VERSION ""

NS_ :

BS_:

BU_: OBC ICM HCU CLM ABM BMS Tester

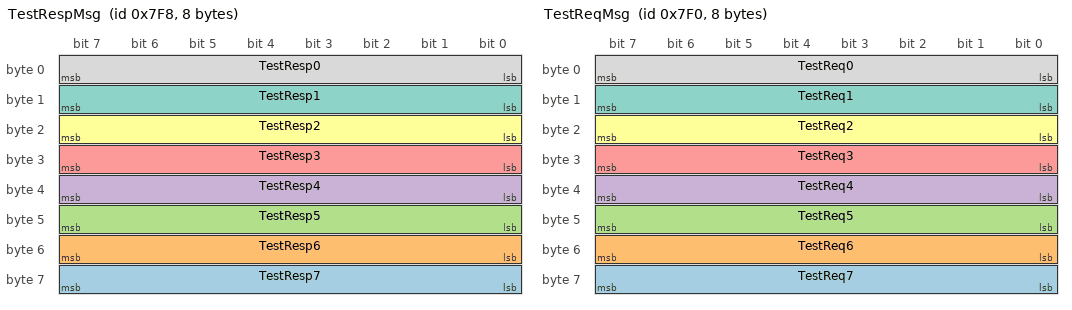
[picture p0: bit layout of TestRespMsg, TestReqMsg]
BO_ 2040 TestRespMsg: 8 BMS
 SG_ TestResp7 : 63|8@0+ (1,0) [0|0] ""  Tester
 SG_ TestResp6 : 55|8@0+ (1,0) [0|0] ""  Tester
 SG_ TestResp5 : 47|8@0+ (1,0) [0|0] ""  Tester
 SG_ TestResp4 : 39|8@0+ (1,0) [0|0] ""  Tester
 SG_ TestResp3 : 31|8@0+ (1,0) [0|0] ""  Tester
 SG_ TestResp2 : 23|8@0+ (1,0) [0|0] ""  Tester
 SG_ TestResp1 : 15|8@0+ (1,0) [0|0] ""  Tester
 SG_ TestResp0 : 7|8@0+ (1,0) [0|0] ""  Tester

BO_ 2032 TestReqMsg: 8 Tester
 SG_ TestReq7 : 63|8@0+ (1,0) [0|0] ""  BMS
 SG_ TestReq6 : 55|8@0+ (1,0) [0|0] ""  BMS
 SG_ TestReq5 : 47|8@0+ (1,0) [0|0] ""  BMS
 SG_ TestReq4 : 39|8@0+ (1,0) [0|0] ""  BMS
 SG_ TestReq3 : 31|8@0+ (1,0) [0|0] ""  BMS
 SG_ TestReq2 : 23|8@0+ (1,0) [0|0] ""  BMS
 SG_ TestReq1 : 15|8@0+ (1,0) [0|0] ""  BMS
 SG_ TestReq0 : 7|8@0+ (1,0) [0|0] ""  BMS

BO_ 1072 ICM_1: 8 Vector__XXX
 SG_ TotalOdometer_km : 43|20@0+ (1,0) [0|999999] "km"  BMS
 SG_ BatteryVoltage : 23|8@0+ (0.1,0) [0|25.4] "V"  BMS

BO_ 800 ABM_1: 4 Vector__XXX
 SG_ CrashOutputSts : 31|8@0+ (1,0) [0|255] ""  BMS
 SG_ ABM_1_CheckSum : 23|8@0+ (1,0) [0|255] ""  BMS
 SG_ ABM_1_MessageCounter : 15|4@0+ (1,0) [0|15] ""  BMS

BO_ 1333 CLM_2: 8 Vector__XXX
 SG_ ExternalTemperatureRaw_C : 55|8@0+ (0.5,-40) [-40|85] "C"  BMS
 SG_ ExternalTemperatureFailSts_GS : 33|2@0+ (1,0) [0|3] ""  BMS

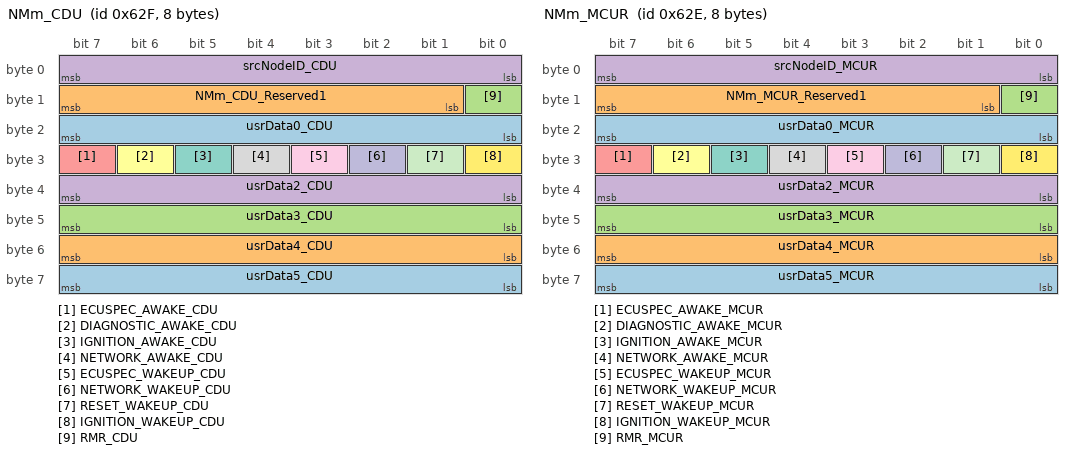
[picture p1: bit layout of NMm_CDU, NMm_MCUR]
BO_ 1583 NMm_CDU: 8 Vector__XXX
 SG_ usrData5_CDU : 63|8@0+ (1,0) [0|255] ""  BMS
 SG_ usrData4_CDU : 55|8@0+ (1,0) [0|255] ""  BMS
 SG_ usrData3_CDU : 47|8@0+ (1,0) [0|255] ""  BMS
 SG_ usrData2_CDU : 39|8@0+ (1,0) [0|255] ""  BMS
 SG_ ECUSPEC_AWAKE_CDU : 31|1@0+ (1,0) [0|1] ""  BMS
 SG_ DIAGNOSTIC_AWAKE_CDU : 30|1@0+ (1,0) [0|1] ""  BMS
 SG_ IGNITION_AWAKE_CDU : 29|1@0+ (1,0) [0|1] ""  BMS
 SG_ NETWORK_AWAKE_CDU : 28|1@0+ (1,0) [0|1] ""  BMS
 SG_ ECUSPEC_WAKEUP_CDU : 27|1@0+ (1,0) [0|1] ""  BMS
 SG_ NETWORK_WAKEUP_CDU : 26|1@0+ (1,0) [0|1] ""  BMS
 SG_ RESET_WAKEUP_CDU : 25|1@0+ (1,0) [0|1] ""  BMS
 SG_ IGNITION_WAKEUP_CDU : 24|1@0+ (1,0) [0|1] ""  BMS
 SG_ usrData0_CDU : 23|8@0+ (1,0) [0|255] ""  BMS
 SG_ NMm_CDU_Reserved1 : 15|7@0+ (1,0) [0|127] ""  BMS
 SG_ RMR_CDU : 8|1@0+ (1,0) [0|1] ""  BMS
 SG_ srcNodeID_CDU : 7|8@0+ (1,0) [0|255] ""  BMS

BO_ 1582 NMm_MCUR: 8 Vector__XXX
 SG_ usrData5_MCUR : 63|8@0+ (1,0) [0|255] ""  BMS
 SG_ usrData4_MCUR : 55|8@0+ (1,0) [0|255] ""  BMS
 SG_ usrData3_MCUR : 47|8@0+ (1,0) [0|255] ""  BMS
 SG_ usrData2_MCUR : 39|8@0+ (1,0) [0|255] ""  BMS
 SG_ ECUSPEC_AWAKE_MCUR : 31|1@0+ (1,0) [0|1] ""  BMS
 SG_ DIAGNOSTIC_AWAKE_MCUR : 30|1@0+ (1,0) [0|1] ""  BMS
 SG_ IGNITION_AWAKE_MCUR : 29|1@0+ (1,0) [0|1] ""  BMS
 SG_ NETWORK_AWAKE_MCUR : 28|1@0+ (1,0) [0|1] ""  BMS
 SG_ ECUSPEC_WAKEUP_MCUR : 27|1@0+ (1,0) [0|1] ""  BMS
 SG_ NETWORK_WAKEUP_MCUR : 26|1@0+ (1,0) [0|1] ""  BMS
 SG_ RESET_WAKEUP_MCUR : 25|1@0+ (1,0) [0|1] ""  BMS
 SG_ IGNITION_WAKEUP_MCUR : 24|1@0+ (1,0) [0|1] ""  BMS
 SG_ usrData0_MCUR : 23|8@0+ (1,0) [0|255] ""  BMS
 SG_ NMm_MCUR_Reserved1 : 15|7@0+ (1,0) [0|127] ""  BMS
 SG_ RMR_MCUR : 8|1@0+ (1,0) [0|1] ""  BMS
 SG_ srcNodeID_MCUR : 7|8@0+ (1,0) [0|255] ""  BMS

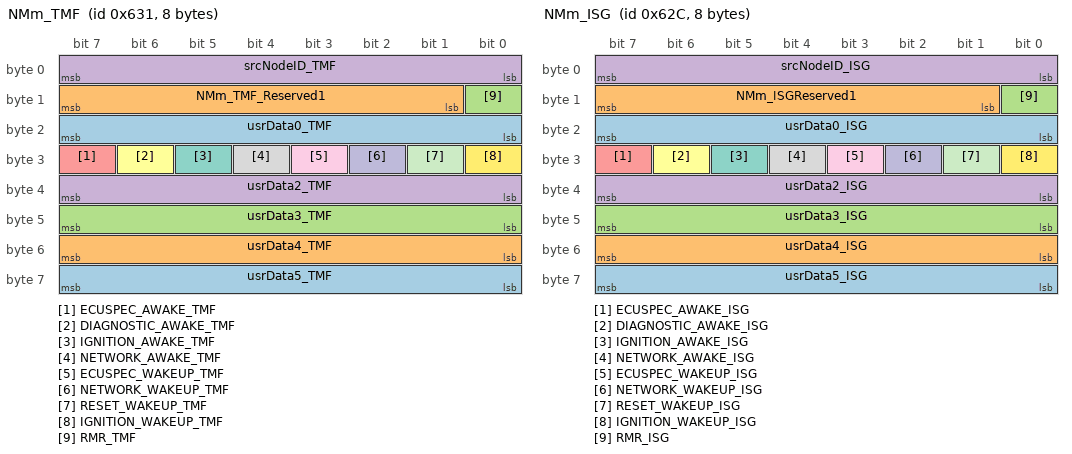
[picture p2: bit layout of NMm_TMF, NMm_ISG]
BO_ 1585 NMm_TMF: 8 Vector__XXX
 SG_ usrData5_TMF : 63|8@0+ (1,0) [0|255] ""  BMS
 SG_ usrData4_TMF : 55|8@0+ (1,0) [0|255] ""  BMS
 SG_ usrData3_TMF : 47|8@0+ (1,0) [0|255] ""  BMS
 SG_ usrData2_TMF : 39|8@0+ (1,0) [0|255] ""  BMS
 SG_ ECUSPEC_AWAKE_TMF : 31|1@0+ (1,0) [0|1] ""  BMS
 SG_ DIAGNOSTIC_AWAKE_TMF : 30|1@0+ (1,0) [0|1] ""  BMS
 SG_ IGNITION_AWAKE_TMF : 29|1@0+ (1,0) [0|1] ""  BMS
 SG_ NETWORK_AWAKE_TMF : 28|1@0+ (1,0) [0|1] ""  BMS
 SG_ ECUSPEC_WAKEUP_TMF : 27|1@0+ (1,0) [0|1] ""  BMS
 SG_ NETWORK_WAKEUP_TMF : 26|1@0+ (1,0) [0|1] ""  BMS
 SG_ RESET_WAKEUP_TMF : 25|1@0+ (1,0) [0|1] ""  BMS
 SG_ IGNITION_WAKEUP_TMF : 24|1@0+ (1,0) [0|1] ""  BMS
 SG_ usrData0_TMF : 23|8@0+ (1,0) [0|255] ""  BMS
 SG_ NMm_TMF_Reserved1 : 15|7@0+ (1,0) [0|127] ""  BMS
 SG_ RMR_TMF : 8|1@0+ (1,0) [0|1] ""  BMS
 SG_ srcNodeID_TMF : 7|8@0+ (1,0) [0|255] ""  BMS

BO_ 1580 NMm_ISG: 8 Vector__XXX
 SG_ usrData5_ISG : 63|8@0+ (1,0) [0|255] ""  BMS
 SG_ usrData4_ISG : 55|8@0+ (1,0) [0|255] ""  BMS
 SG_ usrData3_ISG : 47|8@0+ (1,0) [0|255] ""  BMS
 SG_ usrData2_ISG : 39|8@0+ (1,0) [0|255] ""  BMS
 SG_ ECUSPEC_AWAKE_ISG : 31|1@0+ (1,0) [0|1] ""  BMS
 SG_ DIAGNOSTIC_AWAKE_ISG : 30|1@0+ (1,0) [0|1] ""  BMS
 SG_ IGNITION_AWAKE_ISG : 29|1@0+ (1,0) [0|1] ""  BMS
 SG_ NETWORK_AWAKE_ISG : 28|1@0+ (1,0) [0|1] ""  BMS
 SG_ ECUSPEC_WAKEUP_ISG : 27|1@0+ (1,0) [0|1] ""  BMS
 SG_ NETWORK_WAKEUP_ISG : 26|1@0+ (1,0) [0|1] ""  BMS
 SG_ RESET_WAKEUP_ISG : 25|1@0+ (1,0) [0|1] ""  BMS
 SG_ IGNITION_WAKEUP_ISG : 24|1@0+ (1,0) [0|1] ""  BMS
 SG_ usrData0_ISG : 23|8@0+ (1,0) [0|255] ""  BMS
 SG_ NMm_ISGReserved1 : 15|7@0+ (1,0) [0|127] ""  BMS
 SG_ RMR_ISG : 8|1@0+ (1,0) [0|1] ""  BMS
 SG_ srcNodeID_ISG : 7|8@0+ (1,0) [0|255] ""  BMS

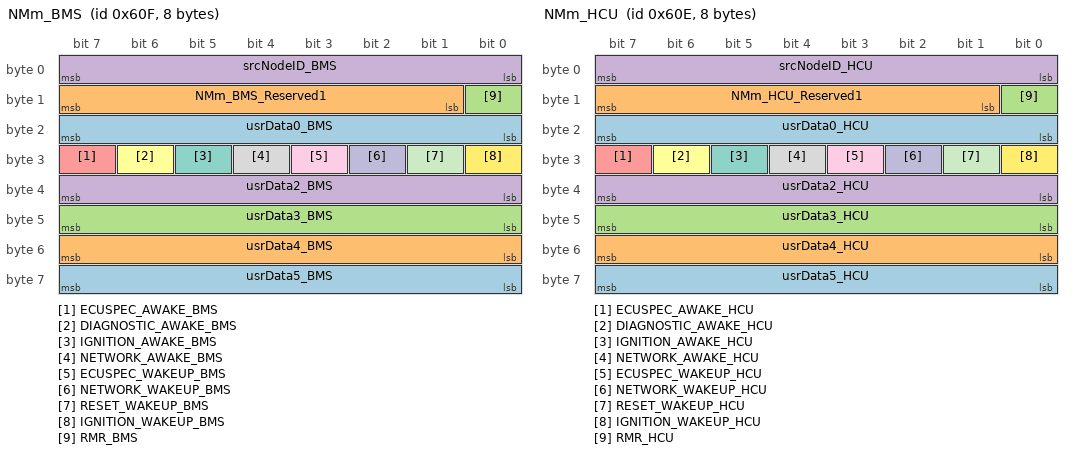
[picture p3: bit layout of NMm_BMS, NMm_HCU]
BO_ 1551 NMm_BMS: 8 BMS
 SG_ usrData5_BMS : 63|8@0+ (1,0) [0|255] "" Vector__XXX
 SG_ usrData4_BMS : 55|8@0+ (1,0) [0|255] "" Vector__XXX
 SG_ usrData3_BMS : 47|8@0+ (1,0) [0|255] "" Vector__XXX
 SG_ usrData2_BMS : 39|8@0+ (1,0) [0|255] "" Vector__XXX
 SG_ ECUSPEC_AWAKE_BMS : 31|1@0+ (1,0) [0|1] "" Vector__XXX
 SG_ DIAGNOSTIC_AWAKE_BMS : 30|1@0+ (1,0) [0|1] "" Vector__XXX
 SG_ IGNITION_AWAKE_BMS : 29|1@0+ (1,0) [0|1] "" Vector__XXX
 SG_ NETWORK_AWAKE_BMS : 28|1@0+ (1,0) [0|1] "" Vector__XXX
 SG_ ECUSPEC_WAKEUP_BMS : 27|1@0+ (1,0) [0|1] "" Vector__XXX
 SG_ NETWORK_WAKEUP_BMS : 26|1@0+ (1,0) [0|1] "" Vector__XXX
 SG_ RESET_WAKEUP_BMS : 25|1@0+ (1,0) [0|1] "" Vector__XXX
 SG_ IGNITION_WAKEUP_BMS : 24|1@0+ (1,0) [0|1] "" Vector__XXX
 SG_ usrData0_BMS : 23|8@0+ (1,0) [0|255] "" Vector__XXX
 SG_ NMm_BMS_Reserved1 : 15|7@0+ (1,0) [0|127] "" Vector__XXX
 SG_ RMR_BMS : 8|1@0+ (1,0) [0|1] "" Vector__XXX
 SG_ srcNodeID_BMS : 7|8@0+ (1,0) [0|255] "" Vector__XXX

BO_ 1550 NMm_HCU: 8 Vector__XXX
 SG_ usrData5_HCU : 63|8@0+ (1,0) [0|255] ""  BMS
 SG_ usrData4_HCU : 55|8@0+ (1,0) [0|255] ""  BMS
 SG_ usrData3_HCU : 47|8@0+ (1,0) [0|255] ""  BMS
 SG_ usrData2_HCU : 39|8@0+ (1,0) [0|255] ""  BMS
 SG_ ECUSPEC_AWAKE_HCU : 31|1@0+ (1,0) [0|1] ""  BMS
 SG_ DIAGNOSTIC_AWAKE_HCU : 30|1@0+ (1,0) [0|1] ""  BMS
 SG_ IGNITION_AWAKE_HCU : 29|1@0+ (1,0) [0|1] ""  BMS
 SG_ NETWORK_AWAKE_HCU : 28|1@0+ (1,0) [0|1] ""  BMS
 SG_ ECUSPEC_WAKEUP_HCU : 27|1@0+ (1,0) [0|1] ""  BMS
 SG_ NETWORK_WAKEUP_HCU : 26|1@0+ (1,0) [0|1] ""  BMS
 SG_ RESET_WAKEUP_HCU : 25|1@0+ (1,0) [0|1] ""  BMS
 SG_ IGNITION_WAKEUP_HCU : 24|1@0+ (1,0) [0|1] ""  BMS
 SG_ usrData0_HCU : 23|8@0+ (1,0) [0|255] ""  BMS
 SG_ NMm_HCU_Reserved1 : 15|7@0+ (1,0) [0|127] ""  BMS
 SG_ RMR_HCU : 8|1@0+ (1,0) [0|1] ""  BMS
 SG_ srcNodeID_HCU : 7|8@0+ (1,0) [0|255] ""  BMS

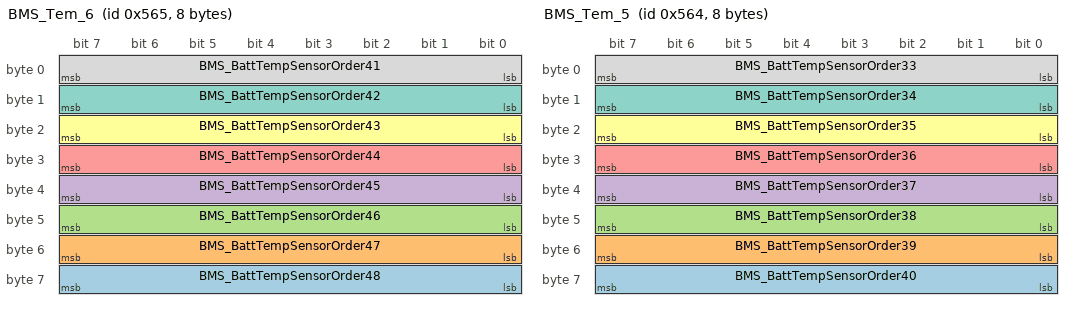
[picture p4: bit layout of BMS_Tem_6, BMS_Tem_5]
BO_ 1381 BMS_Tem_6: 8 BMS
 SG_ BMS_BattTempSensorOrder48 : 63|8@0+ (1,-40) [-40|213] "oC" Vector__XXX
 SG_ BMS_BattTempSensorOrder47 : 55|8@0+ (1,-40) [-40|213] "oC" Vector__XXX
 SG_ BMS_BattTempSensorOrder46 : 47|8@0+ (1,-40) [-40|213] "oC" Vector__XXX
 SG_ BMS_BattTempSensorOrder45 : 39|8@0+ (1,-40) [-40|213] "oC" Vector__XXX
 SG_ BMS_BattTempSensorOrder44 : 31|8@0+ (1,-40) [-40|213] "oC" Vector__XXX
 SG_ BMS_BattTempSensorOrder43 : 23|8@0+ (1,-40) [-40|213] "oC" Vector__XXX
 SG_ BMS_BattTempSensorOrder42 : 15|8@0+ (1,-40) [-40|213] "oC" Vector__XXX
 SG_ BMS_BattTempSensorOrder41 : 7|8@0+ (1,-40) [-40|213] "oC" Vector__XXX

BO_ 1380 BMS_Tem_5: 8 BMS
 SG_ BMS_BattTempSensorOrder40 : 63|8@0+ (1,-40) [-40|213] "oC" Vector__XXX
 SG_ BMS_BattTempSensorOrder39 : 55|8@0+ (1,-40) [-40|213] "oC" Vector__XXX
 SG_ BMS_BattTempSensorOrder38 : 47|8@0+ (1,-40) [-40|213] "oC" Vector__XXX
 SG_ BMS_BattTempSensorOrder37 : 39|8@0+ (1,-40) [-40|213] "oC" Vector__XXX
 SG_ BMS_BattTempSensorOrder36 : 31|8@0+ (1,-40) [-40|213] "oC" Vector__XXX
 SG_ BMS_BattTempSensorOrder35 : 23|8@0+ (1,-40) [-40|213] "oC" Vector__XXX
 SG_ BMS_BattTempSensorOrder34 : 15|8@0+ (1,-40) [-40|213] "oC" Vector__XXX
 SG_ BMS_BattTempSensorOrder33 : 7|8@0+ (1,-40) [-40|213] "oC" Vector__XXX

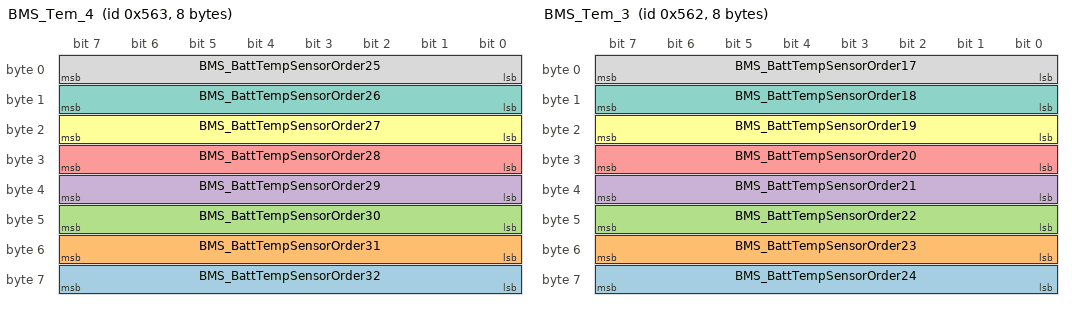
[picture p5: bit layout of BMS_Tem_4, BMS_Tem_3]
BO_ 1379 BMS_Tem_4: 8 BMS
 SG_ BMS_BattTempSensorOrder32 : 63|8@0+ (1,-40) [-40|213] "oC" Vector__XXX
 SG_ BMS_BattTempSensorOrder31 : 55|8@0+ (1,-40) [-40|213] "oC" Vector__XXX
 SG_ BMS_BattTempSensorOrder30 : 47|8@0+ (1,-40) [-40|213] "oC" Vector__XXX
 SG_ BMS_BattTempSensorOrder29 : 39|8@0+ (1,-40) [-40|213] "oC" Vector__XXX
 SG_ BMS_BattTempSensorOrder28 : 31|8@0+ (1,-40) [-40|213] "oC" Vector__XXX
 SG_ BMS_BattTempSensorOrder27 : 23|8@0+ (1,-40) [-40|213] "oC" Vector__XXX
 SG_ BMS_BattTempSensorOrder26 : 15|8@0+ (1,-40) [-40|213] "oC" Vector__XXX
 SG_ BMS_BattTempSensorOrder25 : 7|8@0+ (1,-40) [-40|213] "oC" Vector__XXX

BO_ 1378 BMS_Tem_3: 8 BMS
 SG_ BMS_BattTempSensorOrder24 : 63|8@0+ (1,-40) [-40|213] "oC" Vector__XXX
 SG_ BMS_BattTempSensorOrder23 : 55|8@0+ (1,-40) [-40|213] "oC" Vector__XXX
 SG_ BMS_BattTempSensorOrder22 : 47|8@0+ (1,-40) [-40|213] "oC" Vector__XXX
 SG_ BMS_BattTempSensorOrder21 : 39|8@0+ (1,-40) [-40|213] "oC" Vector__XXX
 SG_ BMS_BattTempSensorOrder20 : 31|8@0+ (1,-40) [-40|213] "oC" Vector__XXX
 SG_ BMS_BattTempSensorOrder19 : 23|8@0+ (1,-40) [-40|213] "oC" Vector__XXX
 SG_ BMS_BattTempSensorOrder18 : 15|8@0+ (1,-40) [-40|213] "oC" Vector__XXX
 SG_ BMS_BattTempSensorOrder17 : 7|8@0+ (1,-40) [-40|213] "oC" Vector__XXX

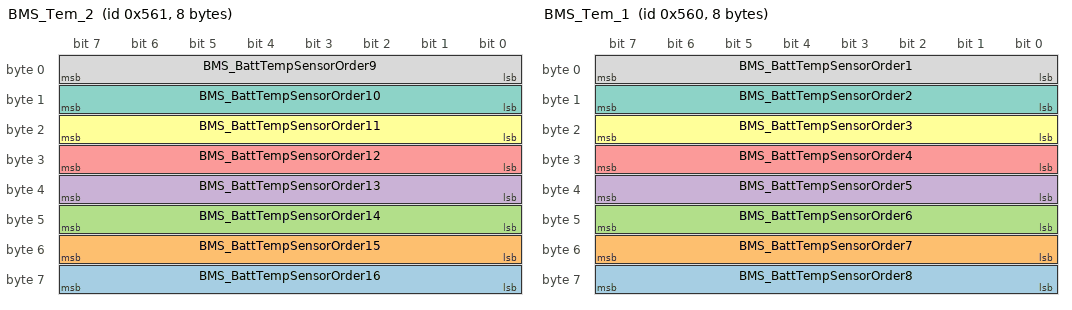
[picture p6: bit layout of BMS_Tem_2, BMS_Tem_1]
BO_ 1377 BMS_Tem_2: 8 BMS
 SG_ BMS_BattTempSensorOrder16 : 63|8@0+ (1,-40) [-40|213] "oC" Vector__XXX
 SG_ BMS_BattTempSensorOrder15 : 55|8@0+ (1,-40) [-40|213] "oC" Vector__XXX
 SG_ BMS_BattTempSensorOrder14 : 47|8@0+ (1,-40) [-40|213] "oC" Vector__XXX
 SG_ BMS_BattTempSensorOrder13 : 39|8@0+ (1,-40) [-40|213] "oC" Vector__XXX
 SG_ BMS_BattTempSensorOrder12 : 31|8@0+ (1,-40) [-40|213] "oC" Vector__XXX
 SG_ BMS_BattTempSensorOrder11 : 23|8@0+ (1,-40) [-40|213] "oC" Vector__XXX
 SG_ BMS_BattTempSensorOrder10 : 15|8@0+ (1,-40) [-40|213] "oC" Vector__XXX
 SG_ BMS_BattTempSensorOrder9 : 7|8@0+ (1,-40) [-40|213] "oC" Vector__XXX

BO_ 1376 BMS_Tem_1: 8 BMS
 SG_ BMS_BattTempSensorOrder8 : 63|8@0+ (1,-40) [-40|213] "oC" Vector__XXX
 SG_ BMS_BattTempSensorOrder7 : 55|8@0+ (1,-40) [-40|213] "oC" Vector__XXX
 SG_ BMS_BattTempSensorOrder6 : 47|8@0+ (1,-40) [-40|213] "oC" Vector__XXX
 SG_ BMS_BattTempSensorOrder5 : 39|8@0+ (1,-40) [-40|213] "oC" Vector__XXX
 SG_ BMS_BattTempSensorOrder4 : 31|8@0+ (1,-40) [-40|213] "oC" Vector__XXX
 SG_ BMS_BattTempSensorOrder3 : 23|8@0+ (1,-40) [-40|213] "oC" Vector__XXX
 SG_ BMS_BattTempSensorOrder2 : 15|8@0+ (1,-40) [-40|213] "oC" Vector__XXX
 SG_ BMS_BattTempSensorOrder1 : 7|8@0+ (1,-40) [-40|213] "oC" Vector__XXX

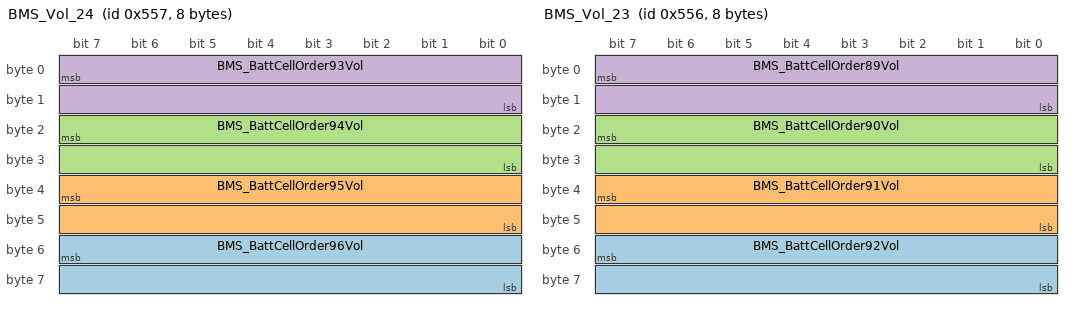
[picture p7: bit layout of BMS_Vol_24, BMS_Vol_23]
BO_ 1367 BMS_Vol_24: 8 BMS
 SG_ BMS_BattCellOrder96Vol : 55|16@0+ (1,0) [0|5000] "mV" Vector__XXX
 SG_ BMS_BattCellOrder95Vol : 39|16@0+ (1,0) [0|5000] "mV" Vector__XXX
 SG_ BMS_BattCellOrder94Vol : 23|16@0+ (1,0) [0|5000] "mV" Vector__XXX
 SG_ BMS_BattCellOrder93Vol : 7|16@0+ (1,0) [0|5000] "mV" Vector__XXX

BO_ 1366 BMS_Vol_23: 8 BMS
 SG_ BMS_BattCellOrder92Vol : 55|16@0+ (1,0) [0|5000] "mV" Vector__XXX
 SG_ BMS_BattCellOrder91Vol : 39|16@0+ (1,0) [0|5000] "mV" Vector__XXX
 SG_ BMS_BattCellOrder90Vol : 23|16@0+ (1,0) [0|5000] "mV" Vector__XXX
 SG_ BMS_BattCellOrder89Vol : 7|16@0+ (1,0) [0|5000] "mV" Vector__XXX

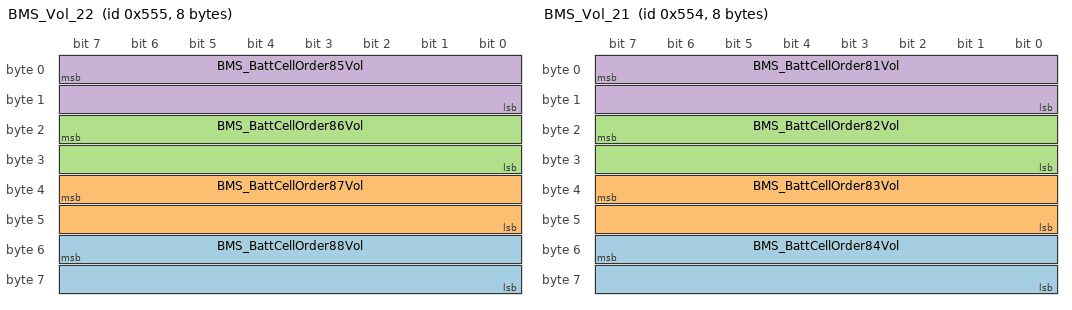
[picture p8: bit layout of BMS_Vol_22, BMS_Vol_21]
BO_ 1365 BMS_Vol_22: 8 BMS
 SG_ BMS_BattCellOrder88Vol : 55|16@0+ (1,0) [0|5000] "mV" Vector__XXX
 SG_ BMS_BattCellOrder87Vol : 39|16@0+ (1,0) [0|5000] "mV" Vector__XXX
 SG_ BMS_BattCellOrder86Vol : 23|16@0+ (1,0) [0|5000] "mV" Vector__XXX
 SG_ BMS_BattCellOrder85Vol : 7|16@0+ (1,0) [0|5000] "mV" Vector__XXX

BO_ 1364 BMS_Vol_21: 8 BMS
 SG_ BMS_BattCellOrder84Vol : 55|16@0+ (1,0) [0|5000] "mV" Vector__XXX
 SG_ BMS_BattCellOrder83Vol : 39|16@0+ (1,0) [0|5000] "mV" Vector__XXX
 SG_ BMS_BattCellOrder82Vol : 23|16@0+ (1,0) [0|5000] "mV" Vector__XXX
 SG_ BMS_BattCellOrder81Vol : 7|16@0+ (1,0) [0|5000] "mV" Vector__XXX

BO_ 1363 BMS_Vol_20: 8 BMS
 SG_ BMS_BattCellOrder80Vol : 55|16@0+ (1,0) [0|5000] "mV" Vector__XXX
 SG_ BMS_BattCellOrder79Vol : 39|16@0+ (1,0) [0|5000] "mV" Vector__XXX
 SG_ BMS_BattCellOrder78Vol : 23|16@0+ (1,0) [0|5000] "mV" Vector__XXX
 SG_ BMS_BattCellOrder77Vol : 7|16@0+ (1,0) [0|5000] "mV" Vector__XXX

BO_ 1362 BMS_Vol_19: 8 BMS
 SG_ BMS_BattCellOrder76Vol : 55|16@0+ (1,0) [0|5000] "mV" Vector__XXX
 SG_ BMS_BattCellOrder75Vol : 39|16@0+ (1,0) [0|5000] "mV" Vector__XXX
 SG_ BMS_BattCellOrder74Vol : 23|16@0+ (1,0) [0|5000] "mV" Vector__XXX
 SG_ BMS_BattCellOrder73Vol : 7|16@0+ (1,0) [0|5000] "mV" Vector__XXX

BO_ 1361 BMS_Vol_18: 8 BMS
 SG_ BMS_BattCellOrder72Vol : 55|16@0+ (1,0) [0|5000] "mV" Vector__XXX
 SG_ BMS_BattCellOrder71Vol : 39|16@0+ (1,0) [0|5000] "mV" Vector__XXX
 SG_ BMS_BattCellOrder70Vol : 23|16@0+ (1,0) [0|5000] "mV" Vector__XXX
 SG_ BMS_BattCellOrder69Vol : 7|16@0+ (1,0) [0|5000] "mV" Vector__XXX

BO_ 1360 BMS_Vol_17: 8 BMS
 SG_ BMS_BattCellOrder68Vol : 55|16@0+ (1,0) [0|5000] "mV" Vector__XXX
 SG_ BMS_BattCellOrder67Vol : 39|16@0+ (1,0) [0|5000] "mV" Vector__XXX
 SG_ BMS_BattCellOrder66Vol : 23|16@0+ (1,0) [0|5000] "mV" Vector__XXX
 SG_ BMS_BattCellOrder65Vol : 7|16@0+ (1,0) [0|5000] "mV" Vector__XXX

BO_ 1359 BMS_Vol_16: 8 BMS
 SG_ BMS_BattCellOrder64Vol : 55|16@0+ (1,0) [0|5000] "mV" Vector__XXX
 SG_ BMS_BattCellOrder63Vol : 39|16@0+ (1,0) [0|5000] "mV" Vector__XXX
 SG_ BMS_BattCellOrder62Vol : 23|16@0+ (1,0) [0|5000] "mV" Vector__XXX
 SG_ BMS_BattCellOrder61Vol : 7|16@0+ (1,0) [0|5000] "mV" Vector__XXX

BO_ 1358 BMS_Vol_15: 8 BMS
 SG_ BMS_BattCellOrder60Vol : 55|16@0+ (1,0) [0|5000] "mV" Vector__XXX
 SG_ BMS_BattCellOrder59Vol : 39|16@0+ (1,0) [0|5000] "mV" Vector__XXX
 SG_ BMS_BattCellOrder58Vol : 23|16@0+ (1,0) [0|5000] "mV" Vector__XXX
 SG_ BMS_BattCellOrder57Vol : 7|16@0+ (1,0) [0|5000] "mV" Vector__XXX

BO_ 1357 BMS_Vol_14: 8 BMS
 SG_ BMS_BattCellOrder56Vol : 55|16@0+ (1,0) [0|5000] "mV" Vector__XXX
 SG_ BMS_BattCellOrder55Vol : 39|16@0+ (1,0) [0|5000] "mV" Vector__XXX
 SG_ BMS_BattCellOrder54Vol : 23|16@0+ (1,0) [0|5000] "mV" Vector__XXX
 SG_ BMS_BattCellOrder53Vol : 7|16@0+ (1,0) [0|5000] "mV" Vector__XXX

BO_ 1356 BMS_Vol_13: 8 BMS
 SG_ BMS_BattCellOrder52Vol : 55|16@0+ (1,0) [0|5000] "mV" Vector__XXX
 SG_ BMS_BattCellOrder51Vol : 39|16@0+ (1,0) [0|5000] "mV" Vector__XXX
 SG_ BMS_BattCellOrder50Vol : 23|16@0+ (1,0) [0|5000] "mV" Vector__XXX
 SG_ BMS_BattCellOrder49Vol : 7|16@0+ (1,0) [0|5000] "mV" Vector__XXX

BO_ 1355 BMS_Vol_12: 8 BMS
 SG_ BMS_BattCellOrder48Vol : 55|16@0+ (1,0) [0|5000] "mV" Vector__XXX
 SG_ BMS_BattCellOrder47Vol : 39|16@0+ (1,0) [0|5000] "mV" Vector__XXX
 SG_ BMS_BattCellOrder46Vol : 23|16@0+ (1,0) [0|5000] "mV" Vector__XXX
 SG_ BMS_BattCellOrder45Vol : 7|16@0+ (1,0) [0|5000] "mV" Vector__XXX

BO_ 1354 BMS_Vol_11: 8 BMS
 SG_ BMS_BattCellOrder44Vol : 55|16@0+ (1,0) [0|5000] "mV" Vector__XXX
 SG_ BMS_BattCellOrder43Vol : 39|16@0+ (1,0) [0|5000] "mV" Vector__XXX
 SG_ BMS_BattCellOrder42Vol : 23|16@0+ (1,0) [0|5000] "mV" Vector__XXX
 SG_ BMS_BattCellOrder41Vol : 7|16@0+ (1,0) [0|5000] "mV" Vector__XXX

BO_ 1353 BMS_Vol_10: 8 BMS
 SG_ BMS_BattCellOrder40Vol : 55|16@0+ (1,0) [0|5000] "mV" Vector__XXX
 SG_ BMS_BattCellOrder39Vol : 39|16@0+ (1,0) [0|5000] "mV" Vector__XXX
 SG_ BMS_BattCellOrder38Vol : 23|16@0+ (1,0) [0|5000] "mV" Vector__XXX
 SG_ BMS_BattCellOrder37Vol : 7|16@0+ (1,0) [0|5000] "mV" Vector__XXX

BO_ 1352 BMS_Vol_9: 8 BMS
 SG_ BMS_BattCellOrder36Vol : 55|16@0+ (1,0) [0|5000] "mV" Vector__XXX
 SG_ BMS_BattCellOrder35Vol : 39|16@0+ (1,0) [0|5000] "mV" Vector__XXX
 SG_ BMS_BattCellOrder34Vol : 23|16@0+ (1,0) [0|5000] "mV" Vector__XXX
 SG_ BMS_BattCellOrder33Vol : 7|16@0+ (1,0) [0|5000] "mV" Vector__XXX

BO_ 1351 BMS_Vol_8: 8 BMS
 SG_ BMS_BattCellOrder32Vol : 55|16@0+ (1,0) [0|5000] "mV" Vector__XXX
 SG_ BMS_BattCellOrder31Vol : 39|16@0+ (1,0) [0|5000] "mV" Vector__XXX
 SG_ BMS_BattCellOrder30Vol : 23|16@0+ (1,0) [0|5000] "mV" Vector__XXX
 SG_ BMS_BattCellOrder29Vol : 7|16@0+ (1,0) [0|5000] "mV" Vector__XXX

BO_ 1350 BMS_Vol_7: 8 BMS
 SG_ BMS_BattCellOrder28Vol : 55|16@0+ (1,0) [0|5000] "mV" Vector__XXX
 SG_ BMS_BattCellOrder27Vol : 39|16@0+ (1,0) [0|5000] "mV" Vector__XXX
 SG_ BMS_BattCellOrder26Vol : 23|16@0+ (1,0) [0|5000] "mV" Vector__XXX
 SG_ BMS_BattCellOrder25Vol : 7|16@0+ (1,0) [0|5000] "mV" Vector__XXX

BO_ 1349 BMS_Vol_6: 8 BMS
 SG_ BMS_BattCellOrder24Vol : 55|16@0+ (1,0) [0|5000] "mV" Vector__XXX
 SG_ BMS_BattCellOrder23Vol : 39|16@0+ (1,0) [0|5000] "mV" Vector__XXX
 SG_ BMS_BattCellOrder22Vol : 23|16@0+ (1,0) [0|5000] "mV" Vector__XXX
 SG_ BMS_BattCellOrder21Vol : 7|16@0+ (1,0) [0|5000] "mV" Vector__XXX

BO_ 1348 BMS_Vol_5: 8 BMS
 SG_ BMS_BattCellOrder20Vol : 55|16@0+ (1,0) [0|5000] "mV" Vector__XXX
 SG_ BMS_BattCellOrder19Vol : 39|16@0+ (1,0) [0|5000] "mV" Vector__XXX
 SG_ BMS_BattCellOrder18Vol : 23|16@0+ (1,0) [0|5000] "mV" Vector__XXX
 SG_ BMS_BattCellOrder17Vol : 7|16@0+ (1,0) [0|5000] "mV" Vector__XXX

BO_ 1347 BMS_Vol_4: 8 BMS
 SG_ BMS_BattCellOrder16Vol : 55|16@0+ (1,0) [0|5000] "mV" Vector__XXX
 SG_ BMS_BattCellOrder15Vol : 39|16@0+ (1,0) [0|5000] "mV" Vector__XXX
 SG_ BMS_BattCellOrder14Vol : 23|16@0+ (1,0) [0|5000] "mV" Vector__XXX
 SG_ BMS_BattCellOrder13Vol : 7|16@0+ (1,0) [0|5000] "mV" Vector__XXX

BO_ 1346 BMS_Vol_3: 8 BMS
 SG_ BMS_BattCellOrder12Vol : 55|16@0+ (1,0) [0|5000] "mV" Vector__XXX
 SG_ BMS_BattCellOrder11Vol : 39|16@0+ (1,0) [0|5000] "mV" Vector__XXX
 SG_ BMS_BattCellOrder10Vol : 23|16@0+ (1,0) [0|5000] "mV" Vector__XXX
 SG_ BMS_BattCellOrder9Vol : 7|16@0+ (1,0) [0|5000] "mV" Vector__XXX

BO_ 1345 BMS_Vol_2: 8 BMS
 SG_ BMS_BattCellOrder8Vol : 55|16@0+ (1,0) [0|5000] "mV" Vector__XXX
 SG_ BMS_BattCellOrder7Vol : 39|16@0+ (1,0) [0|5000] "mV" Vector__XXX
 SG_ BMS_BattCellOrder6Vol : 23|16@0+ (1,0) [0|5000] "mV" Vector__XXX
 SG_ BMS_BattCellOrder5Vol : 7|16@0+ (1,0) [0|5000] "mV" Vector__XXX

BO_ 1344 BMS_Vol_1: 8 BMS
 SG_ BMS_BattCellOrder4Vol : 55|16@0+ (1,0) [0|5000] "mV" Vector__XXX
 SG_ BMS_BattCellOrder3Vol : 39|16@0+ (1,0) [0|5000] "mV" Vector__XXX
 SG_ BMS_BattCellOrder2Vol : 23|16@0+ (1,0) [0|5000] "mV" Vector__XXX
 SG_ BMS_BattCellOrder1Vol : 7|16@0+ (1,0) [0|5000] "mV" Vector__XXX

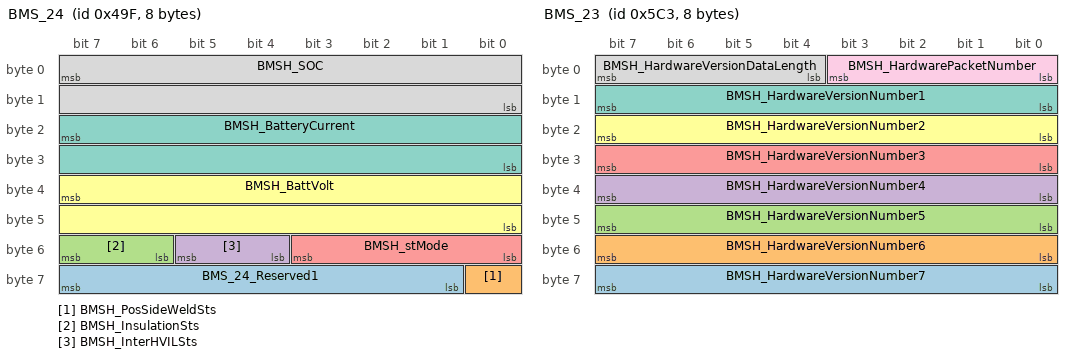
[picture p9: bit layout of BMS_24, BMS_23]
BO_ 1183 BMS_24: 8 BMS
 SG_ BMS_24_Reserved1 : 63|7@0+ (1,0) [0|0] "" Vector__XXX
 SG_ BMSH_PosSideWeldSts : 56|1@0+ (1,0) [0|1] "" Vector__XXX
 SG_ BMSH_InsulationSts : 55|2@0+ (1,0) [0|3] "" Vector__XXX
 SG_ BMSH_InterHVILSts : 53|2@0+ (1,0) [0|3] "" Vector__XXX
 SG_ BMSH_stMode : 51|4@0+ (1,0) [0|15] "" Vector__XXX
 SG_ BMSH_BattVolt : 39|16@0+ (0.05,0) [0|1000] "V" Vector__XXX
 SG_ BMSH_BatteryCurrent : 23|16@0+ (0.05,0) [-600|600] "A" Vector__XXX
 SG_ BMSH_SOC : 7|16@0+ (0.01,0) [0|100] "%" Vector__XXX

BO_ 1475 BMS_23: 8 BMS
 SG_ BMSH_HardwareVersionNumber7 : 63|8@0+ (1,0) [0|255] "" Vector__XXX
 SG_ BMSH_HardwareVersionNumber6 : 55|8@0+ (1,0) [0|255] "" Vector__XXX
 SG_ BMSH_HardwareVersionNumber5 : 47|8@0+ (1,0) [0|255] "" Vector__XXX
 SG_ BMSH_HardwareVersionNumber4 : 39|8@0+ (1,0) [0|255] "" Vector__XXX
 SG_ BMSH_HardwareVersionNumber3 : 31|8@0+ (1,0) [0|255] "" Vector__XXX
 SG_ BMSH_HardwareVersionNumber2 : 23|8@0+ (1,0) [0|255] "" Vector__XXX
 SG_ BMSH_HardwareVersionNumber1 : 15|8@0+ (1,0) [0|255] "" Vector__XXX
 SG_ BMSH_HardwareVersionDataLength : 7|4@0+ (1,0) [0|15] "" Vector__XXX
 SG_ BMSH_HardwarePacketNumber : 3|4@0+ (1,0) [0|15] "" Vector__XXX

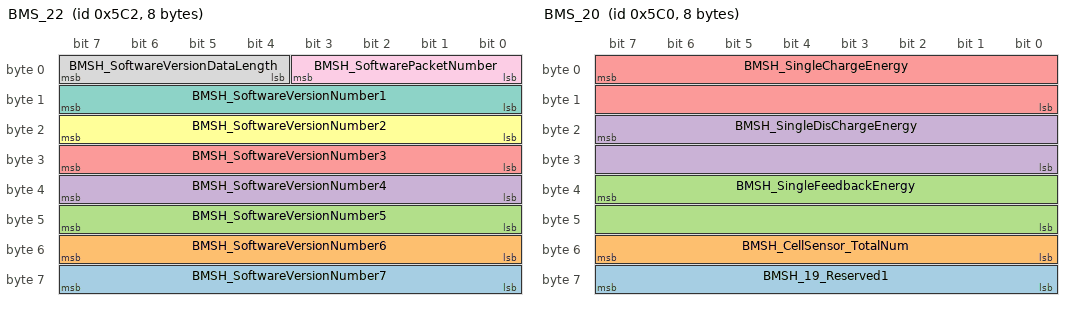
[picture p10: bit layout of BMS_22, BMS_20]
BO_ 1474 BMS_22: 8 BMS
 SG_ BMSH_SoftwareVersionNumber7 : 63|8@0+ (1,0) [0|255] "" Vector__XXX
 SG_ BMSH_SoftwareVersionNumber6 : 55|8@0+ (1,0) [0|255] "" Vector__XXX
 SG_ BMSH_SoftwareVersionNumber5 : 47|8@0+ (1,0) [0|255] "" Vector__XXX
 SG_ BMSH_SoftwareVersionNumber4 : 39|8@0+ (1,0) [0|255] "" Vector__XXX
 SG_ BMSH_SoftwareVersionNumber3 : 31|8@0+ (1,0) [0|255] "" Vector__XXX
 SG_ BMSH_SoftwareVersionNumber2 : 23|8@0+ (1,0) [0|255] "" Vector__XXX
 SG_ BMSH_SoftwareVersionNumber1 : 15|8@0+ (1,0) [0|255] "" Vector__XXX
 SG_ BMSH_SoftwareVersionDataLength : 7|4@0+ (1,0) [0|15] "" Vector__XXX
 SG_ BMSH_SoftwarePacketNumber : 3|4@0+ (1,0) [0|15] "" Vector__XXX

BO_ 1473 BMS_21: 8 BMS
 SG_ BMSH_BPTotalDischargeEnergy : 47|24@0+ (0.1,0) [0|1677721] "KWH" Vector__XXX
 SG_ BMSH_TotalFeedbackEnergy : 19|20@0+ (0.1,0) [0|104857] "KWH" Vector__XXX
 SG_ BMSH_TotalChargeEnergy : 7|20@0+ (0.1,0) [0|104857] "KWH" Vector__XXX

BO_ 1472 BMS_20: 8 BMS
 SG_ BMSH_19_Reserved1 : 63|8@0+ (1,0) [0|0] "" Vector__XXX
 SG_ BMSH_CellSensor_TotalNum : 55|8@0+ (1,0) [0|255] "" Vector__XXX
 SG_ BMSH_SingleFeedbackEnergy : 39|16@0+ (0.01,0) [0|655] "KWH" Vector__XXX
 SG_ BMSH_SingleDisChargeEnergy : 23|16@0+ (0.01,0) [0|655] "KWH" Vector__XXX
 SG_ BMSH_SingleChargeEnergy : 7|16@0+ (0.01,0) [0|655] "KWH" Vector__XXX

BO_ 1458 BMS_19: 8 BMS
 SG_ BMS_DTCOrder6 : 39|24@0+ (1,0) [0|0] "" Vector__XXX
 SG_ BMS_DTCOrder5 : 7|24@0+ (1,0) [0|0] "" Vector__XXX

BO_ 1457 BMS_18: 8 BMS
 SG_ BMS_DTCOrder4 : 39|24@0+ (1,0) [0|0] "" Vector__XXX
 SG_ BMS_DTCOrder3 : 7|24@0+ (1,0) [0|0] "" Vector__XXX

BO_ 1456 BMS_17: 8 BMS
 SG_ BMS_DTCTotalNum : 63|8@0+ (1,0) [0|255] "" Vector__XXX
 SG_ BMS_DTCOrder2 : 39|24@0+ (1,0) [0|0] "" Vector__XXX
 SG_ BMS_DTCOrder1 : 7|24@0+ (1,0) [0|0] "" Vector__XXX

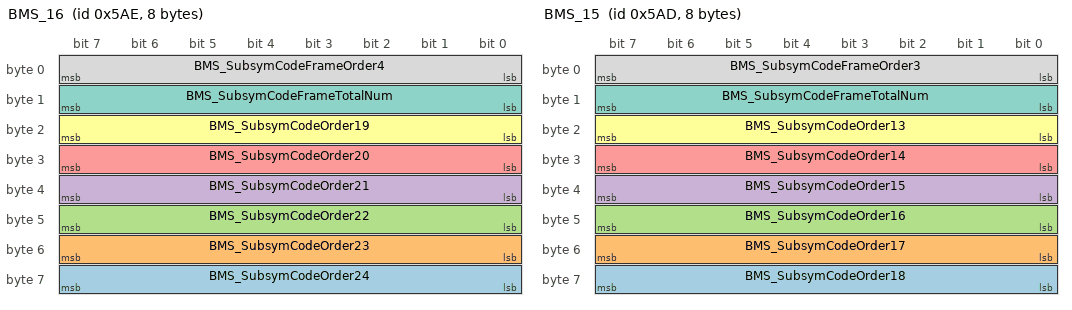
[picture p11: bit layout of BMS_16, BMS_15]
BO_ 1454 BMS_16: 8 BMS
 SG_ BMS_SubsymCodeOrder24 : 63|8@0+ (1,0) [0|255] "" Vector__XXX
 SG_ BMS_SubsymCodeOrder23 : 55|8@0+ (1,0) [0|255] "" Vector__XXX
 SG_ BMS_SubsymCodeOrder22 : 47|8@0+ (1,0) [0|255] "" Vector__XXX
 SG_ BMS_SubsymCodeOrder21 : 39|8@0+ (1,0) [0|255] "" Vector__XXX
 SG_ BMS_SubsymCodeOrder20 : 31|8@0+ (1,0) [0|255] "" Vector__XXX
 SG_ BMS_SubsymCodeOrder19 : 23|8@0+ (1,0) [0|255] "" Vector__XXX
 SG_ BMS_SubsymCodeFrameTotalNum : 15|8@0+ (1,0) [0|255] "" Vector__XXX
 SG_ BMS_SubsymCodeFrameOrder4 : 7|8@0+ (1,0) [0|255] "" Vector__XXX

BO_ 1453 BMS_15: 8 BMS
 SG_ BMS_SubsymCodeOrder18 : 63|8@0+ (1,0) [0|255] "" Vector__XXX
 SG_ BMS_SubsymCodeOrder17 : 55|8@0+ (1,0) [0|255] "" Vector__XXX
 SG_ BMS_SubsymCodeOrder16 : 47|8@0+ (1,0) [0|255] "" Vector__XXX
 SG_ BMS_SubsymCodeOrder15 : 39|8@0+ (1,0) [0|255] "" Vector__XXX
 SG_ BMS_SubsymCodeOrder14 : 31|8@0+ (1,0) [0|255] "" Vector__XXX
 SG_ BMS_SubsymCodeOrder13 : 23|8@0+ (1,0) [0|255] "" Vector__XXX
 SG_ BMS_SubsymCodeFrameTotalNum : 15|8@0+ (1,0) [0|255] "" Vector__XXX
 SG_ BMS_SubsymCodeFrameOrder3 : 7|8@0+ (1,0) [0|255] "" Vector__XXX

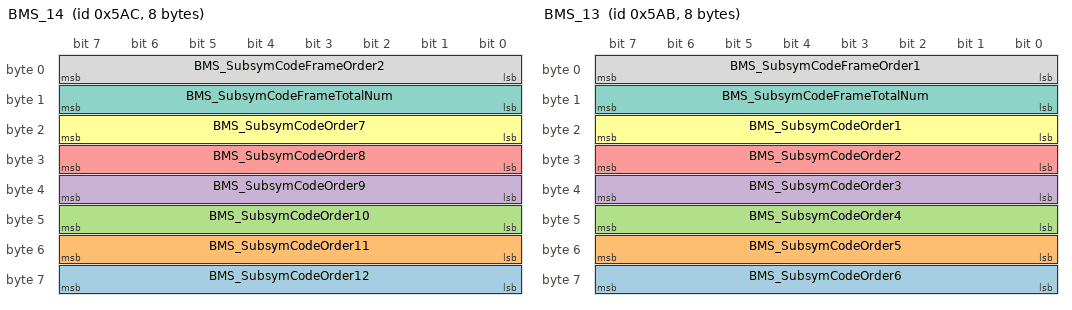
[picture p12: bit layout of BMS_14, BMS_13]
BO_ 1452 BMS_14: 8 BMS
 SG_ BMS_SubsymCodeOrder12 : 63|8@0+ (1,0) [0|255] "" Vector__XXX
 SG_ BMS_SubsymCodeOrder11 : 55|8@0+ (1,0) [0|255] "" Vector__XXX
 SG_ BMS_SubsymCodeOrder10 : 47|8@0+ (1,0) [0|255] "" Vector__XXX
 SG_ BMS_SubsymCodeOrder9 : 39|8@0+ (1,0) [0|255] "" Vector__XXX
 SG_ BMS_SubsymCodeOrder8 : 31|8@0+ (1,0) [0|255] "" Vector__XXX
 SG_ BMS_SubsymCodeOrder7 : 23|8@0+ (1,0) [0|255] "" Vector__XXX
 SG_ BMS_SubsymCodeFrameTotalNum : 15|8@0+ (1,0) [0|255] "" Vector__XXX
 SG_ BMS_SubsymCodeFrameOrder2 : 7|8@0+ (1,0) [0|255] "" Vector__XXX

BO_ 1451 BMS_13: 8 BMS
 SG_ BMS_SubsymCodeOrder6 : 63|8@0+ (1,0) [0|255] "" Vector__XXX
 SG_ BMS_SubsymCodeOrder5 : 55|8@0+ (1,0) [0|255] "" Vector__XXX
 SG_ BMS_SubsymCodeOrder4 : 47|8@0+ (1,0) [0|255] "" Vector__XXX
 SG_ BMS_SubsymCodeOrder3 : 39|8@0+ (1,0) [0|255] "" Vector__XXX
 SG_ BMS_SubsymCodeOrder2 : 31|8@0+ (1,0) [0|255] "" Vector__XXX
 SG_ BMS_SubsymCodeOrder1 : 23|8@0+ (1,0) [0|255] "" Vector__XXX
 SG_ BMS_SubsymCodeFrameTotalNum : 15|8@0+ (1,0) [0|255] "" Vector__XXX
 SG_ BMS_SubsymCodeFrameOrder1 : 7|8@0+ (1,0) [0|255] "" Vector__XXX

BO_ 1450 BMS_12: 8 BMS
 SG_ BMSH_BalanceActive : 63|1@0+ (1,0) [0|1] "" Vector__XXX
 SG_ BMSH_Battery_Uniformity : 62|1@0+ (1,0) [0|1] "" Vector__XXX
 SG_ BMSH_StoredEnergySys : 61|1@0+ (1,0) [0|1] "" Vector__XXX
 SG_ BMSH_Charge_Over : 60|1@0+ (1,0) [0|1] "" Vector__XXX
 SG_ BMSH_HVILcuitFailure : 59|1@0+ (1,0) [0|1] "" Vector__XXX
 SG_ BMSH_Battery_Mismatching : 58|1@0+ (1,0) [0|1] "" Vector__XXX
 SG_ BMSH_BatteryTempLightSts : 57|2@0+ (1,0) [0|3] "" Vector__XXX
 SG_ BMSH_Charge_Over_Current : 55|2@0+ (1,0) [0|0] "" Vector__XXX
 SG_ BMSH_Discharge_Over_Current : 53|2@0+ (1,0) [0|0] "" Vector__XXX
 SG_ BMSH_IsocircuitFailure : 51|2@0+ (1,0) [0|3] "" Vector__XXX
 SG_ BMSH_Cell_Voltage_Uniformity : 49|2@0+ (1,0) [0|1] "" Vector__XXX
 SG_ BMSH_LowSOC : 47|2@0+ (1,0) [0|3] "" Vector__XXX
 SG_ BMSH_CellUnderVol : 45|2@0+ (1,0) [0|3] "" Vector__XXX
 SG_ BMSH_CellOverVol : 43|2@0+ (1,0) [0|3] "" Vector__XXX
 SG_ BMSH_OverSOC : 41|2@0+ (1,0) [0|3] "" Vector__XXX
 SG_ BMSH_Battery_Under_Voltage : 24|2@0+ (1,0) [0|3] "" Vector__XXX
 SG_ BMSH_Battery_Over_Voltage : 37|2@0+ (1,0) [0|3] "" Vector__XXX
 SG_ BMSH_Low_Temperature : 35|2@0+ (1,0) [0|3] "" Vector__XXX
 SG_ BMSH_Over_Temperature : 33|2@0+ (1,0) [0|3] "" Vector__XXX
 SG_ BMSH_PacksubsystemVolt : 23|15@0+ (0.1,0) [0|2000] "V" Vector__XXX
 SG_ BMSH_SOC_Jump : 24|1@0+ (1,0) [0|1] "" Vector__XXX
 SG_ BMSH_PacksubsystemCurrent : 7|15@0+ (0.1,0) [-1000|1000] "A" Vector__XXX
 SG_ BMSH_TempUniformity : 8|1@0+ (1,0) [0|1] "" Vector__XXX

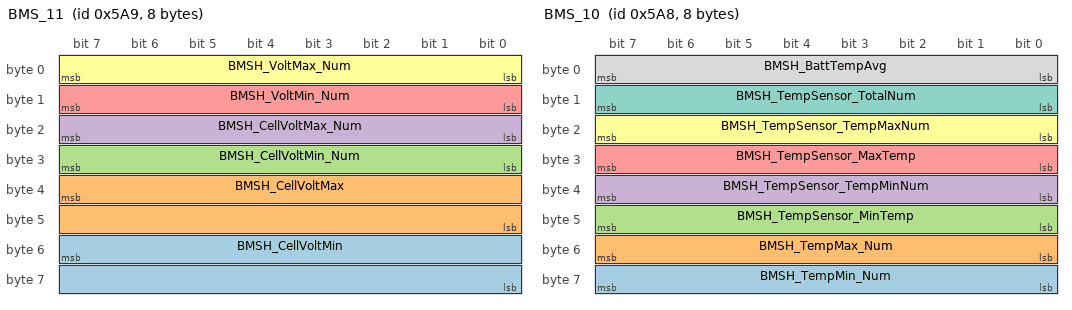
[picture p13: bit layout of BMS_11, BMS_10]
BO_ 1449 BMS_11: 8 BMS
 SG_ BMSH_CellVoltMin : 55|16@0+ (1,0) [0|5000] "mV" Vector__XXX
 SG_ BMSH_CellVoltMax : 39|16@0+ (1,0) [0|5000] "mV" Vector__XXX
 SG_ BMSH_CellVoltMin_Num : 31|8@0+ (1,0) [0|255] "" Vector__XXX
 SG_ BMSH_CellVoltMax_Num : 23|8@0+ (1,0) [0|255] "" Vector__XXX
 SG_ BMSH_VoltMin_Num : 15|8@0+ (1,0) [0|255] "" Vector__XXX
 SG_ BMSH_VoltMax_Num : 7|8@0+ (1,0) [0|255] "" Vector__XXX

BO_ 1448 BMS_10: 8 BMS
 SG_ BMSH_TempMin_Num : 63|8@0+ (1,0) [0|255] "" Vector__XXX
 SG_ BMSH_TempMax_Num : 55|8@0+ (1,0) [0|255] "" Vector__XXX
 SG_ BMSH_TempSensor_MinTemp : 47|8@0+ (1,-40) [-40|123] "oC" Vector__XXX
 SG_ BMSH_TempSensor_TempMinNum : 39|8@0+ (1,0) [0|255] "" Vector__XXX
 SG_ BMSH_TempSensor_MaxTemp : 31|8@0+ (1,-40) [-40|123] "oC" Vector__XXX
 SG_ BMSH_TempSensor_TempMaxNum : 23|8@0+ (1,0) [0|255] "" Vector__XXX
 SG_ BMSH_TempSensor_TotalNum : 15|8@0+ (1,0) [0|255] "" Vector__XXX
 SG_ BMSH_BattTempAvg : 7|8@0+ (1,-40) [-40|123] "oC" Vector__XXX

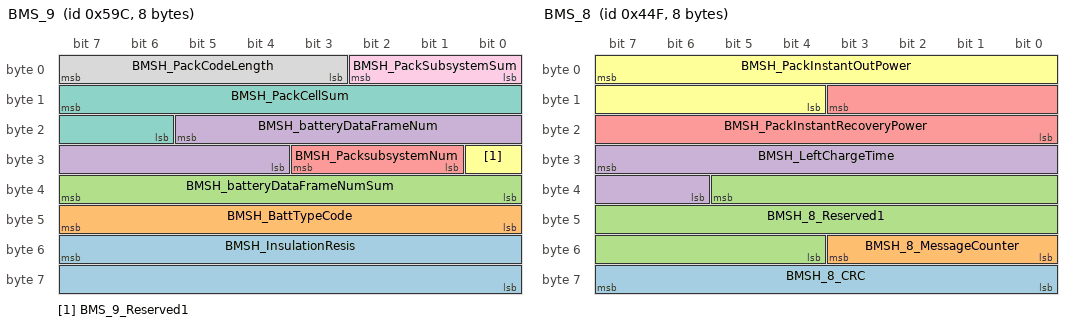
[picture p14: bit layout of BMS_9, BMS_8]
BO_ 1436 BMS_9: 8 BMS
 SG_ BMSH_InsulationResis : 55|16@0+ (1,0) [0|65533] "10k" Vector__XXX
 SG_ BMSH_BattTypeCode : 47|8@0+ (1,0) [0|255] "" Vector__XXX
 SG_ BMSH_batteryDataFrameNumSum : 39|8@0+ (1,0) [0|255] "" Vector__XXX
 SG_ BMSH_batteryDataFrameNum : 21|10@0+ (1,0) [0|1023] "" Vector__XXX
 SG_ BMSH_PacksubsystemNum : 27|3@0+ (1,0) [0|7] "" Vector__XXX
 SG_ BMS_9_Reserved1 : 24|1@0+ (1,0) [0|0] "" Vector__XXX
 SG_ BMSH_PackCellSum : 15|10@0+ (1,0) [0|1023] "" Vector__XXX
 SG_ BMSH_PackCodeLength : 7|5@0+ (1,0) [0|31] "" Vector__XXX
 SG_ BMSH_PackSubsystemSum : 2|3@0+ (1,0) [0|7] "" Vector__XXX

BO_ 1103 BMS_8: 8 BMS
 SG_ BMSH_8_CRC : 63|8@0+ (1,0) [0|255] "" Vector__XXX
 SG_ BMSH_8_MessageCounter : 51|4@0+ (1,0) [0|15] "" Vector__XXX
 SG_ BMSH_8_Reserved1 : 37|18@0+ (1,0) [0|0] "" Vector__XXX
 SG_ BMSH_LeftChargeTime : 31|10@0+ (1,0) [0|1024] "Minute" Vector__XXX
 SG_ BMSH_PackInstantRecoveryPower : 11|12@0+ (0.1,0) [0|320] "KW" Vector__XXX
 SG_ BMSH_PackInstantOutPower : 7|12@0+ (0.1,0) [0|320] "KW" Vector__XXX

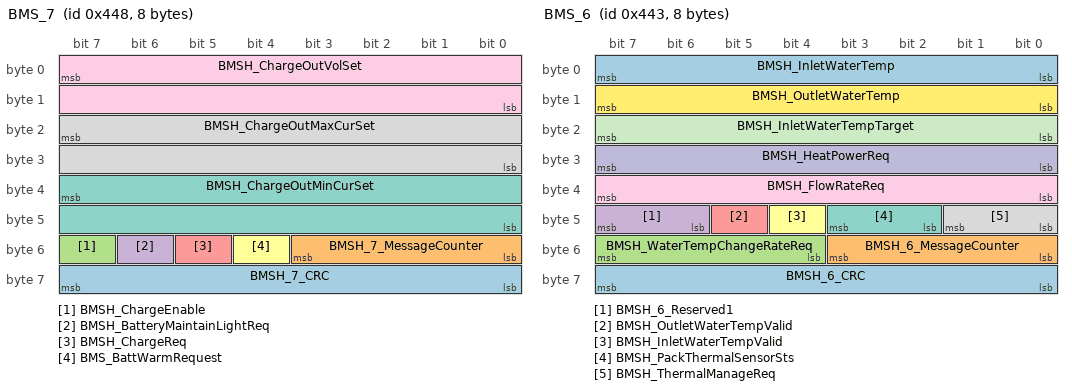
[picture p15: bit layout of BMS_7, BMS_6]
BO_ 1096 BMS_7: 8 BMS
 SG_ BMSH_7_CRC : 63|8@0+ (1,0) [0|255] "" Vector__XXX
 SG_ BMSH_7_MessageCounter : 51|4@0+ (1,0) [0|15] "" Vector__XXX
 SG_ BMSH_ChargeEnable : 55|1@0+ (1,0) [0|1] "" Vector__XXX
 SG_ BMSH_BatteryMaintainLightReq : 54|1@0+ (1,0) [0|1] "" Vector__XXX
 SG_ BMSH_ChargeReq : 53|1@0+ (1,0) [0|1] "" Vector__XXX
 SG_ BMS_BattWarmRequest : 52|1@0+ (1,0) [0|1] "" Vector__XXX
 SG_ BMSH_ChargeOutMinCurSet : 39|16@0+ (0.05,0) [0|50] "A" Vector__XXX
 SG_ BMSH_ChargeOutMaxCurSet : 23|16@0+ (0.05,0) [0|50] "A" Vector__XXX
 SG_ BMSH_ChargeOutVolSet : 7|16@0+ (0.05,0) [0|1000] "V" Vector__XXX

BO_ 1091 BMS_6: 8 BMS
 SG_ BMSH_6_CRC : 63|8@0+ (1,0) [0|255] "" Vector__XXX
 SG_ BMSH_6_MessageCounter : 51|4@0+ (1,0) [0|15] "" Vector__XXX
 SG_ BMSH_WaterTempChangeRateReq : 55|4@0+ (1,0) [0|15] "oC/s" Vector__XXX
 SG_ BMSH_6_Reserved1 : 47|2@0+ (1,0) [0|0] "" Vector__XXX
 SG_ BMSH_OutletWaterTempValid : 45|1@0+ (1,0) [0|1] "" Vector__XXX
 SG_ BMSH_InletWaterTempValid : 44|1@0+ (1,0) [0|1] "" Vector__XXX
 SG_ BMSH_PackThermalSensorSts : 43|2@0+ (1,0) [0|3] "" Vector__XXX
 SG_ BMSH_ThermalManageReq : 41|2@0+ (1,0) [0|3] "" Vector__XXX
 SG_ BMSH_FlowRateReq : 39|8@0+ (0.1,0) [0|20] "L/S" Vector__XXX
 SG_ BMSH_HeatPowerReq : 31|8@0+ (0.04,0) [0|10.16] "kw" Vector__XXX
 SG_ BMSH_InletWaterTempTarget : 23|8@0+ (1,-40) [-40|125] "oC" Vector__XXX
 SG_ BMSH_OutletWaterTemp : 15|8@0+ (1,-40) [-40|125] "oC" Vector__XXX
 SG_ BMSH_InletWaterTemp : 7|8@0+ (1,-40) [-40|125] "oC" Vector__XXX

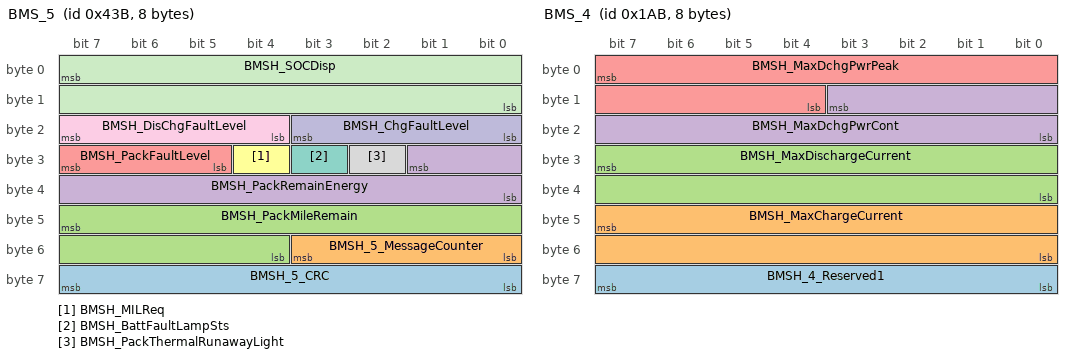
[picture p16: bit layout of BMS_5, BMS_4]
BO_ 1083 BMS_5: 8 BMS
 SG_ BMSH_5_CRC : 63|8@0+ (1,0) [0|255] "" Vector__XXX
 SG_ BMSH_5_MessageCounter : 51|4@0+ (1,0) [0|15] "" Vector__XXX
 SG_ BMSH_PackMileRemain : 47|12@0+ (0.1,0) [0|400] "KM" Vector__XXX
 SG_ BMSH_PackRemainEnergy : 25|10@0+ (0.1,0) [0|100] "KwH" Vector__XXX
 SG_ BMSH_PackFaultLevel : 31|3@0+ (1,0) [0|7] "" Vector__XXX
 SG_ BMSH_MILReq : 28|1@0+ (1,0) [0|1] "" Vector__XXX
 SG_ BMSH_BattFaultLampSts : 27|1@0+ (1,0) [0|1] "" Vector__XXX
 SG_ BMSH_PackThermalRunawayLight : 26|1@0+ (1,0) [0|1] "" Vector__XXX
 SG_ BMSH_DisChgFaultLevel : 23|4@0+ (1,0) [0|15] "" Vector__XXX
 SG_ BMSH_ChgFaultLevel : 19|4@0+ (1,0) [0|15] "" Vector__XXX
 SG_ BMSH_SOCDisp : 7|16@0+ (0.01,0) [0|100] "%" Vector__XXX

BO_ 427 BMS_4: 8 BMS
 SG_ BMSH_4_Reserved1 : 63|8@0+ (1,0) [0|0] "" Vector__XXX
 SG_ BMSH_MaxChargeCurrent : 47|16@0+ (0.05,-1600) [-1600|1600] "A" Vector__XXX
 SG_ BMSH_MaxDischargeCurrent : 31|16@0+ (0.05,-1600) [-1600|1600] "A" Vector__XXX
 SG_ BMSH_MaxDchgPwrCont : 11|12@0+ (0.1,0) [0|320] "KW" Vector__XXX
 SG_ BMSH_MaxDchgPwrPeak : 7|12@0+ (0.1,0) [0|320] "KW" Vector__XXX

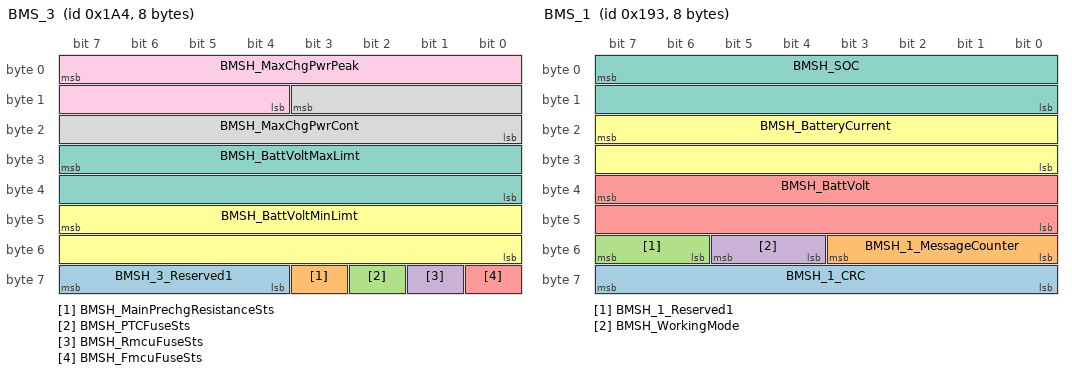
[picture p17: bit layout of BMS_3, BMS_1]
BO_ 420 BMS_3: 8 BMS
 SG_ BMSH_3_Reserved1 : 63|4@0+ (1,0) [0|0] "" Vector__XXX
 SG_ BMSH_MainPrechgResistanceSts : 59|1@0+ (1,0) [0|1] "" Vector__XXX
 SG_ BMSH_PTCFuseSts : 58|1@0+ (1,0) [0|1] "" Vector__XXX
 SG_ BMSH_RmcuFuseSts : 57|1@0+ (1,0) [0|1] "" Vector__XXX
 SG_ BMSH_FmcuFuseSts : 56|1@0+ (1,0) [0|1] "" Vector__XXX
 SG_ BMSH_BattVoltMinLimt : 47|16@0+ (0.05,0) [0|1000] "V" Vector__XXX
 SG_ BMSH_BattVoltMaxLimt : 31|16@0+ (0.05,0) [0|1000] "V" Vector__XXX
 SG_ BMSH_MaxChgPwrCont : 11|12@0+ (0.1,0) [0|320] "KW" Vector__XXX
 SG_ BMSH_MaxChgPwrPeak : 7|12@0+ (0.1,0) [0|320] "KW" Vector__XXX

BO_ 411 BMS_2: 8 BMS
 SG_ BMSH_2_CRC : 63|8@0+ (1,0) [0|255] "" Vector__XXX
 SG_ BMSH_2_MessageCounter : 51|4@0+ (1,0) [0|15] "" Vector__XXX
 SG_ BMSH_BookSetReq : 55|1@0+ (1,0) [0|1] "" Vector__XXX
 SG_ BMSH_PTCRelayWeldSts : 54|1@0+ (1,0) [0|1] "" Vector__XXX
 SG_ BMSH_CHGPrechargeWeldSts : 53|1@0+ (1,0) [0|1] "" Vector__XXX
 SG_ BMSH_PreChargeWeldSts : 52|1@0+ (1,0) [0|1] "" Vector__XXX
 SG_ BMSH_NegSideWeldSts : 47|1@0+ (1,0) [0|1] "" Vector__XXX
 SG_ BMSH_PosSideWeldSts : 46|1@0+ (1,0) [0|1] "" Vector__XXX
 SG_ BMSH_PTCRelaySts : 45|1@0+ (1,0) [0|1] "" Vector__XXX
 SG_ BMSH_CHGPrechargeRelaySts : 44|1@0+ (1,0) [0|1] "" Vector__XXX
 SG_ BMSH_PrechargeRelaySts : 43|1@0+ (1,0) [0|1] "" Vector__XXX
 SG_ BMSH_NegMainRelaySts : 42|1@0+ (1,0) [0|1] "" Vector__XXX
 SG_ BMSH_PosMainRelaySts : 41|1@0+ (1,0) [0|1] "" Vector__XXX
 SG_ BMSH_IntelligentChargeReq : 40|1@0+ (1,0) [0|1] "" Vector__XXX
 SG_ BMSH_OBCPrechgSt : 39|3@0+ (1,0) [0|7] "" Vector__XXX
 SG_ BMSH_MainPrechgSt : 36|3@0+ (1,0) [0|7] "" Vector__XXX
 SG_ BMSH_InsulationSts : 33|2@0+ (1,0) [0|3] "" Vector__XXX
 SG_ BMSH_VehicleHVILSts : 31|2@0+ (1,0) [0|3] "" Vector__XXX
 SG_ BMSH_InterHVILSts : 29|2@0+ (1,0) [0|3] "" Vector__XXX
 SG_ BMSH_stMode : 27|4@0+ (1,0) [0|15] "" Vector__XXX
 SG_ BMSH_SOH : 23|8@0+ (1,0) [0|100] "%" Vector__XXX
 SG_ BMSH_HVBusVolt : 7|16@0+ (0.05,0) [0|1000] "V" Vector__XXX

BO_ 403 BMS_1: 8 BMS
 SG_ BMSH_1_CRC : 63|8@0+ (1,0) [0|255] "" Vector__XXX
 SG_ BMSH_1_MessageCounter : 51|4@0+ (1,0) [0|15] "" Vector__XXX
 SG_ BMSH_1_Reserved1 : 55|2@0+ (1,0) [0|0] "" Vector__XXX
 SG_ BMSH_WorkingMode : 53|2@0+ (1,0) [0|3] "" Vector__XXX
 SG_ BMSH_BattVolt : 39|16@0+ (0.05,0) [0|1000] "V" Vector__XXX
 SG_ BMSH_BatteryCurrent : 23|16@0+ (0.05,0) [-600|600] "A" Vector__XXX
 SG_ BMSH_SOC : 7|16@0+ (0.01,0) [0|100] "%" Vector__XXX

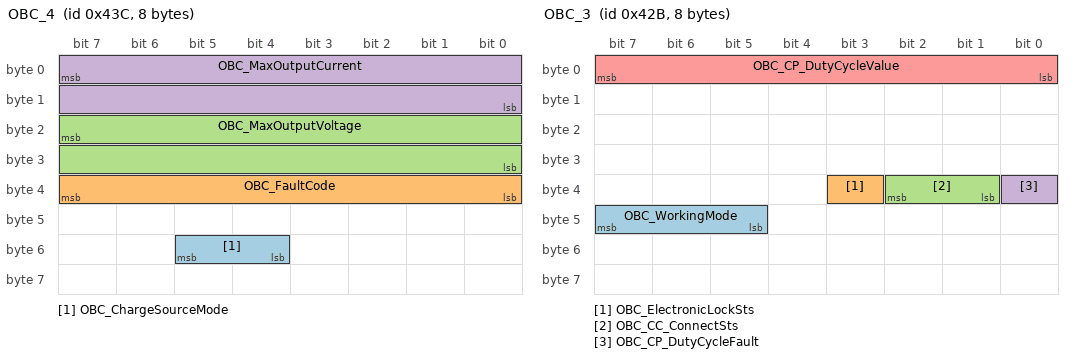
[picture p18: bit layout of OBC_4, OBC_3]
BO_ 1084 OBC_4: 8 Vector__XXX
 SG_ OBC_ChargeSourceMode : 53|2@0+ (1,0) [0|0] ""  BMS
 SG_ OBC_FaultCode : 39|8@0+ (1,0) [0|255] ""  BMS
 SG_ OBC_MaxOutputVoltage : 23|16@0+ (0.05,0) [0|1000] "V"  BMS
 SG_ OBC_MaxOutputCurrent : 7|16@0+ (0.05,0) [0|400] "A"  BMS

BO_ 1067 OBC_3: 8 Vector__XXX
 SG_ OBC_WorkingMode : 47|3@0+ (1,0) [0|7] ""  BMS
 SG_ OBC_ElectronicLockSts : 35|1@0+ (1,0) [0|1] ""  BMS
 SG_ OBC_CC_ConnectSts : 34|2@0+ (1,0) [0|3] ""  BMS
 SG_ OBC_CP_DutyCycleFault : 32|1@0+ (1,0) [0|1] ""  BMS
 SG_ OBC_CP_DutyCycleValue : 7|8@0+ (1,0) [0|100] "%"  BMS

BO_ 1064 OBC_2: 8 Vector__XXX
 SG_ OBC_KL30_UnderVolt : 55|1@0+ (1,0) [0|1] ""  BMS
 SG_ OBC_InputVolt : 23|16@0+ (0.05,0) [0|1000] "V"  BMS
 SG_ OBC_InputCurr : 7|16@0+ (0.05,0) [0|400] "A"  BMS

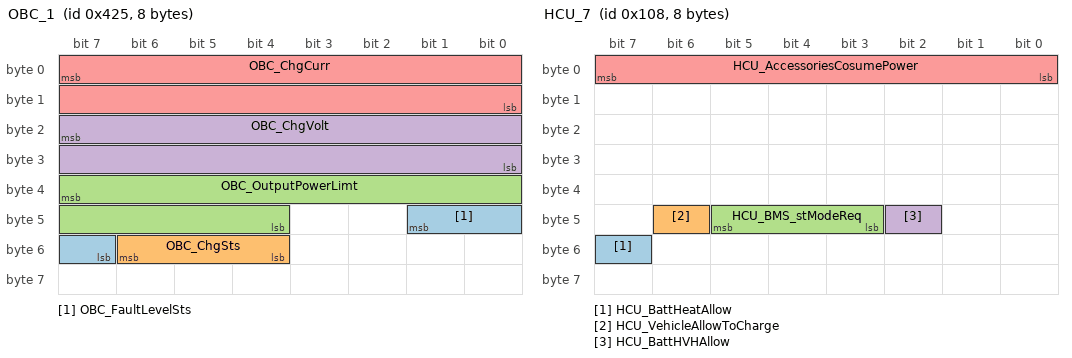
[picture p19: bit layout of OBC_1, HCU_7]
BO_ 1061 OBC_1: 8 Vector__XXX
 SG_ OBC_FaultLevelSts : 41|3@0+ (1,0) [0|7] ""  BMS
 SG_ OBC_ChgSts : 54|3@0+ (1,0) [0|7] ""  BMS
 SG_ OBC_OutputPowerLimt : 39|12@0+ (0.1,0) [0|400] "KW"  BMS
 SG_ OBC_ChgVolt : 23|16@0+ (0.05,0) [0|1000] "V"  BMS
 SG_ OBC_ChgCurr : 7|16@0+ (0.05,0) [0|400] "A"  BMS

BO_ 1048 DCDC_1: 8 Vector__XXX
 SG_ DCDC_LvSideCurr : 31|9@0+ (1,0) [0|510] "A"  BMS
 SG_ DCDC_LvSideVolt : 7|8@0+ (0.1,0) [0|25.3] "V"  BMS

BO_ 808 TMR_3: 8 Vector__XXX
 SG_ TMR_VoltageHV : 12|10@0+ (1,0) [0|1021] "V"  BMS
 SG_ TMR_CurrentHV : 7|11@0+ (1,-1023) [-1023|1021] "A"  BMS

BO_ 371 TMR_1: 8 Vector__XXX
 SG_ TMR_State : 55|4@0+ (1,0) [0|15] ""  BMS

BO_ 795 TMF_3: 8 Vector__XXX
 SG_ TMF_UdcAct : 12|10@0+ (1,0) [0|1021] "V"  BMS
 SG_ TMF_IdcAct : 7|11@0+ (1,-1023) [-1023|1021] "A"  BMS

BO_ 348 TMF_1: 8 Vector__XXX
 SG_ TMF_ModeSt : 55|4@0+ (1,0) [0|15] ""  BMS

BO_ 786 ISGF_3: 8 Vector__XXX
 SG_ ISGF_UdcAct : 12|10@0+ (1,0) [0|1021] "V"  BMS
 SG_ ISGF_IdcAct : 7|11@0+ (1,-1023) [-1023|1021] "A"  BMS

BO_ 326 ISGF_1: 8 Vector__XXX
 SG_ ISGF_ModeSt : 55|4@0+ (1,0) [0|15] ""  BMS

BO_ 264 HCU_7: 8 Vector__XXX
 SG_ HCU_BattHeatAllow : 55|1@0+ (1,0) [0|1] ""  BMS
 SG_ HCU_VehicleAllowToCharge : 46|1@0+ (1,0) [0|1] ""  BMS
 SG_ HCU_BMS_stModeReq : 45|3@0+ (1,0) [0|7] ""  BMS
 SG_ HCU_BattHVHAllow : 42|1@0+ (1,0) [0|1] ""  BMS
 SG_ HCU_AccessoriesCosumePower : 7|8@0+ (0.1,0) [0|20] "KW"  BMS

CM_ SG_ 800 CrashOutputSts "Crash????????bit???????:
????????????????!dou!??????????????????????????1.????????????????!dou!?????????????00001100";
CM_ SG_ 800 ABM_1_CheckSum "((Byte0+Byte1+Byte3) AND 0xFF) XOR 0xFF
Note: Details Please refer to specification??Standard Specification for CAN Data Link Layer_v1.1??section 2.3.3";
CM_ SG_ 800 ABM_1_MessageCounter "Rolling message counter(the maximum value of Alive counter is 15)
Note: Details Please refer to specification??Standard Specification for CAN Data Link Layer_v1.1??section 2.3.1";
CM_ SG_ 1333 ExternalTemperatureRaw_C "Raw external temperature
Invalid: When external temperature is fail, the signal value is 0xFF.";
CM_ SG_ 1333 ExternalTemperatureFailSts_GS "??????1??????
???!mao!????????????";
CM_ SG_ 1583 ECUSPEC_AWAKE_CDU "ECU keeps the network awake for ECU-define reasons for which communication is needed";
CM_ SG_ 1583 DIAGNOSTIC_AWAKE_CDU "ECU needs communication for diagnostic purpose and keeps network awake.";
CM_ SG_ 1583 IGNITION_AWAKE_CDU "ECU can?t release communication because ignition (KL15) is turn on, or KLR is turned on";
CM_ SG_ 1583 NETWORK_AWAKE_CDU "ECU keeps the network awake due to the CAN message received from the network";
CM_ SG_ 1583 ECUSPEC_WAKEUP_CDU "ECU was in ??power off??, ??Bus Sleep??, ??Pre-pare Bus Sleep?? or ??Ready Sleep?? mode or ??awake?? and re-started by ECU specific reason (e.g. pressed Button, timer, etc.)";
CM_ SG_ 1583 NETWORK_WAKEUP_CDU "ECU was in ??Power off??, ??Bus Sleep??, ??Pre-pare Bus Sleep?? or ??Ready Sleep?? Mode and then re-started by a network communication.";
CM_ SG_ 1583 RESET_WAKEUP_CDU "If ECU was already awake, in ??Prepare Bus Sleep?? or ??Ready Sleep?? mode and re-started by an internal or an external reset.";
CM_ SG_ 1583 IGNITION_WAKEUP_CDU "ECU was ??power off?? or ??Bus sleep?? mode and started by ignition switch";
CM_ SG_ 1583 RMR_CDU "If set to 1 to force the network management of all other nodes on the bus into the re-peat message state.";
CM_ SG_ 1582 ECUSPEC_AWAKE_MCUR "ECU keeps the network awake for ECU-define reasons for which communication is needed";
CM_ SG_ 1582 DIAGNOSTIC_AWAKE_MCUR "ECU needs communication for diagnostic purpose and keeps network awake.";
CM_ SG_ 1582 IGNITION_AWAKE_MCUR "ECU can?t release communication because ignition (KL15) is turn on, or KLR is turned on";
CM_ SG_ 1582 NETWORK_AWAKE_MCUR "ECU keeps the network awake due to the CAN message received from the network";
CM_ SG_ 1582 ECUSPEC_WAKEUP_MCUR "ECU was in ??power off??, ??Bus Sleep??, ??Pre-pare Bus Sleep?? or ??Ready Sleep?? mode or ??awake?? and re-started by ECU specific reason (e.g. pressed Button, timer, etc.)";
CM_ SG_ 1582 NETWORK_WAKEUP_MCUR "ECU was in ??Power off??, ??Bus Sleep??, ??Pre-pare Bus Sleep?? or ??Ready Sleep?? Mode and then re-started by a network communication.";
CM_ SG_ 1582 RESET_WAKEUP_MCUR "If ECU was already awake, in ??Prepare Bus Sleep?? or ??Ready Sleep?? mode and re-started by an internal or an external reset.";
CM_ SG_ 1582 IGNITION_WAKEUP_MCUR "ECU was ??power off?? or ??Bus sleep?? mode and started by ignition switch";
CM_ SG_ 1582 RMR_MCUR "If set to 1 to force the network management of all other nodes on the bus into the re-peat message state.";
CM_ SG_ 1585 ECUSPEC_AWAKE_TMF "ECU keeps the network awake for ECU-define reasons for which communication is needed";
CM_ SG_ 1585 DIAGNOSTIC_AWAKE_TMF "ECU needs communication for diagnostic purpose and keeps network awake.";
CM_ SG_ 1585 IGNITION_AWAKE_TMF "ECU can?t release communication because ignition (KL15) is turn on, or KLR is turned on";
CM_ SG_ 1585 NETWORK_AWAKE_TMF "ECU keeps the network awake due to the CAN message received from the network";
CM_ SG_ 1585 ECUSPEC_WAKEUP_TMF "ECU was in ??power off??, ??Bus Sleep??, ??Pre-pare Bus Sleep?? or ??Ready Sleep?? mode or ??awake?? and re-started by ECU specific reason (e.g. pressed Button, timer, etc.)";
CM_ SG_ 1585 NETWORK_WAKEUP_TMF "ECU was in ??Power off??, ??Bus Sleep??, ??Pre-pare Bus Sleep?? or ??Ready Sleep?? Mode and then re-started by a network communication.";
CM_ SG_ 1585 RESET_WAKEUP_TMF "If ECU was already awake, in ??Prepare Bus Sleep?? or ??Ready Sleep?? mode and re-started by an internal or an external reset.";
CM_ SG_ 1585 IGNITION_WAKEUP_TMF "ECU was ??power off?? or ??Bus sleep?? mode and started by ignition switch";
CM_ SG_ 1585 RMR_TMF "If set to 1 to force the network management of all other nodes on the bus into the re-peat message state.";
CM_ SG_ 1580 ECUSPEC_AWAKE_ISG "ECU keeps the network awake for ECU-define reasons for which communication is needed";
CM_ SG_ 1580 DIAGNOSTIC_AWAKE_ISG "ECU needs communication for diagnostic purpose and keeps network awake.";
CM_ SG_ 1580 IGNITION_AWAKE_ISG "ECU can?t release communication because ignition (KL15) is turn on, or KLR is turned on";
CM_ SG_ 1580 NETWORK_AWAKE_ISG "ECU keeps the network awake due to the CAN message received from the network";
CM_ SG_ 1580 ECUSPEC_WAKEUP_ISG "ECU was in ??power off??, ??Bus Sleep??, ??Pre-pare Bus Sleep?? or ??Ready Sleep?? mode or ??awake?? and re-started by ECU specific reason (e.g. pressed Button, timer, etc.)";
CM_ SG_ 1580 NETWORK_WAKEUP_ISG "ECU was in ??Power off??, ??Bus Sleep??, ??Pre-pare Bus Sleep?? or ??Ready Sleep?? Mode and then re-started by a network communication.";
CM_ SG_ 1580 RESET_WAKEUP_ISG "If ECU was already awake, in ??Prepare Bus Sleep?? or ??Ready Sleep?? mode and re-started by an internal or an external reset.";
CM_ SG_ 1580 IGNITION_WAKEUP_ISG "ECU was ??power off?? or ??Bus sleep?? mode and started by ignition switch";
CM_ SG_ 1580 RMR_ISG "If set to 1 to force the network management of all other nodes on the bus into the re-peat message state.";
CM_ SG_ 1551 ECUSPEC_AWAKE_BMS "ECU keeps the network awake for ECU-define reasons for which communication is needed";
CM_ SG_ 1551 DIAGNOSTIC_AWAKE_BMS "ECU needs communication for diagnostic purpose and keeps network awake.";
CM_ SG_ 1551 IGNITION_AWAKE_BMS "ECU can?t release communication because ignition (KL15) is turn on, or KLR is turned on";
CM_ SG_ 1551 NETWORK_AWAKE_BMS "ECU keeps the network awake due to the CAN message received from the network";
CM_ SG_ 1551 ECUSPEC_WAKEUP_BMS "ECU was in ??power off??, ??Bus Sleep??, ??Pre-pare Bus Sleep?? or ??Ready Sleep?? mode or ??awake?? and re-started by ECU specific reason (e.g. pressed Button, timer, etc.)";
CM_ SG_ 1551 NETWORK_WAKEUP_BMS "ECU was in ??Power off??, ??Bus Sleep??, ??Pre-pare Bus Sleep?? or ??Ready Sleep?? Mode and then re-started by a network communication.";
CM_ SG_ 1551 RESET_WAKEUP_BMS "If ECU was already awake, in ??Prepare Bus Sleep?? or ??Ready Sleep?? mode and re-started by an internal or an external reset.";
CM_ SG_ 1551 IGNITION_WAKEUP_BMS "ECU was ??power off?? or ??Bus sleep?? mode and started by ignition switch";
CM_ SG_ 1551 RMR_BMS "If set to 1 to force the network management of all other nodes on the bus into the re-peat message state.";
CM_ SG_ 1550 ECUSPEC_AWAKE_HCU "ECU keeps the network awake for ECU-define reasons for which communication is needed";
CM_ SG_ 1550 DIAGNOSTIC_AWAKE_HCU "ECU needs communication for diagnostic purpose and keeps network awake.";
CM_ SG_ 1550 IGNITION_AWAKE_HCU "ECU can?t release communication because ignition (KL15) is turn on, or KLR is turned on";
CM_ SG_ 1550 NETWORK_AWAKE_HCU "ECU keeps the network awake due to the CAN message received from the network";
CM_ SG_ 1550 ECUSPEC_WAKEUP_HCU "ECU was in ??power off??, ??Bus Sleep??, ??Pre-pare Bus Sleep?? or ??Ready Sleep?? mode or ??awake?? and re-started by ECU specific reason (e.g. pressed Button, timer, etc.)";
CM_ SG_ 1550 NETWORK_WAKEUP_HCU "ECU was in ??Power off??, ??Bus Sleep??, ??Pre-pare Bus Sleep?? or ??Ready Sleep?? Mode and then re-started by a network communication.";
CM_ SG_ 1550 RESET_WAKEUP_HCU "If ECU was already awake, in ??Prepare Bus Sleep?? or ??Ready Sleep?? mode and re-started by an internal or an external reset.";
CM_ SG_ 1550 IGNITION_WAKEUP_HCU "ECU was ??power off?? or ??Bus sleep?? mode and started by ignition switch";
CM_ SG_ 1550 RMR_HCU "If set to 1 to force the network management of all other nodes on the bus into the re-peat message state.";
CM_ SG_ 1183 BMSH_PosSideWeldSts "?????????????????";
CM_ SG_ 1183 BMSH_InsulationSts "????????";
CM_ SG_ 1183 BMSH_InterHVILSts "?????????????";
CM_ SG_ 1183 BMSH_BattVolt "?????????";
CM_ SG_ 1183 BMSH_BatteryCurrent "???????????????????????????????????????????????????????";
CM_ SG_ 1183 BMSH_SOC "???????";
CM_ SG_ 1475 BMSH_HardwareVersionNumber7 "???????????????????????????ASCII????";
CM_ SG_ 1475 BMSH_HardwareVersionNumber6 "????????????????????????????ASCII????";
CM_ SG_ 1475 BMSH_HardwareVersionNumber5 "???????????????????????????ASCII????";
CM_ SG_ 1475 BMSH_HardwareVersionNumber4 "???????????????????????????ASCII????";
CM_ SG_ 1475 BMSH_HardwareVersionNumber3 "????????????????????????????ASCII????";
CM_ SG_ 1475 BMSH_HardwareVersionNumber2 "???????????????????????????ASCII????";
CM_ SG_ 1475 BMSH_HardwareVersionNumber1 "???????????????????????????ASCII????";
CM_ SG_ 1475 BMSH_HardwareVersionDataLength "??????????????????";
CM_ SG_ 1475 BMSH_HardwarePacketNumber "???????????????????1~2";
CM_ SG_ 1474 BMSH_SoftwareVersionNumber7 "???????????????????????????ASCII????";
CM_ SG_ 1474 BMSH_SoftwareVersionNumber6 "????????????????????????????ASCII????";
CM_ SG_ 1474 BMSH_SoftwareVersionNumber5 "???????????????????????????ASCII????";
CM_ SG_ 1474 BMSH_SoftwareVersionNumber4 "???????????????????????????ASCII????";
CM_ SG_ 1474 BMSH_SoftwareVersionNumber3 "????????????????????????????ASCII????";
CM_ SG_ 1474 BMSH_SoftwareVersionNumber2 "????????????????????????ASCII????";
CM_ SG_ 1474 BMSH_SoftwareVersionNumber1 "???????????????????????????ASCII????";
CM_ SG_ 1474 BMSH_SoftwareVersionDataLength "??????????????????";
CM_ SG_ 1474 BMSH_SoftwarePacketNumber "???????????????????1~2";
CM_ SG_ 1473 BMSH_BPTotalDischargeEnergy "??????????????????????";
CM_ SG_ 1473 BMSH_TotalFeedbackEnergy "??????????????????????";
CM_ SG_ 1473 BMSH_TotalChargeEnergy "?????????????????";
CM_ SG_ 1472 BMSH_CellSensor_TotalNum "???????????????????????";
CM_ SG_ 1472 BMSH_SingleFeedbackEnergy "???????????????????";
CM_ SG_ 1472 BMSH_SingleDisChargeEnergy "??????????????????";
CM_ SG_ 1472 BMSH_SingleChargeEnergy "??????????????????";
CM_ SG_ 1458 BMS_DTCOrder6 "???????????????????";
CM_ SG_ 1458 BMS_DTCOrder5 "??????????????????";
CM_ SG_ 1457 BMS_DTCOrder4 "??????????????????";
CM_ SG_ 1457 BMS_DTCOrder3 "???????????????????";
CM_ SG_ 1456 BMS_DTCTotalNum "???????????????";
CM_ SG_ 1456 BMS_DTCOrder2 "??????????????????";
CM_ SG_ 1456 BMS_DTCOrder1 "??????????????????";
CM_ SG_ 1454 BMS_SubsymCodeOrder24 "??????????????????????????";
CM_ SG_ 1454 BMS_SubsymCodeOrder23 "???????????????????????????";
CM_ SG_ 1454 BMS_SubsymCodeOrder22 "???????????????????????????";
CM_ SG_ 1454 BMS_SubsymCodeOrder21 "??????????????????????????";
CM_ SG_ 1454 BMS_SubsymCodeOrder20 "?????????????????????????";
CM_ SG_ 1454 BMS_SubsymCodeOrder19 "?????????????????????????";
CM_ SG_ 1454 BMS_SubsymCodeFrameTotalNum "????????????????";
CM_ SG_ 1454 BMS_SubsymCodeFrameOrder4 "???????????????4";
CM_ SG_ 1453 BMS_SubsymCodeOrder18 "?????????????????????????";
CM_ SG_ 1453 BMS_SubsymCodeOrder17 "?????????????????????????";
CM_ SG_ 1453 BMS_SubsymCodeOrder16 "??????????????????????????";
CM_ SG_ 1453 BMS_SubsymCodeOrder15 "?????????????????????????";
CM_ SG_ 1453 BMS_SubsymCodeOrder14 "?????????????????????????";
CM_ SG_ 1453 BMS_SubsymCodeOrder13 "??????????????????????????";
CM_ SG_ 1453 BMS_SubsymCodeFrameTotalNum "????????????????";
CM_ SG_ 1453 BMS_SubsymCodeFrameOrder3 "???????????????3";
CM_ SG_ 1452 BMS_SubsymCodeOrder12 "??????????????????????????";
CM_ SG_ 1452 BMS_SubsymCodeOrder11 "?????????????????????????";
CM_ SG_ 1452 BMS_SubsymCodeOrder10 "????????????????????????";
CM_ SG_ 1452 BMS_SubsymCodeOrder9 "???????????????????????";
CM_ SG_ 1452 BMS_SubsymCodeOrder8 "???????????????????????";
CM_ SG_ 1452 BMS_SubsymCodeOrder7 "????????????????????????";
CM_ SG_ 1452 BMS_SubsymCodeFrameTotalNum "????????????????";
CM_ SG_ 1452 BMS_SubsymCodeFrameOrder2 "???????????????2";
CM_ SG_ 1451 BMS_SubsymCodeOrder6 "?????????????????????????";
CM_ SG_ 1451 BMS_SubsymCodeOrder5 "????????????????????????";
CM_ SG_ 1451 BMS_SubsymCodeOrder4 "????????????????????????";
CM_ SG_ 1451 BMS_SubsymCodeOrder3 "?????????????????????????";
CM_ SG_ 1451 BMS_SubsymCodeOrder2 "????????????????????????";
CM_ SG_ 1451 BMS_SubsymCodeOrder1 "????????????????????????";
CM_ SG_ 1451 BMS_SubsymCodeFrameTotalNum "????????????????";
CM_ SG_ 1451 BMS_SubsymCodeFrameOrder1 "???????????????1";
CM_ SG_ 1450 BMSH_BalanceActive "????????";
CM_ SG_ 1450 BMSH_Battery_Uniformity "??????????";
CM_ SG_ 1450 BMSH_StoredEnergySys "??????????";
CM_ SG_ 1450 BMSH_Charge_Over "?????????????????";
CM_ SG_ 1450 BMSH_HVILcuitFailure "?????????????";
CM_ SG_ 1450 BMSH_Battery_Mismatching "????????????";
CM_ SG_ 1450 BMSH_BatteryTempLightSts "????????????";
CM_ SG_ 1450 BMSH_Charge_Over_Current "???????????";
CM_ SG_ 1450 BMSH_Discharge_Over_Current "???????????";
CM_ SG_ 1450 BMSH_IsocircuitFailure "???????";
CM_ SG_ 1450 BMSH_Cell_Voltage_Uniformity "??????????????";
CM_ SG_ 1450 BMSH_LowSOC "SOC???????";
CM_ SG_ 1450 BMSH_CellUnderVol "????????????";
CM_ SG_ 1450 BMSH_CellOverVol "?????????????";
CM_ SG_ 1450 BMSH_OverSOC "SOC???????";
CM_ SG_ 1450 BMSH_Battery_Under_Voltage "????????????????????";
CM_ SG_ 1450 BMSH_Battery_Over_Voltage "????????????????????";
CM_ SG_ 1450 BMSH_Low_Temperature "????????";
CM_ SG_ 1450 BMSH_Over_Temperature "????????";
CM_ SG_ 1450 BMSH_PacksubsystemVolt "subsystem voltage";
CM_ SG_ 1450 BMSH_SOC_Jump "SOC??????";
CM_ SG_ 1450 BMSH_PacksubsystemCurrent "subsystem current";
CM_ SG_ 1450 BMSH_TempUniformity "?????????????";
CM_ SG_ 1449 BMSH_CellVoltMin "??????????????????";
CM_ SG_ 1449 BMSH_CellVoltMax "??????????????????";
CM_ SG_ 1449 BMSH_CellVoltMin_Num "???????????????????????(??1 ???)";
CM_ SG_ 1449 BMSH_CellVoltMax_Num "???????????????????????(??1 ???)";
CM_ SG_ 1449 BMSH_VoltMin_Num "???????????????????";
CM_ SG_ 1449 BMSH_VoltMax_Num "???????????????????";
CM_ SG_ 1448 BMSH_TempMin_Num "????????????";
CM_ SG_ 1448 BMSH_TempMax_Num "????????????";
CM_ SG_ 1448 BMSH_TempSensor_MinTemp "??????????";
CM_ SG_ 1448 BMSH_TempSensor_TempMinNum "????????????(??1???)";
CM_ SG_ 1448 BMSH_TempSensor_MaxTemp "??????????";
CM_ SG_ 1448 BMSH_TempSensor_TempMaxNum "????????????(??1???)";
CM_ SG_ 1448 BMSH_TempSensor_TotalNum "????????????????????";
CM_ SG_ 1448 BMSH_BattTempAvg "??????????????";
CM_ SG_ 1436 BMSH_InsulationResis "??????????????????0xFFFE: Abnormal";
CM_ SG_ 1436 BMSH_BattTypeCode "0x0:???
0x1:?????????
0x2:???????
0x3:???????
0x4:?????????
0x5:????????????
0x6:????????
0x7:???????
0xFC:?????
0xFF:??????????????";
CM_ SG_ 1436 BMSH_batteryDataFrameNumSum "???????????";
CM_ SG_ 1436 BMSH_batteryDataFrameNum "????????????";
CM_ SG_ 1436 BMSH_PacksubsystemNum "?????????????";
CM_ SG_ 1436 BMSH_PackCellSum "??????????";
CM_ SG_ 1436 BMSH_PackCodeLength "?????????????";
CM_ SG_ 1436 BMSH_PackSubsystemSum "???????????????";
CM_ BO_ 1103 "??????";
CM_ SG_ 1103 BMSH_8_CRC "SAE J1850 CRC-8";
CM_ SG_ 1103 BMSH_8_MessageCounter "Alivecounter";
CM_ SG_ 1103 BMSH_LeftChargeTime "????????";
CM_ SG_ 1103 BMSH_PackInstantRecoveryPower "?????????????????H??";
CM_ SG_ 1103 BMSH_PackInstantOutPower "???????????????H??";
CM_ BO_ 1096 "??????";
CM_ SG_ 1096 BMSH_7_CRC "SAE J1850 CRC-8";
CM_ SG_ 1096 BMSH_7_MessageCounter "Alivecounter";
CM_ SG_ 1096 BMSH_ChargeEnable "??????????????";
CM_ SG_ 1096 BMSH_BatteryMaintainLightReq "??????????";
CM_ SG_ 1096 BMSH_ChargeReq "???????";
CM_ SG_ 1096 BMS_BattWarmRequest "BMS battery heat request";
CM_ SG_ 1096 BMSH_ChargeOutMinCurSet "????????????????";
CM_ SG_ 1096 BMSH_ChargeOutMaxCurSet "????????????????";
CM_ SG_ 1096 BMSH_ChargeOutVolSet "???????????????";
CM_ BO_ 1091 "????????";
CM_ SG_ 1091 BMSH_6_CRC "SAE J1850 CRC-8";
CM_ SG_ 1091 BMSH_6_MessageCounter "Alivecounter";
CM_ SG_ 1091 BMSH_WaterTempChangeRateReq "???????????????????????";
CM_ SG_ 1091 BMSH_PackThermalSensorSts "??????????????????????????";
CM_ SG_ 1091 BMSH_ThermalManageReq "??????????????????";
CM_ SG_ 1091 BMSH_FlowRateReq "??????????????????????";
CM_ SG_ 1091 BMSH_HeatPowerReq "???????????????????????";
CM_ SG_ 1091 BMSH_InletWaterTempTarget "????????????????????????";
CM_ SG_ 1091 BMSH_OutletWaterTemp "?????????????????";
CM_ SG_ 1091 BMSH_InletWaterTemp "?????????????????";
CM_ BO_ 1083 "???????";
CM_ SG_ 1083 BMSH_5_CRC "SAE J1850 CRC-8";
CM_ SG_ 1083 BMSH_5_MessageCounter "Alivecounter";
CM_ SG_ 1083 BMSH_PackMileRemain "???????????";
CM_ SG_ 1083 BMSH_PackRemainEnergy "???????????";
CM_ SG_ 1083 BMSH_PackFaultLevel "???????????
??????Derating????????????????????????HCU??
????????????????!dou!HCU?????????????
??????????????!dou!??????????!dun!?????????";
CM_ SG_ 1083 BMSH_MILReq "MIL??????";
CM_ SG_ 1083 BMSH_BattFaultLampSts "?????????????";
CM_ SG_ 1083 BMSH_PackThermalRunawayLight "????????????????????????";
CM_ SG_ 1083 BMSH_DisChgFaultLevel "?????????????????????????";
CM_ SG_ 1083 BMSH_ChgFaultLevel "??????????????????????????";
CM_ SG_ 1083 BMSH_SOCDisp "???????????";
CM_ BO_ 427 "????map";
CM_ SG_ 427 BMSH_MaxDchgPwrCont "?????????????????????H??";
CM_ SG_ 427 BMSH_MaxDchgPwrPeak "????????????????????H??";
CM_ BO_ 420 "????map";
CM_ SG_ 420 BMSH_MainPrechgResistanceSts "?????????????????????";
CM_ SG_ 420 BMSH_PTCFuseSts "???????????????PTC??????";
CM_ SG_ 420 BMSH_RmcuFuseSts "????????????MCU??????";
CM_ SG_ 420 BMSH_FmcuFuseSts "????????????MCU??????";
CM_ SG_ 420 BMSH_BattVoltMinLimt "???????????????";
CM_ SG_ 420 BMSH_BattVoltMaxLimt "???????????????";
CM_ SG_ 420 BMSH_MaxChgPwrCont "?????????????????????H??";
CM_ SG_ 420 BMSH_MaxChgPwrPeak "????????????????????H??";
CM_ BO_ 411 "??????";
CM_ SG_ 411 BMSH_2_CRC "SAE J1850 CRC-8";
CM_ SG_ 411 BMSH_2_MessageCounter "Alivecounter";
CM_ SG_ 411 BMSH_BookSetReq "?????????";
CM_ SG_ 411 BMSH_PTCRelayWeldSts "???????????????";
CM_ SG_ 411 BMSH_CHGPrechargeWeldSts "?????????????";
CM_ SG_ 411 BMSH_PreChargeWeldSts "????????????????";
CM_ SG_ 411 BMSH_NegSideWeldSts "?????????????????";
CM_ SG_ 411 BMSH_PosSideWeldSts "?????????????????";
CM_ SG_ 411 BMSH_PTCRelaySts "????????????";
CM_ SG_ 411 BMSH_CHGPrechargeRelaySts "?????????????";
CM_ SG_ 411 BMSH_PrechargeRelaySts "?????????????";
CM_ SG_ 411 BMSH_NegMainRelaySts "???????????????";
CM_ SG_ 411 BMSH_PosMainRelaySts "???????????????";
CM_ SG_ 411 BMSH_IntelligentChargeReq "??????????BMSH???12V??????????????????????????????????";
CM_ SG_ 411 BMSH_OBCPrechgSt "?????????";
CM_ SG_ 411 BMSH_MainPrechgSt "?????????";
CM_ SG_ 411 BMSH_InsulationSts "????????";
CM_ SG_ 411 BMSH_VehicleHVILSts "?????????????????";
CM_ SG_ 411 BMSH_InterHVILSts "?????????????";
CM_ SG_ 411 BMSH_SOH "?????????";
CM_ SG_ 411 BMSH_HVBusVolt "????????????";
CM_ BO_ 403 "??????";
CM_ SG_ 403 BMSH_1_CRC "SAE J1850 CRC-8";
CM_ SG_ 403 BMSH_1_MessageCounter "Alivecounter";
CM_ SG_ 403 BMSH_WorkingMode "??????";
CM_ SG_ 403 BMSH_BattVolt "?????????";
CM_ SG_ 403 BMSH_BatteryCurrent "???????????????????????????????????????????????????????";
CM_ SG_ 403 BMSH_SOC "???????";
CM_ SG_ 1084 OBC_FaultCode "OBC fault matrix";
CM_ SG_ 1084 OBC_MaxOutputVoltage "OBC maximum output current";
CM_ SG_ 1084 OBC_MaxOutputCurrent "OBC maximum output voltage";
CM_ SG_ 1067 OBC_WorkingMode "OBC working states";
CM_ SG_ 1067 OBC_ElectronicLockSts "Electronic Lock Sts";
CM_ SG_ 1067 OBC_CC_ConnectSts "CC connect states";
CM_ SG_ 1067 OBC_CP_DutyCycleFault "CP pwm fault";
CM_ SG_ 1067 OBC_CP_DutyCycleValue "CP pwm";
CM_ SG_ 1064 OBC_KL30_UnderVolt "KL30 under voltage";
CM_ SG_ 1064 OBC_InputVolt "OBC input voltage";
CM_ SG_ 1064 OBC_InputCurr "OBC input current";
CM_ SG_ 1061 OBC_FaultLevelSts "OBC fault states";
CM_ SG_ 1061 OBC_ChgSts "OBC charge stated";
CM_ SG_ 1061 OBC_OutputPowerLimt "output power limit";
CM_ SG_ 1061 OBC_ChgVolt "output voltage";
CM_ SG_ 1061 OBC_ChgCurr "output current";
CM_ SG_ 1048 DCDC_LvSideCurr "DCDC output current";
CM_ SG_ 1048 DCDC_LvSideVolt "DCDC output voltage";
CM_ SG_ 808 TMR_VoltageHV "HV voltage at the DC/AC converter";
CM_ SG_ 808 TMR_CurrentHV "HV current at the DC/AC converter";
CM_ SG_ 371 TMR_State "NCtlInt
NCtlExt
IsCtrl
UdcCtrl
ResdHilHld 
A?????????";
CM_ SG_ 795 TMF_UdcAct "actual bus voltage";
CM_ SG_ 795 TMF_IdcAct "actual HV current at generator";
CM_ SG_ 348 TMF_ModeSt "actual state of TMF motor";
CM_ SG_ 786 ISGF_UdcAct "actual bus voltage";
CM_ SG_ 786 ISGF_IdcAct "actual HV current at generator";
CM_ SG_ 326 ISGF_ModeSt "actual state of ISG motor";
CM_ SG_ 264 HCU_BattHeatAllow "Battery pack heat request";
CM_ SG_ 264 HCU_VehicleAllowToCharge "Indication of vehicle condition allow to charge or not";
CM_ SG_ 264 HCU_BMS_stModeReq "BMS recieves State request from HCU for power Up / power Down.";
BA_DEF_  "NmAsrCanMsgCycleTime" INT 1000 1000;
BA_DEF_  "NmAsrRepeatMessageTime" INT 3000 3000;
BA_DEF_  "NmAsrWaitBusSleepTime" INT 1500 1500;
BA_DEF_  "NmAsrTimeoutTime" INT 2500 2500;
BA_DEF_  "NmAsrBaseAddress" HEX 0 2047;
BA_DEF_  "NmAsrMessageCount" INT 128 128;
BA_DEF_  "NmType" STRING ;
BA_DEF_  "ILTxTimeout" INT 0 65535;
BA_DEF_  "Manufacturer" STRING ;
BA_DEF_ SG_  "GenSigTimeoutValue" INT 0 2147483647;
BA_DEF_ SG_  "GenSigStartValue" INT 0 2147483647;
BA_DEF_ SG_  "GenSigInactiveValue" INT 0 2147483647;
BA_DEF_ BO_  "TpTxIndex" INT 0 255;
BA_DEF_ BO_  "DiagUudtResponse" ENUM  "False","True";
BA_DEF_ BO_  "DiagResponse" ENUM  "No","Yes";
BA_DEF_ BO_  "DiagRequest" ENUM  "No","Yes";
BA_DEF_ BO_  "DiagState" ENUM  "No","Yes";
BA_DEF_ BO_  "NmAsrMessage" ENUM  "No","Yes";
BA_DEF_ BO_  "GenMsgFastOnStart" INT 0 65535;
BA_DEF_ BO_  "GenMsgCycleTimeFast" INT 0 65535;
BA_DEF_ BO_  "GenMsgNrOfRepetition" INT 0 65535;
BA_DEF_ BO_  "GenMsgStartDelayTime" INT 0 65535;
BA_DEF_ BO_  "GenMsgCycleTime" INT 0 65535;
BA_DEF_ BO_  "GenMsgDelayTime" INT 0 65535;
BA_DEF_ SG_  "GenSigSendType" ENUM  "Cyclic","OnWrite","OnWriteWithRepetition","OnChange","OnChangeWithRepetition","IfActive","IfActiveWithRepetition","NoSigSendType","OnChangeAndIfActive","OnChangeAndIfActiveWithRepetition";
BA_DEF_ BO_  "GenMsgSendType" ENUM  "Cyclic","NotUsed","NotUsed","NotUsed","NotUsed","NotUsed","NotUsed","IfActive","NoMsgSendType";
BA_DEF_ BO_  "GenMsgILSupport" ENUM  "No","Yes";
BA_DEF_ BU_  "NmStationAddress" HEX 0 255;
BA_DEF_ BU_  "NmAsrCanMsgReducedTime" INT 500 818;
BA_DEF_ BU_  "NmAsrCanMsgCycleOffset" INT 0 635;
BA_DEF_ BU_  "NmAsrNodeIdentifier" HEX 0 255;
BA_DEF_ BU_  "NmAsrNode" ENUM  "No","Yes";
BA_DEF_ BU_  "ILUsed" ENUM  "No","Yes";
BA_DEF_REL_ BU_SG_REL_  "GenSigTimeoutTime" INT 0 65535;
BA_DEF_DEF_  "NmAsrCanMsgCycleTime" 1000;
BA_DEF_DEF_  "NmAsrRepeatMessageTime" 3000;
BA_DEF_DEF_  "NmAsrWaitBusSleepTime" 1500;
BA_DEF_DEF_  "NmAsrTimeoutTime" 2500;
BA_DEF_DEF_  "NmAsrBaseAddress" 1536;
BA_DEF_DEF_  "NmAsrMessageCount" 128;
BA_DEF_DEF_  "NmType" "NmAsr";
BA_DEF_DEF_  "ILTxTimeout" 0;
BA_DEF_DEF_  "Manufacturer" "Vector";
BA_DEF_DEF_REL_ "GenSigTimeoutTime" 0;
BA_DEF_DEF_  "GenSigTimeoutValue" 0;
BA_DEF_DEF_  "GenSigStartValue" 0;
BA_DEF_DEF_  "GenSigInactiveValue" 0;
BA_DEF_DEF_  "TpTxIndex" 0;
BA_DEF_DEF_  "DiagUudtResponse" "False";
BA_DEF_DEF_  "DiagResponse" "No";
BA_DEF_DEF_  "DiagRequest" "No";
BA_DEF_DEF_  "DiagState" "No";
BA_DEF_DEF_  "NmAsrMessage" "No";
BA_DEF_DEF_  "GenMsgFastOnStart" 0;
BA_DEF_DEF_  "GenMsgCycleTimeFast" 0;
BA_DEF_DEF_  "GenMsgNrOfRepetition" 3;
BA_DEF_DEF_  "GenMsgStartDelayTime" 0;
BA_DEF_DEF_  "GenMsgCycleTime" 0;
BA_DEF_DEF_  "GenMsgDelayTime" 0;
BA_DEF_DEF_  "GenSigSendType" "NoSigSendType";
BA_DEF_DEF_  "GenMsgSendType" "NoMsgSendType";
BA_DEF_DEF_  "GenMsgILSupport" "No";
BA_DEF_DEF_  "NmStationAddress" 255;
BA_DEF_DEF_  "NmAsrCanMsgReducedTime" 575;
BA_DEF_DEF_  "NmAsrCanMsgCycleOffset" 0;
BA_DEF_DEF_  "NmAsrNodeIdentifier" 255;
BA_DEF_DEF_  "NmAsrNode" "No";
BA_DEF_DEF_  "ILUsed" "No";
BA_ "NmStationAddress" BU_ BMS 15;
BA_ "NmAsrNodeIdentifier" BU_ BMS 15;
BA_ "NmAsrNode" BU_ BMS 1;
BA_ "ILUsed" BU_ BMS 1;
BA_ "GenMsgILSupport" BO_ 1072 1;
BA_ "GenMsgSendType" BO_ 1072 0;
BA_ "GenMsgNrOfRepetition" BO_ 1072 0;
BA_ "GenMsgCycleTime" BO_ 1072 20;
BA_ "GenMsgILSupport" BO_ 800 1;
BA_ "GenMsgSendType" BO_ 800 0;
BA_ "GenMsgNrOfRepetition" BO_ 800 6;
BA_ "GenMsgDelayTime" BO_ 800 5;
BA_ "GenMsgCycleTimeFast" BO_ 800 20;
BA_ "GenMsgCycleTime" BO_ 800 500;
BA_ "GenMsgILSupport" BO_ 1333 1;
BA_ "GenMsgSendType" BO_ 1333 0;
BA_ "GenMsgNrOfRepetition" BO_ 1333 0;
BA_ "GenMsgDelayTime" BO_ 1333 5;
BA_ "GenMsgCycleTime" BO_ 1333 100;
BA_ "NmAsrMessage" BO_ 1583 1;
BA_ "GenMsgSendType" BO_ 1583 0;
BA_ "GenMsgNrOfRepetition" BO_ 1583 0;
BA_ "GenMsgCycleTime" BO_ 1583 1000;
BA_ "NmAsrMessage" BO_ 1582 1;
BA_ "GenMsgSendType" BO_ 1582 0;
BA_ "GenMsgNrOfRepetition" BO_ 1582 0;
BA_ "GenMsgCycleTime" BO_ 1582 1000;
BA_ "NmAsrMessage" BO_ 1585 1;
BA_ "GenMsgSendType" BO_ 1585 0;
BA_ "GenMsgNrOfRepetition" BO_ 1585 0;
BA_ "GenMsgCycleTime" BO_ 1585 1000;
BA_ "NmAsrMessage" BO_ 1580 1;
BA_ "GenMsgSendType" BO_ 1580 0;
BA_ "GenMsgNrOfRepetition" BO_ 1580 0;
BA_ "GenMsgCycleTime" BO_ 1580 1000;
BA_ "NmAsrMessage" BO_ 1551 1;
BA_ "GenMsgSendType" BO_ 1551 0;
BA_ "GenMsgNrOfRepetition" BO_ 1551 0;
BA_ "GenMsgCycleTime" BO_ 1551 1000;
BA_ "NmAsrMessage" BO_ 1550 1;
BA_ "GenMsgSendType" BO_ 1550 0;
BA_ "GenMsgNrOfRepetition" BO_ 1550 0;
BA_ "GenMsgCycleTime" BO_ 1550 1000;
BA_ "GenMsgILSupport" BO_ 1381 1;
BA_ "GenMsgSendType" BO_ 1381 0;
BA_ "GenMsgNrOfRepetition" BO_ 1381 0;
BA_ "GenMsgCycleTime" BO_ 1381 1000;
BA_ "GenMsgILSupport" BO_ 1380 1;
BA_ "GenMsgSendType" BO_ 1380 0;
BA_ "GenMsgNrOfRepetition" BO_ 1380 0;
BA_ "GenMsgCycleTime" BO_ 1380 1000;
BA_ "GenMsgILSupport" BO_ 1379 1;
BA_ "GenMsgSendType" BO_ 1379 0;
BA_ "GenMsgNrOfRepetition" BO_ 1379 0;
BA_ "GenMsgCycleTime" BO_ 1379 1000;
BA_ "GenMsgILSupport" BO_ 1378 1;
BA_ "GenMsgSendType" BO_ 1378 0;
BA_ "GenMsgNrOfRepetition" BO_ 1378 0;
BA_ "GenMsgCycleTime" BO_ 1378 1000;
BA_ "GenMsgILSupport" BO_ 1377 1;
BA_ "GenMsgSendType" BO_ 1377 0;
BA_ "GenMsgNrOfRepetition" BO_ 1377 0;
BA_ "GenMsgCycleTime" BO_ 1377 1000;
BA_ "GenMsgILSupport" BO_ 1376 1;
BA_ "GenMsgSendType" BO_ 1376 0;
BA_ "GenMsgNrOfRepetition" BO_ 1376 0;
BA_ "GenMsgCycleTime" BO_ 1376 1000;
BA_ "GenMsgILSupport" BO_ 1367 1;
BA_ "GenMsgSendType" BO_ 1367 0;
BA_ "GenMsgNrOfRepetition" BO_ 1367 0;
BA_ "GenMsgCycleTime" BO_ 1367 1000;
BA_ "GenMsgILSupport" BO_ 1366 1;
BA_ "GenMsgSendType" BO_ 1366 0;
BA_ "GenMsgNrOfRepetition" BO_ 1366 0;
BA_ "GenMsgCycleTime" BO_ 1366 1000;
BA_ "GenMsgILSupport" BO_ 1365 1;
BA_ "GenMsgSendType" BO_ 1365 0;
BA_ "GenMsgNrOfRepetition" BO_ 1365 0;
BA_ "GenMsgCycleTime" BO_ 1365 1000;
BA_ "GenMsgILSupport" BO_ 1364 1;
BA_ "GenMsgSendType" BO_ 1364 0;
BA_ "GenMsgNrOfRepetition" BO_ 1364 0;
BA_ "GenMsgCycleTime" BO_ 1364 1000;
BA_ "GenMsgILSupport" BO_ 1363 1;
BA_ "GenMsgSendType" BO_ 1363 0;
BA_ "GenMsgNrOfRepetition" BO_ 1363 0;
BA_ "GenMsgCycleTime" BO_ 1363 1000;
BA_ "GenMsgILSupport" BO_ 1362 1;
BA_ "GenMsgSendType" BO_ 1362 0;
BA_ "GenMsgNrOfRepetition" BO_ 1362 0;
BA_ "GenMsgCycleTime" BO_ 1362 1000;
BA_ "GenMsgILSupport" BO_ 1361 1;
BA_ "GenMsgSendType" BO_ 1361 0;
BA_ "GenMsgNrOfRepetition" BO_ 1361 0;
BA_ "GenMsgCycleTime" BO_ 1361 1000;
BA_ "GenMsgILSupport" BO_ 1360 1;
BA_ "GenMsgSendType" BO_ 1360 0;
BA_ "GenMsgNrOfRepetition" BO_ 1360 0;
BA_ "GenMsgCycleTime" BO_ 1360 1000;
BA_ "GenMsgILSupport" BO_ 1359 1;
BA_ "GenMsgSendType" BO_ 1359 0;
BA_ "GenMsgNrOfRepetition" BO_ 1359 0;
BA_ "GenMsgCycleTime" BO_ 1359 1000;
BA_ "GenMsgILSupport" BO_ 1358 1;
BA_ "GenMsgSendType" BO_ 1358 0;
BA_ "GenMsgNrOfRepetition" BO_ 1358 0;
BA_ "GenMsgCycleTime" BO_ 1358 1000;
BA_ "GenMsgILSupport" BO_ 1357 1;
BA_ "GenMsgSendType" BO_ 1357 0;
BA_ "GenMsgNrOfRepetition" BO_ 1357 0;
BA_ "GenMsgCycleTime" BO_ 1357 1000;
BA_ "GenMsgILSupport" BO_ 1356 1;
BA_ "GenMsgSendType" BO_ 1356 0;
BA_ "GenMsgNrOfRepetition" BO_ 1356 0;
BA_ "GenMsgCycleTime" BO_ 1356 1000;
BA_ "GenMsgILSupport" BO_ 1355 1;
BA_ "GenMsgSendType" BO_ 1355 0;
BA_ "GenMsgNrOfRepetition" BO_ 1355 0;
BA_ "GenMsgCycleTime" BO_ 1355 1000;
BA_ "GenMsgILSupport" BO_ 1354 1;
BA_ "GenMsgSendType" BO_ 1354 0;
BA_ "GenMsgNrOfRepetition" BO_ 1354 0;
BA_ "GenMsgCycleTime" BO_ 1354 1000;
BA_ "GenMsgILSupport" BO_ 1353 1;
BA_ "GenMsgSendType" BO_ 1353 0;
BA_ "GenMsgNrOfRepetition" BO_ 1353 0;
BA_ "GenMsgCycleTime" BO_ 1353 1000;
BA_ "GenMsgILSupport" BO_ 1352 1;
BA_ "GenMsgSendType" BO_ 1352 0;
BA_ "GenMsgNrOfRepetition" BO_ 1352 0;
BA_ "GenMsgCycleTime" BO_ 1352 1000;
BA_ "GenMsgILSupport" BO_ 1351 1;
BA_ "GenMsgSendType" BO_ 1351 0;
BA_ "GenMsgNrOfRepetition" BO_ 1351 0;
BA_ "GenMsgCycleTime" BO_ 1351 1000;
BA_ "GenMsgILSupport" BO_ 1350 1;
BA_ "GenMsgSendType" BO_ 1350 0;
BA_ "GenMsgNrOfRepetition" BO_ 1350 0;
BA_ "GenMsgCycleTime" BO_ 1350 1000;
BA_ "GenMsgILSupport" BO_ 1349 1;
BA_ "GenMsgSendType" BO_ 1349 0;
BA_ "GenMsgNrOfRepetition" BO_ 1349 0;
BA_ "GenMsgCycleTime" BO_ 1349 1000;
BA_ "GenMsgILSupport" BO_ 1348 1;
BA_ "GenMsgSendType" BO_ 1348 0;
BA_ "GenMsgNrOfRepetition" BO_ 1348 0;
BA_ "GenMsgCycleTime" BO_ 1348 1000;
BA_ "GenMsgILSupport" BO_ 1347 1;
BA_ "GenMsgSendType" BO_ 1347 0;
BA_ "GenMsgNrOfRepetition" BO_ 1347 0;
BA_ "GenMsgCycleTime" BO_ 1347 1000;
BA_ "GenMsgILSupport" BO_ 1346 1;
BA_ "GenMsgSendType" BO_ 1346 0;
BA_ "GenMsgNrOfRepetition" BO_ 1346 0;
BA_ "GenMsgCycleTime" BO_ 1346 1000;
BA_ "GenMsgILSupport" BO_ 1345 1;
BA_ "GenMsgSendType" BO_ 1345 0;
BA_ "GenMsgNrOfRepetition" BO_ 1345 0;
BA_ "GenMsgCycleTime" BO_ 1345 1000;
BA_ "GenMsgILSupport" BO_ 1344 1;
BA_ "GenMsgSendType" BO_ 1344 0;
BA_ "GenMsgNrOfRepetition" BO_ 1344 0;
BA_ "GenMsgCycleTime" BO_ 1344 1000;
BA_ "GenMsgILSupport" BO_ 1183 1;
BA_ "GenMsgSendType" BO_ 1183 0;
BA_ "GenMsgNrOfRepetition" BO_ 1183 0;
BA_ "GenMsgCycleTime" BO_ 1183 100;
BA_ "GenMsgILSupport" BO_ 1475 1;
BA_ "GenMsgSendType" BO_ 1475 0;
BA_ "GenMsgNrOfRepetition" BO_ 1475 0;
BA_ "GenMsgCycleTime" BO_ 1475 1000;
BA_ "GenMsgILSupport" BO_ 1474 1;
BA_ "GenMsgSendType" BO_ 1474 0;
BA_ "GenMsgNrOfRepetition" BO_ 1474 0;
BA_ "GenMsgCycleTime" BO_ 1474 1000;
BA_ "GenMsgILSupport" BO_ 1473 1;
BA_ "GenMsgSendType" BO_ 1473 0;
BA_ "GenMsgNrOfRepetition" BO_ 1473 0;
BA_ "GenMsgCycleTime" BO_ 1473 1000;
BA_ "GenMsgILSupport" BO_ 1472 1;
BA_ "GenMsgSendType" BO_ 1472 0;
BA_ "GenMsgNrOfRepetition" BO_ 1472 0;
BA_ "GenMsgCycleTime" BO_ 1472 1000;
BA_ "GenMsgILSupport" BO_ 1458 1;
BA_ "GenMsgSendType" BO_ 1458 0;
BA_ "GenMsgNrOfRepetition" BO_ 1458 0;
BA_ "GenMsgCycleTime" BO_ 1458 1000;
BA_ "GenMsgILSupport" BO_ 1457 1;
BA_ "GenMsgSendType" BO_ 1457 0;
BA_ "GenMsgNrOfRepetition" BO_ 1457 0;
BA_ "GenMsgCycleTime" BO_ 1457 1000;
BA_ "GenMsgILSupport" BO_ 1456 1;
BA_ "GenMsgSendType" BO_ 1456 0;
BA_ "GenMsgNrOfRepetition" BO_ 1456 0;
BA_ "GenMsgCycleTime" BO_ 1456 1000;
BA_ "GenMsgILSupport" BO_ 1454 1;
BA_ "GenMsgSendType" BO_ 1454 0;
BA_ "GenMsgNrOfRepetition" BO_ 1454 0;
BA_ "GenMsgCycleTime" BO_ 1454 1000;
BA_ "GenMsgILSupport" BO_ 1453 1;
BA_ "GenMsgSendType" BO_ 1453 0;
BA_ "GenMsgNrOfRepetition" BO_ 1453 0;
BA_ "GenMsgCycleTime" BO_ 1453 1000;
BA_ "GenMsgILSupport" BO_ 1452 1;
BA_ "GenMsgSendType" BO_ 1452 0;
BA_ "GenMsgNrOfRepetition" BO_ 1452 0;
BA_ "GenMsgCycleTime" BO_ 1452 1000;
BA_ "GenMsgILSupport" BO_ 1451 1;
BA_ "GenMsgSendType" BO_ 1451 0;
BA_ "GenMsgNrOfRepetition" BO_ 1451 0;
BA_ "GenMsgCycleTime" BO_ 1451 1000;
BA_ "GenMsgILSupport" BO_ 1450 1;
BA_ "GenMsgSendType" BO_ 1450 0;
BA_ "GenMsgNrOfRepetition" BO_ 1450 0;
BA_ "GenMsgCycleTime" BO_ 1450 1000;
BA_ "GenMsgILSupport" BO_ 1449 1;
BA_ "GenMsgSendType" BO_ 1449 0;
BA_ "GenMsgNrOfRepetition" BO_ 1449 0;
BA_ "GenMsgCycleTime" BO_ 1449 1000;
BA_ "GenMsgILSupport" BO_ 1448 1;
BA_ "GenMsgSendType" BO_ 1448 0;
BA_ "GenMsgNrOfRepetition" BO_ 1448 0;
BA_ "GenMsgCycleTime" BO_ 1448 1000;
BA_ "GenMsgILSupport" BO_ 1436 1;
BA_ "GenMsgSendType" BO_ 1436 0;
BA_ "GenMsgNrOfRepetition" BO_ 1436 0;
BA_ "GenMsgCycleTime" BO_ 1436 1000;
BA_ "GenMsgILSupport" BO_ 1103 1;
BA_ "GenMsgSendType" BO_ 1103 0;
BA_ "GenMsgNrOfRepetition" BO_ 1103 0;
BA_ "GenMsgCycleTime" BO_ 1103 100;
BA_ "GenMsgILSupport" BO_ 1096 1;
BA_ "GenMsgSendType" BO_ 1096 0;
BA_ "GenMsgNrOfRepetition" BO_ 1096 0;
BA_ "GenMsgCycleTime" BO_ 1096 100;
BA_ "GenMsgILSupport" BO_ 1091 1;
BA_ "GenMsgSendType" BO_ 1091 0;
BA_ "GenMsgNrOfRepetition" BO_ 1091 0;
BA_ "GenMsgCycleTime" BO_ 1091 100;
BA_ "GenMsgILSupport" BO_ 1083 1;
BA_ "GenMsgSendType" BO_ 1083 0;
BA_ "GenMsgNrOfRepetition" BO_ 1083 0;
BA_ "GenMsgCycleTime" BO_ 1083 100;
BA_ "GenMsgILSupport" BO_ 427 1;
BA_ "GenMsgSendType" BO_ 427 0;
BA_ "GenMsgNrOfRepetition" BO_ 427 0;
BA_ "GenMsgCycleTime" BO_ 427 10;
BA_ "GenMsgILSupport" BO_ 420 1;
BA_ "GenMsgSendType" BO_ 420 0;
BA_ "GenMsgNrOfRepetition" BO_ 420 0;
BA_ "GenMsgCycleTime" BO_ 420 10;
BA_ "GenMsgILSupport" BO_ 411 1;
BA_ "GenMsgSendType" BO_ 411 0;
BA_ "GenMsgNrOfRepetition" BO_ 411 0;
BA_ "GenMsgCycleTime" BO_ 411 10;
BA_ "GenMsgILSupport" BO_ 403 1;
BA_ "GenMsgSendType" BO_ 403 0;
BA_ "GenMsgNrOfRepetition" BO_ 403 0;
BA_ "GenMsgCycleTime" BO_ 403 10;
BA_ "GenMsgILSupport" BO_ 1084 1;
BA_ "GenMsgSendType" BO_ 1084 0;
BA_ "GenMsgNrOfRepetition" BO_ 1084 0;
BA_ "GenMsgCycleTime" BO_ 1084 100;
BA_ "GenMsgILSupport" BO_ 1067 1;
BA_ "GenMsgSendType" BO_ 1067 0;
BA_ "GenMsgNrOfRepetition" BO_ 1067 0;
BA_ "GenMsgCycleTime" BO_ 1067 100;
BA_ "GenMsgILSupport" BO_ 1064 1;
BA_ "GenMsgSendType" BO_ 1064 0;
BA_ "GenMsgNrOfRepetition" BO_ 1064 0;
BA_ "GenMsgCycleTime" BO_ 1064 100;
BA_ "GenMsgILSupport" BO_ 1061 1;
BA_ "GenMsgSendType" BO_ 1061 0;
BA_ "GenMsgNrOfRepetition" BO_ 1061 0;
BA_ "GenMsgCycleTime" BO_ 1061 100;
BA_ "GenMsgILSupport" BO_ 1048 1;
BA_ "GenMsgSendType" BO_ 1048 0;
BA_ "GenMsgNrOfRepetition" BO_ 1048 0;
BA_ "GenMsgCycleTime" BO_ 1048 100;
BA_ "GenMsgILSupport" BO_ 808 1;
BA_ "GenMsgSendType" BO_ 808 0;
BA_ "GenMsgNrOfRepetition" BO_ 808 0;
BA_ "GenMsgCycleTime" BO_ 808 50;
BA_ "GenMsgILSupport" BO_ 371 1;
BA_ "GenMsgSendType" BO_ 371 0;
BA_ "GenMsgNrOfRepetition" BO_ 371 0;
BA_ "GenMsgCycleTime" BO_ 371 10;
BA_ "GenMsgILSupport" BO_ 795 1;
BA_ "GenMsgSendType" BO_ 795 0;
BA_ "GenMsgNrOfRepetition" BO_ 795 0;
BA_ "GenMsgCycleTime" BO_ 795 50;
BA_ "GenMsgILSupport" BO_ 348 1;
BA_ "GenMsgSendType" BO_ 348 0;
BA_ "GenMsgNrOfRepetition" BO_ 348 0;
BA_ "GenMsgCycleTime" BO_ 348 10;
BA_ "GenMsgILSupport" BO_ 786 1;
BA_ "GenMsgSendType" BO_ 786 0;
BA_ "GenMsgNrOfRepetition" BO_ 786 0;
BA_ "GenMsgCycleTime" BO_ 786 50;
BA_ "GenMsgILSupport" BO_ 326 1;
BA_ "GenMsgSendType" BO_ 326 0;
BA_ "GenMsgNrOfRepetition" BO_ 326 0;
BA_ "GenMsgCycleTime" BO_ 326 10;
BA_ "GenMsgILSupport" BO_ 264 1;
BA_ "GenMsgSendType" BO_ 264 0;
BA_ "GenMsgNrOfRepetition" BO_ 264 0;
BA_ "GenMsgCycleTime" BO_ 264 10;
BA_ "GenSigSendType" SG_ 1072 TotalOdometer_km 0;
BA_ "GenSigSendType" SG_ 1072 BatteryVoltage 0;
BA_ "GenSigSendType" SG_ 800 CrashOutputSts 2;
BA_ "GenSigSendType" SG_ 800 ABM_1_CheckSum 0;
BA_ "GenSigSendType" SG_ 800 ABM_1_MessageCounter 0;
BA_ "GenSigSendType" SG_ 1333 ExternalTemperatureRaw_C 0;
BA_ "GenSigStartValue" SG_ 1333 ExternalTemperatureRaw_C 254;
BA_ "GenSigSendType" SG_ 1333 ExternalTemperatureFailSts_GS 0;
BA_ "GenSigSendType" SG_ 1583 usrData5_CDU 0;
BA_ "GenSigSendType" SG_ 1583 usrData4_CDU 0;
BA_ "GenSigSendType" SG_ 1583 usrData3_CDU 0;
BA_ "GenSigSendType" SG_ 1583 usrData2_CDU 0;
BA_ "GenSigSendType" SG_ 1583 ECUSPEC_AWAKE_CDU 0;
BA_ "GenSigSendType" SG_ 1583 DIAGNOSTIC_AWAKE_CDU 0;
BA_ "GenSigSendType" SG_ 1583 IGNITION_AWAKE_CDU 0;
BA_ "GenSigSendType" SG_ 1583 NETWORK_AWAKE_CDU 0;
BA_ "GenSigSendType" SG_ 1583 ECUSPEC_WAKEUP_CDU 0;
BA_ "GenSigSendType" SG_ 1583 NETWORK_WAKEUP_CDU 0;
BA_ "GenSigSendType" SG_ 1583 RESET_WAKEUP_CDU 0;
BA_ "GenSigSendType" SG_ 1583 IGNITION_WAKEUP_CDU 0;
BA_ "GenSigSendType" SG_ 1583 usrData0_CDU 0;
BA_ "GenSigSendType" SG_ 1583 NMm_CDU_Reserved1 0;
BA_ "GenSigSendType" SG_ 1583 RMR_CDU 0;
BA_ "GenSigSendType" SG_ 1583 srcNodeID_CDU 0;
BA_ "GenSigStartValue" SG_ 1583 srcNodeID_CDU 2;
BA_ "GenSigSendType" SG_ 1582 usrData5_MCUR 0;
BA_ "GenSigSendType" SG_ 1582 usrData4_MCUR 0;
BA_ "GenSigSendType" SG_ 1582 usrData3_MCUR 0;
BA_ "GenSigSendType" SG_ 1582 usrData2_MCUR 0;
BA_ "GenSigSendType" SG_ 1582 ECUSPEC_AWAKE_MCUR 0;
BA_ "GenSigSendType" SG_ 1582 DIAGNOSTIC_AWAKE_MCUR 0;
BA_ "GenSigSendType" SG_ 1582 IGNITION_AWAKE_MCUR 0;
BA_ "GenSigSendType" SG_ 1582 NETWORK_AWAKE_MCUR 0;
BA_ "GenSigSendType" SG_ 1582 ECUSPEC_WAKEUP_MCUR 0;
BA_ "GenSigSendType" SG_ 1582 NETWORK_WAKEUP_MCUR 0;
BA_ "GenSigSendType" SG_ 1582 RESET_WAKEUP_MCUR 0;
BA_ "GenSigSendType" SG_ 1582 IGNITION_WAKEUP_MCUR 0;
BA_ "GenSigSendType" SG_ 1582 usrData0_MCUR 0;
BA_ "GenSigSendType" SG_ 1582 NMm_MCUR_Reserved1 0;
BA_ "GenSigSendType" SG_ 1582 RMR_MCUR 0;
BA_ "GenSigSendType" SG_ 1582 srcNodeID_MCUR 0;
BA_ "GenSigStartValue" SG_ 1582 srcNodeID_MCUR 2;
BA_ "GenSigSendType" SG_ 1585 usrData5_TMF 0;
BA_ "GenSigSendType" SG_ 1585 usrData4_TMF 0;
BA_ "GenSigSendType" SG_ 1585 usrData3_TMF 0;
BA_ "GenSigSendType" SG_ 1585 usrData2_TMF 0;
BA_ "GenSigSendType" SG_ 1585 ECUSPEC_AWAKE_TMF 0;
BA_ "GenSigSendType" SG_ 1585 DIAGNOSTIC_AWAKE_TMF 0;
BA_ "GenSigSendType" SG_ 1585 IGNITION_AWAKE_TMF 0;
BA_ "GenSigSendType" SG_ 1585 NETWORK_AWAKE_TMF 0;
BA_ "GenSigSendType" SG_ 1585 ECUSPEC_WAKEUP_TMF 0;
BA_ "GenSigSendType" SG_ 1585 NETWORK_WAKEUP_TMF 0;
BA_ "GenSigSendType" SG_ 1585 RESET_WAKEUP_TMF 0;
BA_ "GenSigSendType" SG_ 1585 IGNITION_WAKEUP_TMF 0;
BA_ "GenSigSendType" SG_ 1585 usrData0_TMF 0;
BA_ "GenSigSendType" SG_ 1585 NMm_TMF_Reserved1 0;
BA_ "GenSigSendType" SG_ 1585 RMR_TMF 0;
BA_ "GenSigSendType" SG_ 1585 srcNodeID_TMF 0;
BA_ "GenSigStartValue" SG_ 1585 srcNodeID_TMF 2;
BA_ "GenSigSendType" SG_ 1580 usrData5_ISG 0;
BA_ "GenSigSendType" SG_ 1580 usrData4_ISG 0;
BA_ "GenSigSendType" SG_ 1580 usrData3_ISG 0;
BA_ "GenSigSendType" SG_ 1580 usrData2_ISG 0;
BA_ "GenSigSendType" SG_ 1580 ECUSPEC_AWAKE_ISG 0;
BA_ "GenSigSendType" SG_ 1580 DIAGNOSTIC_AWAKE_ISG 0;
BA_ "GenSigSendType" SG_ 1580 IGNITION_AWAKE_ISG 0;
BA_ "GenSigSendType" SG_ 1580 NETWORK_AWAKE_ISG 0;
BA_ "GenSigSendType" SG_ 1580 ECUSPEC_WAKEUP_ISG 0;
BA_ "GenSigSendType" SG_ 1580 NETWORK_WAKEUP_ISG 0;
BA_ "GenSigSendType" SG_ 1580 RESET_WAKEUP_ISG 0;
BA_ "GenSigSendType" SG_ 1580 IGNITION_WAKEUP_ISG 0;
BA_ "GenSigSendType" SG_ 1580 usrData0_ISG 0;
BA_ "GenSigSendType" SG_ 1580 NMm_ISGReserved1 0;
BA_ "GenSigSendType" SG_ 1580 RMR_ISG 0;
BA_ "GenSigSendType" SG_ 1580 srcNodeID_ISG 0;
BA_ "GenSigStartValue" SG_ 1580 srcNodeID_ISG 2;
BA_ "GenSigSendType" SG_ 1551 usrData5_BMS 0;
BA_ "GenSigSendType" SG_ 1551 usrData4_BMS 0;
BA_ "GenSigSendType" SG_ 1551 usrData3_BMS 0;
BA_ "GenSigSendType" SG_ 1551 usrData2_BMS 0;
BA_ "GenSigSendType" SG_ 1551 ECUSPEC_AWAKE_BMS 0;
BA_ "GenSigSendType" SG_ 1551 DIAGNOSTIC_AWAKE_BMS 0;
BA_ "GenSigSendType" SG_ 1551 IGNITION_AWAKE_BMS 0;
BA_ "GenSigSendType" SG_ 1551 NETWORK_AWAKE_BMS 0;
BA_ "GenSigSendType" SG_ 1551 ECUSPEC_WAKEUP_BMS 0;
BA_ "GenSigSendType" SG_ 1551 NETWORK_WAKEUP_BMS 0;
BA_ "GenSigSendType" SG_ 1551 RESET_WAKEUP_BMS 0;
BA_ "GenSigSendType" SG_ 1551 IGNITION_WAKEUP_BMS 0;
BA_ "GenSigSendType" SG_ 1551 usrData0_BMS 0;
BA_ "GenSigSendType" SG_ 1551 NMm_BMS_Reserved1 0;
BA_ "GenSigSendType" SG_ 1551 RMR_BMS 0;
BA_ "GenSigSendType" SG_ 1551 srcNodeID_BMS 0;
BA_ "GenSigStartValue" SG_ 1551 srcNodeID_BMS 2;
BA_ "GenSigSendType" SG_ 1550 usrData5_HCU 0;
BA_ "GenSigSendType" SG_ 1550 usrData4_HCU 0;
BA_ "GenSigSendType" SG_ 1550 usrData3_HCU 0;
BA_ "GenSigSendType" SG_ 1550 usrData2_HCU 0;
BA_ "GenSigSendType" SG_ 1550 ECUSPEC_AWAKE_HCU 0;
BA_ "GenSigSendType" SG_ 1550 DIAGNOSTIC_AWAKE_HCU 0;
BA_ "GenSigSendType" SG_ 1550 IGNITION_AWAKE_HCU 0;
BA_ "GenSigSendType" SG_ 1550 NETWORK_AWAKE_HCU 0;
BA_ "GenSigSendType" SG_ 1550 ECUSPEC_WAKEUP_HCU 0;
BA_ "GenSigSendType" SG_ 1550 NETWORK_WAKEUP_HCU 0;
BA_ "GenSigSendType" SG_ 1550 RESET_WAKEUP_HCU 0;
BA_ "GenSigSendType" SG_ 1550 IGNITION_WAKEUP_HCU 0;
BA_ "GenSigSendType" SG_ 1550 usrData0_HCU 0;
BA_ "GenSigSendType" SG_ 1550 NMm_HCU_Reserved1 0;
BA_ "GenSigSendType" SG_ 1550 RMR_HCU 0;
BA_ "GenSigSendType" SG_ 1550 srcNodeID_HCU 0;
BA_ "GenSigStartValue" SG_ 1550 srcNodeID_HCU 2;
BA_ "GenSigSendType" SG_ 1381 BMS_BattTempSensorOrder48 0;
BA_ "GenSigSendType" SG_ 1381 BMS_BattTempSensorOrder47 0;
BA_ "GenSigSendType" SG_ 1381 BMS_BattTempSensorOrder46 0;
BA_ "GenSigSendType" SG_ 1381 BMS_BattTempSensorOrder45 0;
BA_ "GenSigSendType" SG_ 1381 BMS_BattTempSensorOrder44 0;
BA_ "GenSigSendType" SG_ 1381 BMS_BattTempSensorOrder43 0;
BA_ "GenSigSendType" SG_ 1381 BMS_BattTempSensorOrder42 0;
BA_ "GenSigSendType" SG_ 1381 BMS_BattTempSensorOrder41 0;
BA_ "GenSigSendType" SG_ 1380 BMS_BattTempSensorOrder40 0;
BA_ "GenSigSendType" SG_ 1380 BMS_BattTempSensorOrder39 0;
BA_ "GenSigSendType" SG_ 1380 BMS_BattTempSensorOrder38 0;
BA_ "GenSigSendType" SG_ 1380 BMS_BattTempSensorOrder37 0;
BA_ "GenSigSendType" SG_ 1380 BMS_BattTempSensorOrder36 0;
BA_ "GenSigSendType" SG_ 1380 BMS_BattTempSensorOrder35 0;
BA_ "GenSigSendType" SG_ 1380 BMS_BattTempSensorOrder34 0;
BA_ "GenSigSendType" SG_ 1380 BMS_BattTempSensorOrder33 0;
BA_ "GenSigSendType" SG_ 1379 BMS_BattTempSensorOrder32 0;
BA_ "GenSigSendType" SG_ 1379 BMS_BattTempSensorOrder31 0;
BA_ "GenSigSendType" SG_ 1379 BMS_BattTempSensorOrder30 0;
BA_ "GenSigSendType" SG_ 1379 BMS_BattTempSensorOrder29 0;
BA_ "GenSigSendType" SG_ 1379 BMS_BattTempSensorOrder28 0;
BA_ "GenSigSendType" SG_ 1379 BMS_BattTempSensorOrder27 0;
BA_ "GenSigSendType" SG_ 1379 BMS_BattTempSensorOrder26 0;
BA_ "GenSigSendType" SG_ 1379 BMS_BattTempSensorOrder25 0;
BA_ "GenSigSendType" SG_ 1378 BMS_BattTempSensorOrder24 0;
BA_ "GenSigSendType" SG_ 1378 BMS_BattTempSensorOrder23 0;
BA_ "GenSigSendType" SG_ 1378 BMS_BattTempSensorOrder22 0;
BA_ "GenSigSendType" SG_ 1378 BMS_BattTempSensorOrder21 0;
BA_ "GenSigSendType" SG_ 1378 BMS_BattTempSensorOrder20 0;
BA_ "GenSigSendType" SG_ 1378 BMS_BattTempSensorOrder19 0;
BA_ "GenSigSendType" SG_ 1378 BMS_BattTempSensorOrder18 0;
BA_ "GenSigSendType" SG_ 1378 BMS_BattTempSensorOrder17 0;
BA_ "GenSigSendType" SG_ 1377 BMS_BattTempSensorOrder16 0;
BA_ "GenSigSendType" SG_ 1377 BMS_BattTempSensorOrder15 0;
BA_ "GenSigSendType" SG_ 1377 BMS_BattTempSensorOrder14 0;
BA_ "GenSigSendType" SG_ 1377 BMS_BattTempSensorOrder13 0;
BA_ "GenSigSendType" SG_ 1377 BMS_BattTempSensorOrder12 0;
BA_ "GenSigSendType" SG_ 1377 BMS_BattTempSensorOrder11 0;
BA_ "GenSigSendType" SG_ 1377 BMS_BattTempSensorOrder10 0;
BA_ "GenSigSendType" SG_ 1377 BMS_BattTempSensorOrder9 0;
BA_ "GenSigSendType" SG_ 1376 BMS_BattTempSensorOrder8 0;
BA_ "GenSigSendType" SG_ 1376 BMS_BattTempSensorOrder7 0;
BA_ "GenSigSendType" SG_ 1376 BMS_BattTempSensorOrder6 0;
BA_ "GenSigSendType" SG_ 1376 BMS_BattTempSensorOrder5 0;
BA_ "GenSigSendType" SG_ 1376 BMS_BattTempSensorOrder4 0;
BA_ "GenSigSendType" SG_ 1376 BMS_BattTempSensorOrder3 0;
BA_ "GenSigSendType" SG_ 1376 BMS_BattTempSensorOrder2 0;
BA_ "GenSigSendType" SG_ 1376 BMS_BattTempSensorOrder1 0;
BA_ "GenSigSendType" SG_ 1367 BMS_BattCellOrder96Vol 0;
BA_ "GenSigSendType" SG_ 1367 BMS_BattCellOrder95Vol 0;
BA_ "GenSigSendType" SG_ 1367 BMS_BattCellOrder94Vol 0;
BA_ "GenSigSendType" SG_ 1367 BMS_BattCellOrder93Vol 0;
BA_ "GenSigSendType" SG_ 1366 BMS_BattCellOrder92Vol 0;
BA_ "GenSigSendType" SG_ 1366 BMS_BattCellOrder91Vol 0;
BA_ "GenSigSendType" SG_ 1366 BMS_BattCellOrder90Vol 0;
BA_ "GenSigSendType" SG_ 1366 BMS_BattCellOrder89Vol 0;
BA_ "GenSigSendType" SG_ 1365 BMS_BattCellOrder88Vol 0;
BA_ "GenSigSendType" SG_ 1365 BMS_BattCellOrder87Vol 0;
BA_ "GenSigSendType" SG_ 1365 BMS_BattCellOrder86Vol 0;
BA_ "GenSigSendType" SG_ 1365 BMS_BattCellOrder85Vol 0;
BA_ "GenSigSendType" SG_ 1364 BMS_BattCellOrder84Vol 0;
BA_ "GenSigSendType" SG_ 1364 BMS_BattCellOrder83Vol 0;
BA_ "GenSigSendType" SG_ 1364 BMS_BattCellOrder82Vol 0;
BA_ "GenSigSendType" SG_ 1364 BMS_BattCellOrder81Vol 0;
BA_ "GenSigSendType" SG_ 1363 BMS_BattCellOrder80Vol 0;
BA_ "GenSigSendType" SG_ 1363 BMS_BattCellOrder79Vol 0;
BA_ "GenSigSendType" SG_ 1363 BMS_BattCellOrder78Vol 0;
BA_ "GenSigSendType" SG_ 1363 BMS_BattCellOrder77Vol 0;
BA_ "GenSigSendType" SG_ 1362 BMS_BattCellOrder76Vol 0;
BA_ "GenSigSendType" SG_ 1362 BMS_BattCellOrder75Vol 0;
BA_ "GenSigSendType" SG_ 1362 BMS_BattCellOrder74Vol 0;
BA_ "GenSigSendType" SG_ 1362 BMS_BattCellOrder73Vol 0;
BA_ "GenSigSendType" SG_ 1361 BMS_BattCellOrder72Vol 0;
BA_ "GenSigSendType" SG_ 1361 BMS_BattCellOrder71Vol 0;
BA_ "GenSigSendType" SG_ 1361 BMS_BattCellOrder70Vol 0;
BA_ "GenSigSendType" SG_ 1361 BMS_BattCellOrder69Vol 0;
BA_ "GenSigSendType" SG_ 1360 BMS_BattCellOrder68Vol 0;
BA_ "GenSigSendType" SG_ 1360 BMS_BattCellOrder67Vol 0;
BA_ "GenSigSendType" SG_ 1360 BMS_BattCellOrder66Vol 0;
BA_ "GenSigSendType" SG_ 1360 BMS_BattCellOrder65Vol 0;
BA_ "GenSigSendType" SG_ 1359 BMS_BattCellOrder64Vol 0;
BA_ "GenSigSendType" SG_ 1359 BMS_BattCellOrder63Vol 0;
BA_ "GenSigSendType" SG_ 1359 BMS_BattCellOrder62Vol 0;
BA_ "GenSigSendType" SG_ 1359 BMS_BattCellOrder61Vol 0;
BA_ "GenSigSendType" SG_ 1358 BMS_BattCellOrder60Vol 0;
BA_ "GenSigSendType" SG_ 1358 BMS_BattCellOrder59Vol 0;
BA_ "GenSigSendType" SG_ 1358 BMS_BattCellOrder58Vol 0;
BA_ "GenSigSendType" SG_ 1358 BMS_BattCellOrder57Vol 0;
BA_ "GenSigSendType" SG_ 1357 BMS_BattCellOrder56Vol 0;
BA_ "GenSigSendType" SG_ 1357 BMS_BattCellOrder55Vol 0;
BA_ "GenSigSendType" SG_ 1357 BMS_BattCellOrder54Vol 0;
BA_ "GenSigSendType" SG_ 1357 BMS_BattCellOrder53Vol 0;
BA_ "GenSigSendType" SG_ 1356 BMS_BattCellOrder52Vol 0;
BA_ "GenSigSendType" SG_ 1356 BMS_BattCellOrder51Vol 0;
BA_ "GenSigSendType" SG_ 1356 BMS_BattCellOrder50Vol 0;
BA_ "GenSigSendType" SG_ 1356 BMS_BattCellOrder49Vol 0;
BA_ "GenSigSendType" SG_ 1355 BMS_BattCellOrder48Vol 0;
BA_ "GenSigSendType" SG_ 1355 BMS_BattCellOrder47Vol 0;
BA_ "GenSigSendType" SG_ 1355 BMS_BattCellOrder46Vol 0;
BA_ "GenSigSendType" SG_ 1355 BMS_BattCellOrder45Vol 0;
BA_ "GenSigSendType" SG_ 1354 BMS_BattCellOrder44Vol 0;
BA_ "GenSigSendType" SG_ 1354 BMS_BattCellOrder43Vol 0;
BA_ "GenSigSendType" SG_ 1354 BMS_BattCellOrder42Vol 0;
BA_ "GenSigSendType" SG_ 1354 BMS_BattCellOrder41Vol 0;
BA_ "GenSigSendType" SG_ 1353 BMS_BattCellOrder40Vol 0;
BA_ "GenSigSendType" SG_ 1353 BMS_BattCellOrder39Vol 0;
BA_ "GenSigSendType" SG_ 1353 BMS_BattCellOrder38Vol 0;
BA_ "GenSigSendType" SG_ 1353 BMS_BattCellOrder37Vol 0;
BA_ "GenSigSendType" SG_ 1352 BMS_BattCellOrder36Vol 0;
BA_ "GenSigSendType" SG_ 1352 BMS_BattCellOrder35Vol 0;
BA_ "GenSigSendType" SG_ 1352 BMS_BattCellOrder34Vol 0;
BA_ "GenSigSendType" SG_ 1352 BMS_BattCellOrder33Vol 0;
BA_ "GenSigSendType" SG_ 1351 BMS_BattCellOrder32Vol 0;
BA_ "GenSigSendType" SG_ 1351 BMS_BattCellOrder31Vol 0;
BA_ "GenSigSendType" SG_ 1351 BMS_BattCellOrder30Vol 0;
BA_ "GenSigSendType" SG_ 1351 BMS_BattCellOrder29Vol 0;
BA_ "GenSigSendType" SG_ 1350 BMS_BattCellOrder28Vol 0;
BA_ "GenSigSendType" SG_ 1350 BMS_BattCellOrder27Vol 0;
BA_ "GenSigSendType" SG_ 1350 BMS_BattCellOrder26Vol 0;
BA_ "GenSigSendType" SG_ 1350 BMS_BattCellOrder25Vol 0;
BA_ "GenSigSendType" SG_ 1349 BMS_BattCellOrder24Vol 0;
BA_ "GenSigSendType" SG_ 1349 BMS_BattCellOrder23Vol 0;
BA_ "GenSigSendType" SG_ 1349 BMS_BattCellOrder22Vol 0;
BA_ "GenSigSendType" SG_ 1349 BMS_BattCellOrder21Vol 0;
BA_ "GenSigSendType" SG_ 1348 BMS_BattCellOrder20Vol 0;
BA_ "GenSigSendType" SG_ 1348 BMS_BattCellOrder19Vol 0;
BA_ "GenSigSendType" SG_ 1348 BMS_BattCellOrder18Vol 0;
BA_ "GenSigSendType" SG_ 1348 BMS_BattCellOrder17Vol 0;
BA_ "GenSigSendType" SG_ 1347 BMS_BattCellOrder16Vol 0;
BA_ "GenSigSendType" SG_ 1347 BMS_BattCellOrder15Vol 0;
BA_ "GenSigSendType" SG_ 1347 BMS_BattCellOrder14Vol 0;
BA_ "GenSigSendType" SG_ 1347 BMS_BattCellOrder13Vol 0;
BA_ "GenSigSendType" SG_ 1346 BMS_BattCellOrder12Vol 0;
BA_ "GenSigSendType" SG_ 1346 BMS_BattCellOrder11Vol 0;
BA_ "GenSigSendType" SG_ 1346 BMS_BattCellOrder10Vol 0;
BA_ "GenSigSendType" SG_ 1346 BMS_BattCellOrder9Vol 0;
BA_ "GenSigSendType" SG_ 1345 BMS_BattCellOrder8Vol 0;
BA_ "GenSigSendType" SG_ 1345 BMS_BattCellOrder7Vol 0;
BA_ "GenSigSendType" SG_ 1345 BMS_BattCellOrder6Vol 0;
BA_ "GenSigSendType" SG_ 1345 BMS_BattCellOrder5Vol 0;
BA_ "GenSigSendType" SG_ 1344 BMS_BattCellOrder4Vol 0;
BA_ "GenSigSendType" SG_ 1344 BMS_BattCellOrder3Vol 0;
BA_ "GenSigSendType" SG_ 1344 BMS_BattCellOrder2Vol 0;
BA_ "GenSigSendType" SG_ 1344 BMS_BattCellOrder1Vol 0;
BA_ "GenSigSendType" SG_ 1183 BMS_24_Reserved1 0;
BA_ "GenSigSendType" SG_ 1183 BMSH_PosSideWeldSts 0;
BA_ "GenSigSendType" SG_ 1183 BMSH_InsulationSts 0;
BA_ "GenSigSendType" SG_ 1183 BMSH_InterHVILSts 0;
BA_ "GenSigSendType" SG_ 1183 BMSH_stMode 0;
BA_ "GenSigSendType" SG_ 1183 BMSH_BattVolt 0;
BA_ "GenSigSendType" SG_ 1183 BMSH_BatteryCurrent 0;
BA_ "GenSigSendType" SG_ 1183 BMSH_SOC 0;
BA_ "GenSigSendType" SG_ 1475 BMSH_HardwareVersionNumber7 0;
BA_ "GenSigSendType" SG_ 1475 BMSH_HardwareVersionNumber6 0;
BA_ "GenSigSendType" SG_ 1475 BMSH_HardwareVersionNumber5 0;
BA_ "GenSigSendType" SG_ 1475 BMSH_HardwareVersionNumber4 0;
BA_ "GenSigSendType" SG_ 1475 BMSH_HardwareVersionNumber3 0;
BA_ "GenSigSendType" SG_ 1475 BMSH_HardwareVersionNumber2 0;
BA_ "GenSigSendType" SG_ 1475 BMSH_HardwareVersionNumber1 0;
BA_ "GenSigSendType" SG_ 1475 BMSH_HardwareVersionDataLength 0;
BA_ "GenSigSendType" SG_ 1475 BMSH_HardwarePacketNumber 0;
BA_ "GenSigSendType" SG_ 1474 BMSH_SoftwareVersionNumber7 0;
BA_ "GenSigSendType" SG_ 1474 BMSH_SoftwareVersionNumber6 0;
BA_ "GenSigSendType" SG_ 1474 BMSH_SoftwareVersionNumber5 0;
BA_ "GenSigSendType" SG_ 1474 BMSH_SoftwareVersionNumber4 0;
BA_ "GenSigSendType" SG_ 1474 BMSH_SoftwareVersionNumber3 0;
BA_ "GenSigSendType" SG_ 1474 BMSH_SoftwareVersionNumber2 0;
BA_ "GenSigSendType" SG_ 1474 BMSH_SoftwareVersionNumber1 0;
BA_ "GenSigSendType" SG_ 1474 BMSH_SoftwareVersionDataLength 0;
BA_ "GenSigSendType" SG_ 1474 BMSH_SoftwarePacketNumber 0;
BA_ "GenSigSendType" SG_ 1473 BMSH_BPTotalDischargeEnergy 0;
BA_ "GenSigSendType" SG_ 1473 BMSH_TotalFeedbackEnergy 0;
BA_ "GenSigSendType" SG_ 1473 BMSH_TotalChargeEnergy 0;
BA_ "GenSigSendType" SG_ 1472 BMSH_19_Reserved1 0;
BA_ "GenSigSendType" SG_ 1472 BMSH_CellSensor_TotalNum 0;
BA_ "GenSigSendType" SG_ 1472 BMSH_SingleFeedbackEnergy 0;
BA_ "GenSigSendType" SG_ 1472 BMSH_SingleDisChargeEnergy 0;
BA_ "GenSigSendType" SG_ 1472 BMSH_SingleChargeEnergy 0;
BA_ "GenSigSendType" SG_ 1458 BMS_DTCOrder6 0;
BA_ "GenSigSendType" SG_ 1458 BMS_DTCOrder5 0;
BA_ "GenSigSendType" SG_ 1457 BMS_DTCOrder4 0;
BA_ "GenSigSendType" SG_ 1457 BMS_DTCOrder3 0;
BA_ "GenSigSendType" SG_ 1456 BMS_DTCTotalNum 0;
BA_ "GenSigSendType" SG_ 1456 BMS_DTCOrder2 0;
BA_ "GenSigSendType" SG_ 1456 BMS_DTCOrder1 0;
BA_ "GenSigSendType" SG_ 1454 BMS_SubsymCodeOrder24 0;
BA_ "GenSigSendType" SG_ 1454 BMS_SubsymCodeOrder23 0;
BA_ "GenSigSendType" SG_ 1454 BMS_SubsymCodeOrder22 0;
BA_ "GenSigSendType" SG_ 1454 BMS_SubsymCodeOrder21 0;
BA_ "GenSigSendType" SG_ 1454 BMS_SubsymCodeOrder20 0;
BA_ "GenSigSendType" SG_ 1454 BMS_SubsymCodeOrder19 0;
BA_ "GenSigSendType" SG_ 1454 BMS_SubsymCodeFrameTotalNum 0;
BA_ "GenSigSendType" SG_ 1454 BMS_SubsymCodeFrameOrder4 0;
BA_ "GenSigSendType" SG_ 1453 BMS_SubsymCodeOrder18 0;
BA_ "GenSigSendType" SG_ 1453 BMS_SubsymCodeOrder17 0;
BA_ "GenSigSendType" SG_ 1453 BMS_SubsymCodeOrder16 0;
BA_ "GenSigSendType" SG_ 1453 BMS_SubsymCodeOrder15 0;
BA_ "GenSigSendType" SG_ 1453 BMS_SubsymCodeOrder14 0;
BA_ "GenSigSendType" SG_ 1453 BMS_SubsymCodeOrder13 0;
BA_ "GenSigSendType" SG_ 1453 BMS_SubsymCodeFrameTotalNum 0;
BA_ "GenSigSendType" SG_ 1453 BMS_SubsymCodeFrameOrder3 0;
BA_ "GenSigSendType" SG_ 1452 BMS_SubsymCodeOrder12 0;
BA_ "GenSigSendType" SG_ 1452 BMS_SubsymCodeOrder11 0;
BA_ "GenSigSendType" SG_ 1452 BMS_SubsymCodeOrder10 0;
BA_ "GenSigSendType" SG_ 1452 BMS_SubsymCodeOrder9 0;
BA_ "GenSigSendType" SG_ 1452 BMS_SubsymCodeOrder8 0;
BA_ "GenSigSendType" SG_ 1452 BMS_SubsymCodeOrder7 0;
BA_ "GenSigSendType" SG_ 1452 BMS_SubsymCodeFrameTotalNum 0;
BA_ "GenSigSendType" SG_ 1452 BMS_SubsymCodeFrameOrder2 0;
BA_ "GenSigSendType" SG_ 1451 BMS_SubsymCodeOrder6 0;
BA_ "GenSigSendType" SG_ 1451 BMS_SubsymCodeOrder5 0;
BA_ "GenSigSendType" SG_ 1451 BMS_SubsymCodeOrder4 0;
BA_ "GenSigSendType" SG_ 1451 BMS_SubsymCodeOrder3 0;
BA_ "GenSigSendType" SG_ 1451 BMS_SubsymCodeOrder2 0;
BA_ "GenSigSendType" SG_ 1451 BMS_SubsymCodeOrder1 0;
BA_ "GenSigSendType" SG_ 1451 BMS_SubsymCodeFrameTotalNum 0;
BA_ "GenSigSendType" SG_ 1451 BMS_SubsymCodeFrameOrder1 0;
BA_ "GenSigSendType" SG_ 1450 BMSH_BalanceActive 0;
BA_ "GenSigSendType" SG_ 1450 BMSH_Battery_Uniformity 0;
BA_ "GenSigSendType" SG_ 1450 BMSH_StoredEnergySys 0;
BA_ "GenSigSendType" SG_ 1450 BMSH_Charge_Over 0;
BA_ "GenSigSendType" SG_ 1450 BMSH_HVILcuitFailure 0;
BA_ "GenSigSendType" SG_ 1450 BMSH_Battery_Mismatching 0;
BA_ "GenSigSendType" SG_ 1450 BMSH_BatteryTempLightSts 0;
BA_ "GenSigSendType" SG_ 1450 BMSH_Charge_Over_Current 0;
BA_ "GenSigSendType" SG_ 1450 BMSH_Discharge_Over_Current 0;
BA_ "GenSigSendType" SG_ 1450 BMSH_IsocircuitFailure 0;
BA_ "GenSigSendType" SG_ 1450 BMSH_Cell_Voltage_Uniformity 0;
BA_ "GenSigSendType" SG_ 1450 BMSH_LowSOC 0;
BA_ "GenSigSendType" SG_ 1450 BMSH_CellUnderVol 0;
BA_ "GenSigSendType" SG_ 1450 BMSH_CellOverVol 0;
BA_ "GenSigSendType" SG_ 1450 BMSH_OverSOC 0;
BA_ "GenSigSendType" SG_ 1450 BMSH_Battery_Under_Voltage 0;
BA_ "GenSigSendType" SG_ 1450 BMSH_Battery_Over_Voltage 0;
BA_ "GenSigSendType" SG_ 1450 BMSH_Low_Temperature 0;
BA_ "GenSigSendType" SG_ 1450 BMSH_Over_Temperature 0;
BA_ "GenSigSendType" SG_ 1450 BMSH_PacksubsystemVolt 0;
BA_ "GenSigSendType" SG_ 1450 BMSH_SOC_Jump 0;
BA_ "GenSigSendType" SG_ 1450 BMSH_PacksubsystemCurrent 0;
BA_ "GenSigSendType" SG_ 1450 BMSH_TempUniformity 0;
BA_ "GenSigSendType" SG_ 1449 BMSH_CellVoltMin 0;
BA_ "GenSigSendType" SG_ 1449 BMSH_CellVoltMax 0;
BA_ "GenSigSendType" SG_ 1449 BMSH_CellVoltMin_Num 0;
BA_ "GenSigSendType" SG_ 1449 BMSH_CellVoltMax_Num 0;
BA_ "GenSigSendType" SG_ 1449 BMSH_VoltMin_Num 0;
BA_ "GenSigSendType" SG_ 1449 BMSH_VoltMax_Num 0;
BA_ "GenSigSendType" SG_ 1448 BMSH_TempMin_Num 0;
BA_ "GenSigSendType" SG_ 1448 BMSH_TempMax_Num 0;
BA_ "GenSigSendType" SG_ 1448 BMSH_TempSensor_MinTemp 0;
BA_ "GenSigStartValue" SG_ 1448 BMSH_TempSensor_MinTemp 40;
BA_ "GenSigSendType" SG_ 1448 BMSH_TempSensor_TempMinNum 0;
BA_ "GenSigSendType" SG_ 1448 BMSH_TempSensor_MaxTemp 0;
BA_ "GenSigStartValue" SG_ 1448 BMSH_TempSensor_MaxTemp 40;
BA_ "GenSigSendType" SG_ 1448 BMSH_TempSensor_TempMaxNum 0;
BA_ "GenSigSendType" SG_ 1448 BMSH_TempSensor_TotalNum 0;
BA_ "GenSigSendType" SG_ 1448 BMSH_BattTempAvg 0;
BA_ "GenSigStartValue" SG_ 1448 BMSH_BattTempAvg 40;
BA_ "GenSigSendType" SG_ 1436 BMSH_InsulationResis 0;
BA_ "GenSigSendType" SG_ 1436 BMSH_BattTypeCode 0;
BA_ "GenSigSendType" SG_ 1436 BMSH_batteryDataFrameNumSum 0;
BA_ "GenSigSendType" SG_ 1436 BMSH_batteryDataFrameNum 0;
BA_ "GenSigSendType" SG_ 1436 BMSH_PacksubsystemNum 0;
BA_ "GenSigSendType" SG_ 1436 BMS_9_Reserved1 0;
BA_ "GenSigSendType" SG_ 1436 BMSH_PackCellSum 0;
BA_ "GenSigSendType" SG_ 1436 BMSH_PackCodeLength 0;
BA_ "GenSigSendType" SG_ 1436 BMSH_PackSubsystemSum 0;
BA_ "GenSigSendType" SG_ 1103 BMSH_8_CRC 0;
BA_ "GenSigSendType" SG_ 1103 BMSH_8_MessageCounter 0;
BA_ "GenSigSendType" SG_ 1103 BMSH_8_Reserved1 0;
BA_ "GenSigSendType" SG_ 1103 BMSH_LeftChargeTime 0;
BA_ "GenSigSendType" SG_ 1103 BMSH_PackInstantRecoveryPower 0;
BA_ "GenSigSendType" SG_ 1103 BMSH_PackInstantOutPower 0;
BA_ "GenSigSendType" SG_ 1096 BMSH_7_CRC 0;
BA_ "GenSigSendType" SG_ 1096 BMSH_7_MessageCounter 0;
BA_ "GenSigSendType" SG_ 1096 BMSH_ChargeEnable 0;
BA_ "GenSigSendType" SG_ 1096 BMSH_BatteryMaintainLightReq 0;
BA_ "GenSigSendType" SG_ 1096 BMSH_ChargeReq 0;
BA_ "GenSigSendType" SG_ 1096 BMS_BattWarmRequest 0;
BA_ "GenSigSendType" SG_ 1096 BMSH_ChargeOutMinCurSet 0;
BA_ "GenSigSendType" SG_ 1096 BMSH_ChargeOutMaxCurSet 0;
BA_ "GenSigSendType" SG_ 1096 BMSH_ChargeOutVolSet 0;
BA_ "GenSigSendType" SG_ 1091 BMSH_6_CRC 0;
BA_ "GenSigSendType" SG_ 1091 BMSH_6_MessageCounter 0;
BA_ "GenSigSendType" SG_ 1091 BMSH_WaterTempChangeRateReq 0;
BA_ "GenSigSendType" SG_ 1091 BMSH_6_Reserved1 0;
BA_ "GenSigSendType" SG_ 1091 BMSH_OutletWaterTempValid 0;
BA_ "GenSigSendType" SG_ 1091 BMSH_InletWaterTempValid 0;
BA_ "GenSigSendType" SG_ 1091 BMSH_PackThermalSensorSts 0;
BA_ "GenSigSendType" SG_ 1091 BMSH_ThermalManageReq 0;
BA_ "GenSigSendType" SG_ 1091 BMSH_FlowRateReq 0;
BA_ "GenSigSendType" SG_ 1091 BMSH_HeatPowerReq 0;
BA_ "GenSigSendType" SG_ 1091 BMSH_InletWaterTempTarget 0;
BA_ "GenSigStartValue" SG_ 1091 BMSH_InletWaterTempTarget 40;
BA_ "GenSigSendType" SG_ 1091 BMSH_OutletWaterTemp 0;
BA_ "GenSigStartValue" SG_ 1091 BMSH_OutletWaterTemp 40;
BA_ "GenSigSendType" SG_ 1091 BMSH_InletWaterTemp 0;
BA_ "GenSigStartValue" SG_ 1091 BMSH_InletWaterTemp 40;
BA_ "GenSigSendType" SG_ 1083 BMSH_5_CRC 0;
BA_ "GenSigSendType" SG_ 1083 BMSH_5_MessageCounter 0;
BA_ "GenSigSendType" SG_ 1083 BMSH_PackMileRemain 0;
BA_ "GenSigSendType" SG_ 1083 BMSH_PackRemainEnergy 0;
BA_ "GenSigSendType" SG_ 1083 BMSH_PackFaultLevel 0;
BA_ "GenSigSendType" SG_ 1083 BMSH_MILReq 0;
BA_ "GenSigSendType" SG_ 1083 BMSH_BattFaultLampSts 0;
BA_ "GenSigSendType" SG_ 1083 BMSH_PackThermalRunawayLight 0;
BA_ "GenSigSendType" SG_ 1083 BMSH_DisChgFaultLevel 0;
BA_ "GenSigSendType" SG_ 1083 BMSH_ChgFaultLevel 0;
BA_ "GenSigSendType" SG_ 1083 BMSH_SOCDisp 0;
BA_ "GenSigSendType" SG_ 427 BMSH_4_Reserved1 0;
BA_ "GenSigSendType" SG_ 427 BMSH_MaxChargeCurrent 0;
BA_ "GenSigStartValue" SG_ 427 BMSH_MaxChargeCurrent 32000;
BA_ "GenSigSendType" SG_ 427 BMSH_MaxDischargeCurrent 0;
BA_ "GenSigStartValue" SG_ 427 BMSH_MaxDischargeCurrent 32000;
BA_ "GenSigSendType" SG_ 427 BMSH_MaxDchgPwrCont 0;
BA_ "GenSigSendType" SG_ 427 BMSH_MaxDchgPwrPeak 0;
BA_ "GenSigSendType" SG_ 420 BMSH_3_Reserved1 0;
BA_ "GenSigSendType" SG_ 420 BMSH_MainPrechgResistanceSts 0;
BA_ "GenSigSendType" SG_ 420 BMSH_PTCFuseSts 0;
BA_ "GenSigSendType" SG_ 420 BMSH_RmcuFuseSts 0;
BA_ "GenSigSendType" SG_ 420 BMSH_FmcuFuseSts 0;
BA_ "GenSigSendType" SG_ 420 BMSH_BattVoltMinLimt 0;
BA_ "GenSigSendType" SG_ 420 BMSH_BattVoltMaxLimt 0;
BA_ "GenSigSendType" SG_ 420 BMSH_MaxChgPwrCont 0;
BA_ "GenSigSendType" SG_ 420 BMSH_MaxChgPwrPeak 0;
BA_ "GenSigSendType" SG_ 411 BMSH_2_CRC 0;
BA_ "GenSigSendType" SG_ 411 BMSH_2_MessageCounter 0;
BA_ "GenSigSendType" SG_ 411 BMSH_BookSetReq 0;
BA_ "GenSigSendType" SG_ 411 BMSH_PTCRelayWeldSts 0;
BA_ "GenSigSendType" SG_ 411 BMSH_CHGPrechargeWeldSts 0;
BA_ "GenSigSendType" SG_ 411 BMSH_PreChargeWeldSts 0;
BA_ "GenSigSendType" SG_ 411 BMSH_NegSideWeldSts 0;
BA_ "GenSigSendType" SG_ 411 BMSH_PosSideWeldSts 0;
BA_ "GenSigSendType" SG_ 411 BMSH_PTCRelaySts 0;
BA_ "GenSigSendType" SG_ 411 BMSH_CHGPrechargeRelaySts 0;
BA_ "GenSigSendType" SG_ 411 BMSH_PrechargeRelaySts 0;
BA_ "GenSigSendType" SG_ 411 BMSH_NegMainRelaySts 0;
BA_ "GenSigSendType" SG_ 411 BMSH_PosMainRelaySts 0;
BA_ "GenSigSendType" SG_ 411 BMSH_IntelligentChargeReq 0;
BA_ "GenSigSendType" SG_ 411 BMSH_OBCPrechgSt 0;
BA_ "GenSigSendType" SG_ 411 BMSH_MainPrechgSt 0;
BA_ "GenSigSendType" SG_ 411 BMSH_InsulationSts 0;
BA_ "GenSigSendType" SG_ 411 BMSH_VehicleHVILSts 0;
BA_ "GenSigSendType" SG_ 411 BMSH_InterHVILSts 0;
BA_ "GenSigSendType" SG_ 411 BMSH_stMode 0;
BA_ "GenSigSendType" SG_ 411 BMSH_SOH 0;
BA_ "GenSigSendType" SG_ 411 BMSH_HVBusVolt 0;
BA_ "GenSigSendType" SG_ 403 BMSH_1_CRC 0;
BA_ "GenSigSendType" SG_ 403 BMSH_1_MessageCounter 0;
BA_ "GenSigSendType" SG_ 403 BMSH_1_Reserved1 0;
BA_ "GenSigSendType" SG_ 403 BMSH_WorkingMode 0;
BA_ "GenSigSendType" SG_ 403 BMSH_BattVolt 0;
BA_ "GenSigSendType" SG_ 403 BMSH_BatteryCurrent 0;
BA_ "GenSigSendType" SG_ 403 BMSH_SOC 0;
BA_ "GenSigSendType" SG_ 1084 OBC_ChargeSourceMode 0;
BA_ "GenSigSendType" SG_ 1084 OBC_FaultCode 0;
BA_ "GenSigSendType" SG_ 1084 OBC_MaxOutputVoltage 0;
BA_ "GenSigSendType" SG_ 1084 OBC_MaxOutputCurrent 0;
BA_ "GenSigSendType" SG_ 1067 OBC_WorkingMode 0;
BA_ "GenSigSendType" SG_ 1067 OBC_ElectronicLockSts 0;
BA_ "GenSigSendType" SG_ 1067 OBC_CC_ConnectSts 0;
BA_ "GenSigSendType" SG_ 1067 OBC_CP_DutyCycleFault 0;
BA_ "GenSigSendType" SG_ 1067 OBC_CP_DutyCycleValue 0;
BA_ "GenSigSendType" SG_ 1064 OBC_KL30_UnderVolt 0;
BA_ "GenSigSendType" SG_ 1064 OBC_InputVolt 0;
BA_ "GenSigSendType" SG_ 1064 OBC_InputCurr 0;
BA_ "GenSigSendType" SG_ 1061 OBC_FaultLevelSts 0;
BA_ "GenSigSendType" SG_ 1061 OBC_ChgSts 0;
BA_ "GenSigSendType" SG_ 1061 OBC_OutputPowerLimt 0;
BA_ "GenSigSendType" SG_ 1061 OBC_ChgVolt 0;
BA_ "GenSigSendType" SG_ 1061 OBC_ChgCurr 0;
BA_ "GenSigSendType" SG_ 1048 DCDC_LvSideCurr 0;
BA_ "GenSigSendType" SG_ 1048 DCDC_LvSideVolt 0;
BA_ "GenSigSendType" SG_ 808 TMR_VoltageHV 0;
BA_ "GenSigSendType" SG_ 808 TMR_CurrentHV 0;
BA_ "GenSigStartValue" SG_ 808 TMR_CurrentHV 1023;
BA_ "GenSigSendType" SG_ 371 TMR_State 0;
BA_ "GenSigSendType" SG_ 795 TMF_UdcAct 0;
BA_ "GenSigSendType" SG_ 795 TMF_IdcAct 0;
BA_ "GenSigStartValue" SG_ 795 TMF_IdcAct 1023;
BA_ "GenSigSendType" SG_ 348 TMF_ModeSt 0;
BA_ "GenSigSendType" SG_ 786 ISGF_UdcAct 0;
BA_ "GenSigSendType" SG_ 786 ISGF_IdcAct 0;
BA_ "GenSigStartValue" SG_ 786 ISGF_IdcAct 1023;
BA_ "GenSigSendType" SG_ 326 ISGF_ModeSt 0;
BA_ "GenSigSendType" SG_ 264 HCU_BattHeatAllow 0;
BA_ "GenSigSendType" SG_ 264 HCU_VehicleAllowToCharge 0;
BA_ "GenSigSendType" SG_ 264 HCU_BMS_stModeReq 0;
BA_ "GenSigSendType" SG_ 264 HCU_BattHVHAllow 0;
BA_ "GenSigSendType" SG_ 264 HCU_AccessoriesCosumePower 0;
VAL_ 800 CrashOutputSts 16 " Rear Crash" 8 " Right Side Crash" 4 " Left Side Crash" 2 " Front Crash" 1 " Belt Crash" 0 " No crash" ;
VAL_ 1333 ExternalTemperatureFailSts_GS 3 " Reserved" 2 " Short Power (Open circuit)" 1 " Short Ground" 0 " Fail Not Present" ;
VAL_ 1583 ECUSPEC_AWAKE_CDU 1 " Active" 0 " Inactive" ;
VAL_ 1583 DIAGNOSTIC_AWAKE_CDU 1 " Active" 0 " Inactive" ;
VAL_ 1583 IGNITION_AWAKE_CDU 1 " Active" 0 " Inactive" ;
VAL_ 1583 NETWORK_AWAKE_CDU 1 " Active" 0 " Inactive" ;
VAL_ 1583 ECUSPEC_WAKEUP_CDU 1 " Active" 0 " Inactive" ;
VAL_ 1583 NETWORK_WAKEUP_CDU 1 " Active" 0 " Inactive" ;
VAL_ 1583 RESET_WAKEUP_CDU 1 " Active" 0 " Inactive" ;
VAL_ 1583 IGNITION_WAKEUP_CDU 1 " Active" 0 " Inactive" ;
VAL_ 1583 usrData0_CDU 254 " Not Used" 253 " Not Used" 252 " Not Used" 251 " Not Used" 250 " Not Used" 249 " Not Used" 248 " Not Used" 247 " Not Used" 246 " Not Used" 245 " Not Used" 244 " Not Used" 243 " Not Used" 242 " Not Used" 241 " Not Used" 240 " Not Used" 239 " Not Used" 238 " Not Used" 237 " Not Used" 236 " Not Used" 235 " Not Used" 234 " Not Used" 233 " Not Used" 232 " Not Used" 231 " Not Used" 230 " Not Used" 229 " Not Used" 228 " Not Used" 227 " Not Used" 226 " Not Used" 225 " Not Used" 224 " Not Used" 223 " Not Used" 222 " Not Used" 221 " Not Used" 220 " Not Used" 219 " Not Used" 218 " Not Used" 217 " Not Used" 216 " Not Used" 215 " Not Used" 214 " Not Used" 213 " Not Used" 212 " Not Used" 211 " Not Used" 210 " Not Used" 209 " Not Used" 208 " Not Used" 207 " Not Used" 206 " Not Used" 205 " Not Used" 204 " Not Used" 203 " Not Used" 202 " Not Used" 201 " Not Used" 200 " Not Used" 199 " Not Used" 198 " Not Used" 197 " Not Used" 196 " Not Used" 195 " Not Used" 194 " Not Used" 193 " Not Used" 192 " Not Used" 191 " Not Used" 190 " Not Used" 189 " Not Used" 188 " Not Used" 187 " Not Used" 186 " Not Used" 185 " Not Used" 184 " Not Used" 183 " Not Used" 182 " Not Used" 181 " Not Used" 180 " Not Used" 179 " Not Used" 178 " Not Used" 177 " Not Used" 176 " Not Used" 175 " Not Used" 174 " Not Used" 173 " Not Used" 172 " Not Used" 171 " Not Used" 170 " Not Used" 169 " Not Used" 168 " Not Used" 167 " Not Used" 166 " Not Used" 165 " Not Used" 164 " Not Used" 163 " Not Used" 162 " Not Used" 161 " Not Used" 160 " Not Used" 159 " Not Used" 158 " Not Used" 157 " Not Used" 156 " Not Used" 155 " Not Used" 154 " Not Used" 153 " Not Used" 152 " Not Used" 151 " Not Used" 150 " Not Used" 149 " Not Used" 148 " Not Used" 147 " Not Used" 146 " Not Used" 145 " Not Used" 144 " Not Used" 143 " Not Used" 142 " Not Used" 141 " Not Used" 140 " Not Used" 139 " Not Used" 138 " Not Used" 137 " Not Used" 136 " Not Used" 135 " Not Used" 134 " Not Used" 133 " Not Used" 132 " Not Used" 131 " Not Used" 130 " Not Used" 129 " Not Used" 128 " Not Used" 127 " Not Used" 126 " Not Used" 125 " Not Used" 124 " Not Used" 123 " Not Used" 122 " Not Used" 121 " Not Used" 120 " Not Used" 119 " Not Used" 118 " Not Used" 117 " Not Used" 116 " Not Used" 115 " Not Used" 114 " Not Used" 113 " Not Used" 112 " Not Used" 111 " Not Used" 110 " Not Used" 109 " Not Used" 108 " Not Used" 107 " Not Used" 106 " Not Used" 105 " Not Used" 104 " Not Used" 103 " Not Used" 102 " Not Used" 101 " Not Used" 100 " Not Used" 99 " Not Used" 98 " Not Used" 97 " Not Used" 96 " Not Used" 95 " Not Used" 94 " Not Used" 93 " Not Used" 92 " Not Used" 91 " Not Used" 90 " Not Used" 89 " Not Used" 88 " Not Used" 87 " Not Used" 86 " Not Used" 85 " Not Used" 84 " Not Used" 83 " Not Used" 82 " Not Used" 81 " Not Used" 80 " Not Used" 79 " Not Used" 78 " Not Used" 77 " Not Used" 76 " Not Used" 75 " Not Used" 74 " Not Used" 73 " Not Used" 72 " Not Used" 71 " Not Used" 70 " Not Used" 69 " Not Used" 68 " Not Used" 67 " Not Used" 66 " Not Used" 65 " Not Used" 64 " Not Used" 63 " Not Used" 62 " Not Used" 61 " Not Used" 60 " Not Used" 59 " Not Used" 58 " Not Used" 57 " Not Used" 56 " Not Used" 55 " Not Used" 54 " Not Used" 53 " Not Used" 52 " Not Used" 51 " Not Used" 50 " Not Used" 49 " Not Used" 48 " Not Used" 47 " Not Used" 46 " Not Used" 45 " Not Used" 44 " Not Used" 43 " Not Used" 42 " Not Used" 41 " Not Used" 40 " Not Used" 39 " Not Used" 38 " Not Used" 37 " Not Used" 36 " Not Used" 35 " Not Used" 34 " Not Used" 33 " Not Used" 32 " Not Used" 31 " Not Used" 30 " Not Used" 29 " Not Used" 28 " Not Used" 27 " Not Used" 26 " Not Used" 25 " Not Used" 24 " Not Used" 23 " Not Used" 22 " Not Used" 21 " Not Used" 20 " Not Used" 19 " Not Used" 18 " Not Used" 17 " Not Used" 16 " Not Used" 15 " Not Used" 14 " Not Used" 13 " Not Used" 12 " Not Used" 11 " Not Used" 10 " Not Used" 9 " Not Used" 8 " Not Used" 7 " Not Used" 6 " Not Used" 5 " Not Used" 4 " Not Used" 3 " Not Used" 2 " Not Used" 1 " Not Used" 255 " User data not used" 0 " User data for current vehicle" ;
VAL_ 1583 RMR_CDU 1 " Active" 0 " Inactive" ;
VAL_ 1582 ECUSPEC_AWAKE_MCUR 1 " Active" 0 " Inactive" ;
VAL_ 1582 DIAGNOSTIC_AWAKE_MCUR 1 " Active" 0 " Inactive" ;
VAL_ 1582 IGNITION_AWAKE_MCUR 1 " Active" 0 " Inactive" ;
VAL_ 1582 NETWORK_AWAKE_MCUR 1 " Active" 0 " Inactive" ;
VAL_ 1582 ECUSPEC_WAKEUP_MCUR 1 " Active" 0 " Inactive" ;
VAL_ 1582 NETWORK_WAKEUP_MCUR 1 " Active" 0 " Inactive" ;
VAL_ 1582 RESET_WAKEUP_MCUR 1 " Active" 0 " Inactive" ;
VAL_ 1582 IGNITION_WAKEUP_MCUR 1 " Active" 0 " Inactive" ;
VAL_ 1582 usrData0_MCUR 254 " Not Used" 253 " Not Used" 252 " Not Used" 251 " Not Used" 250 " Not Used" 249 " Not Used" 248 " Not Used" 247 " Not Used" 246 " Not Used" 245 " Not Used" 244 " Not Used" 243 " Not Used" 242 " Not Used" 241 " Not Used" 240 " Not Used" 239 " Not Used" 238 " Not Used" 237 " Not Used" 236 " Not Used" 235 " Not Used" 234 " Not Used" 233 " Not Used" 232 " Not Used" 231 " Not Used" 230 " Not Used" 229 " Not Used" 228 " Not Used" 227 " Not Used" 226 " Not Used" 225 " Not Used" 224 " Not Used" 223 " Not Used" 222 " Not Used" 221 " Not Used" 220 " Not Used" 219 " Not Used" 218 " Not Used" 217 " Not Used" 216 " Not Used" 215 " Not Used" 214 " Not Used" 213 " Not Used" 212 " Not Used" 211 " Not Used" 210 " Not Used" 209 " Not Used" 208 " Not Used" 207 " Not Used" 206 " Not Used" 205 " Not Used" 204 " Not Used" 203 " Not Used" 202 " Not Used" 201 " Not Used" 200 " Not Used" 199 " Not Used" 198 " Not Used" 197 " Not Used" 196 " Not Used" 195 " Not Used" 194 " Not Used" 193 " Not Used" 192 " Not Used" 191 " Not Used" 190 " Not Used" 189 " Not Used" 188 " Not Used" 187 " Not Used" 186 " Not Used" 185 " Not Used" 184 " Not Used" 183 " Not Used" 182 " Not Used" 181 " Not Used" 180 " Not Used" 179 " Not Used" 178 " Not Used" 177 " Not Used" 176 " Not Used" 175 " Not Used" 174 " Not Used" 173 " Not Used" 172 " Not Used" 171 " Not Used" 170 " Not Used" 169 " Not Used" 168 " Not Used" 167 " Not Used" 166 " Not Used" 165 " Not Used" 164 " Not Used" 163 " Not Used" 162 " Not Used" 161 " Not Used" 160 " Not Used" 159 " Not Used" 158 " Not Used" 157 " Not Used" 156 " Not Used" 155 " Not Used" 154 " Not Used" 153 " Not Used" 152 " Not Used" 151 " Not Used" 150 " Not Used" 149 " Not Used" 148 " Not Used" 147 " Not Used" 146 " Not Used" 145 " Not Used" 144 " Not Used" 143 " Not Used" 142 " Not Used" 141 " Not Used" 140 " Not Used" 139 " Not Used" 138 " Not Used" 137 " Not Used" 136 " Not Used" 135 " Not Used" 134 " Not Used" 133 " Not Used" 132 " Not Used" 131 " Not Used" 130 " Not Used" 129 " Not Used" 128 " Not Used" 127 " Not Used" 126 " Not Used" 125 " Not Used" 124 " Not Used" 123 " Not Used" 122 " Not Used" 121 " Not Used" 120 " Not Used" 119 " Not Used" 118 " Not Used" 117 " Not Used" 116 " Not Used" 115 " Not Used" 114 " Not Used" 113 " Not Used" 112 " Not Used" 111 " Not Used" 110 " Not Used" 109 " Not Used" 108 " Not Used" 107 " Not Used" 106 " Not Used" 105 " Not Used" 104 " Not Used" 103 " Not Used" 102 " Not Used" 101 " Not Used" 100 " Not Used" 99 " Not Used" 98 " Not Used" 97 " Not Used" 96 " Not Used" 95 " Not Used" 94 " Not Used" 93 " Not Used" 92 " Not Used" 91 " Not Used" 90 " Not Used" 89 " Not Used" 88 " Not Used" 87 " Not Used" 86 " Not Used" 85 " Not Used" 84 " Not Used" 83 " Not Used" 82 " Not Used" 81 " Not Used" 80 " Not Used" 79 " Not Used" 78 " Not Used" 77 " Not Used" 76 " Not Used" 75 " Not Used" 74 " Not Used" 73 " Not Used" 72 " Not Used" 71 " Not Used" 70 " Not Used" 69 " Not Used" 68 " Not Used" 67 " Not Used" 66 " Not Used" 65 " Not Used" 64 " Not Used" 63 " Not Used" 62 " Not Used" 61 " Not Used" 60 " Not Used" 59 " Not Used" 58 " Not Used" 57 " Not Used" 56 " Not Used" 55 " Not Used" 54 " Not Used" 53 " Not Used" 52 " Not Used" 51 " Not Used" 50 " Not Used" 49 " Not Used" 48 " Not Used" 47 " Not Used" 46 " Not Used" 45 " Not Used" 44 " Not Used" 43 " Not Used" 42 " Not Used" 41 " Not Used" 40 " Not Used" 39 " Not Used" 38 " Not Used" 37 " Not Used" 36 " Not Used" 35 " Not Used" 34 " Not Used" 33 " Not Used" 32 " Not Used" 31 " Not Used" 30 " Not Used" 29 " Not Used" 28 " Not Used" 27 " Not Used" 26 " Not Used" 25 " Not Used" 24 " Not Used" 23 " Not Used" 22 " Not Used" 21 " Not Used" 20 " Not Used" 19 " Not Used" 18 " Not Used" 17 " Not Used" 16 " Not Used" 15 " Not Used" 14 " Not Used" 13 " Not Used" 12 " Not Used" 11 " Not Used" 10 " Not Used" 9 " Not Used" 8 " Not Used" 7 " Not Used" 6 " Not Used" 5 " Not Used" 4 " Not Used" 3 " Not Used" 2 " Not Used" 1 " Not Used" 255 " User data not used" 0 " User data for current vehicle" ;
VAL_ 1582 RMR_MCUR 1 " Active" 0 " Inactive" ;
VAL_ 1585 ECUSPEC_AWAKE_TMF 1 " Active" 0 " Inactive" ;
VAL_ 1585 DIAGNOSTIC_AWAKE_TMF 1 " Active" 0 " Inactive" ;
VAL_ 1585 IGNITION_AWAKE_TMF 1 " Active" 0 " Inactive" ;
VAL_ 1585 NETWORK_AWAKE_TMF 1 " Active" 0 " Inactive" ;
VAL_ 1585 ECUSPEC_WAKEUP_TMF 1 " Active" 0 " Inactive" ;
VAL_ 1585 NETWORK_WAKEUP_TMF 1 " Active" 0 " Inactive" ;
VAL_ 1585 RESET_WAKEUP_TMF 1 " Active" 0 " Inactive" ;
VAL_ 1585 IGNITION_WAKEUP_TMF 1 " Active" 0 " Inactive" ;
VAL_ 1585 usrData0_TMF 254 " Not Used" 253 " Not Used" 252 " Not Used" 251 " Not Used" 250 " Not Used" 249 " Not Used" 248 " Not Used" 247 " Not Used" 246 " Not Used" 245 " Not Used" 244 " Not Used" 243 " Not Used" 242 " Not Used" 241 " Not Used" 240 " Not Used" 239 " Not Used" 238 " Not Used" 237 " Not Used" 236 " Not Used" 235 " Not Used" 234 " Not Used" 233 " Not Used" 232 " Not Used" 231 " Not Used" 230 " Not Used" 229 " Not Used" 228 " Not Used" 227 " Not Used" 226 " Not Used" 225 " Not Used" 224 " Not Used" 223 " Not Used" 222 " Not Used" 221 " Not Used" 220 " Not Used" 219 " Not Used" 218 " Not Used" 217 " Not Used" 216 " Not Used" 215 " Not Used" 214 " Not Used" 213 " Not Used" 212 " Not Used" 211 " Not Used" 210 " Not Used" 209 " Not Used" 208 " Not Used" 207 " Not Used" 206 " Not Used" 205 " Not Used" 204 " Not Used" 203 " Not Used" 202 " Not Used" 201 " Not Used" 200 " Not Used" 199 " Not Used" 198 " Not Used" 197 " Not Used" 196 " Not Used" 195 " Not Used" 194 " Not Used" 193 " Not Used" 192 " Not Used" 191 " Not Used" 190 " Not Used" 189 " Not Used" 188 " Not Used" 187 " Not Used" 186 " Not Used" 185 " Not Used" 184 " Not Used" 183 " Not Used" 182 " Not Used" 181 " Not Used" 180 " Not Used" 179 " Not Used" 178 " Not Used" 177 " Not Used" 176 " Not Used" 175 " Not Used" 174 " Not Used" 173 " Not Used" 172 " Not Used" 171 " Not Used" 170 " Not Used" 169 " Not Used" 168 " Not Used" 167 " Not Used" 166 " Not Used" 165 " Not Used" 164 " Not Used" 163 " Not Used" 162 " Not Used" 161 " Not Used" 160 " Not Used" 159 " Not Used" 158 " Not Used" 157 " Not Used" 156 " Not Used" 155 " Not Used" 154 " Not Used" 153 " Not Used" 152 " Not Used" 151 " Not Used" 150 " Not Used" 149 " Not Used" 148 " Not Used" 147 " Not Used" 146 " Not Used" 145 " Not Used" 144 " Not Used" 143 " Not Used" 142 " Not Used" 141 " Not Used" 140 " Not Used" 139 " Not Used" 138 " Not Used" 137 " Not Used" 136 " Not Used" 135 " Not Used" 134 " Not Used" 133 " Not Used" 132 " Not Used" 131 " Not Used" 130 " Not Used" 129 " Not Used" 128 " Not Used" 127 " Not Used" 126 " Not Used" 125 " Not Used" 124 " Not Used" 123 " Not Used" 122 " Not Used" 121 " Not Used" 120 " Not Used" 119 " Not Used" 118 " Not Used" 117 " Not Used" 116 " Not Used" 115 " Not Used" 114 " Not Used" 113 " Not Used" 112 " Not Used" 111 " Not Used" 110 " Not Used" 109 " Not Used" 108 " Not Used" 107 " Not Used" 106 " Not Used" 105 " Not Used" 104 " Not Used" 103 " Not Used" 102 " Not Used" 101 " Not Used" 100 " Not Used" 99 " Not Used" 98 " Not Used" 97 " Not Used" 96 " Not Used" 95 " Not Used" 94 " Not Used" 93 " Not Used" 92 " Not Used" 91 " Not Used" 90 " Not Used" 89 " Not Used" 88 " Not Used" 87 " Not Used" 86 " Not Used" 85 " Not Used" 84 " Not Used" 83 " Not Used" 82 " Not Used" 81 " Not Used" 80 " Not Used" 79 " Not Used" 78 " Not Used" 77 " Not Used" 76 " Not Used" 75 " Not Used" 74 " Not Used" 73 " Not Used" 72 " Not Used" 71 " Not Used" 70 " Not Used" 69 " Not Used" 68 " Not Used" 67 " Not Used" 66 " Not Used" 65 " Not Used" 64 " Not Used" 63 " Not Used" 62 " Not Used" 61 " Not Used" 60 " Not Used" 59 " Not Used" 58 " Not Used" 57 " Not Used" 56 " Not Used" 55 " Not Used" 54 " Not Used" 53 " Not Used" 52 " Not Used" 51 " Not Used" 50 " Not Used" 49 " Not Used" 48 " Not Used" 47 " Not Used" 46 " Not Used" 45 " Not Used" 44 " Not Used" 43 " Not Used" 42 " Not Used" 41 " Not Used" 40 " Not Used" 39 " Not Used" 38 " Not Used" 37 " Not Used" 36 " Not Used" 35 " Not Used" 34 " Not Used" 33 " Not Used" 32 " Not Used" 31 " Not Used" 30 " Not Used" 29 " Not Used" 28 " Not Used" 27 " Not Used" 26 " Not Used" 25 " Not Used" 24 " Not Used" 23 " Not Used" 22 " Not Used" 21 " Not Used" 20 " Not Used" 19 " Not Used" 18 " Not Used" 17 " Not Used" 16 " Not Used" 15 " Not Used" 14 " Not Used" 13 " Not Used" 12 " Not Used" 11 " Not Used" 10 " Not Used" 9 " Not Used" 8 " Not Used" 7 " Not Used" 6 " Not Used" 5 " Not Used" 4 " Not Used" 3 " Not Used" 2 " Not Used" 1 " Not Used" 255 " User data not used" 0 " User data for current vehicle" ;
VAL_ 1585 RMR_TMF 1 " Active" 0 " Inactive" ;
VAL_ 1580 ECUSPEC_AWAKE_ISG 1 " Active" 0 " Inactive" ;
VAL_ 1580 DIAGNOSTIC_AWAKE_ISG 1 " Active" 0 " Inactive" ;
VAL_ 1580 IGNITION_AWAKE_ISG 1 " Active" 0 " Inactive" ;
VAL_ 1580 NETWORK_AWAKE_ISG 1 " Active" 0 " Inactive" ;
VAL_ 1580 ECUSPEC_WAKEUP_ISG 1 " Active" 0 " Inactive" ;
VAL_ 1580 NETWORK_WAKEUP_ISG 1 " Active" 0 " Inactive" ;
VAL_ 1580 RESET_WAKEUP_ISG 1 " Active" 0 " Inactive" ;
VAL_ 1580 IGNITION_WAKEUP_ISG 1 " Active" 0 " Inactive" ;
VAL_ 1580 usrData0_ISG 254 " Not Used" 253 " Not Used" 252 " Not Used" 251 " Not Used" 250 " Not Used" 249 " Not Used" 248 " Not Used" 247 " Not Used" 246 " Not Used" 245 " Not Used" 244 " Not Used" 243 " Not Used" 242 " Not Used" 241 " Not Used" 240 " Not Used" 239 " Not Used" 238 " Not Used" 237 " Not Used" 236 " Not Used" 235 " Not Used" 234 " Not Used" 233 " Not Used" 232 " Not Used" 231 " Not Used" 230 " Not Used" 229 " Not Used" 228 " Not Used" 227 " Not Used" 226 " Not Used" 225 " Not Used" 224 " Not Used" 223 " Not Used" 222 " Not Used" 221 " Not Used" 220 " Not Used" 219 " Not Used" 218 " Not Used" 217 " Not Used" 216 " Not Used" 215 " Not Used" 214 " Not Used" 213 " Not Used" 212 " Not Used" 211 " Not Used" 210 " Not Used" 209 " Not Used" 208 " Not Used" 207 " Not Used" 206 " Not Used" 205 " Not Used" 204 " Not Used" 203 " Not Used" 202 " Not Used" 201 " Not Used" 200 " Not Used" 199 " Not Used" 198 " Not Used" 197 " Not Used" 196 " Not Used" 195 " Not Used" 194 " Not Used" 193 " Not Used" 192 " Not Used" 191 " Not Used" 190 " Not Used" 189 " Not Used" 188 " Not Used" 187 " Not Used" 186 " Not Used" 185 " Not Used" 184 " Not Used" 183 " Not Used" 182 " Not Used" 181 " Not Used" 180 " Not Used" 179 " Not Used" 178 " Not Used" 177 " Not Used" 176 " Not Used" 175 " Not Used" 174 " Not Used" 173 " Not Used" 172 " Not Used" 171 " Not Used" 170 " Not Used" 169 " Not Used" 168 " Not Used" 167 " Not Used" 166 " Not Used" 165 " Not Used" 164 " Not Used" 163 " Not Used" 162 " Not Used" 161 " Not Used" 160 " Not Used" 159 " Not Used" 158 " Not Used" 157 " Not Used" 156 " Not Used" 155 " Not Used" 154 " Not Used" 153 " Not Used" 152 " Not Used" 151 " Not Used" 150 " Not Used" 149 " Not Used" 148 " Not Used" 147 " Not Used" 146 " Not Used" 145 " Not Used" 144 " Not Used" 143 " Not Used" 142 " Not Used" 141 " Not Used" 140 " Not Used" 139 " Not Used" 138 " Not Used" 137 " Not Used" 136 " Not Used" 135 " Not Used" 134 " Not Used" 133 " Not Used" 132 " Not Used" 131 " Not Used" 130 " Not Used" 129 " Not Used" 128 " Not Used" 127 " Not Used" 126 " Not Used" 125 " Not Used" 124 " Not Used" 123 " Not Used" 122 " Not Used" 121 " Not Used" 120 " Not Used" 119 " Not Used" 118 " Not Used" 117 " Not Used" 116 " Not Used" 115 " Not Used" 114 " Not Used" 113 " Not Used" 112 " Not Used" 111 " Not Used" 110 " Not Used" 109 " Not Used" 108 " Not Used" 107 " Not Used" 106 " Not Used" 105 " Not Used" 104 " Not Used" 103 " Not Used" 102 " Not Used" 101 " Not Used" 100 " Not Used" 99 " Not Used" 98 " Not Used" 97 " Not Used" 96 " Not Used" 95 " Not Used" 94 " Not Used" 93 " Not Used" 92 " Not Used" 91 " Not Used" 90 " Not Used" 89 " Not Used" 88 " Not Used" 87 " Not Used" 86 " Not Used" 85 " Not Used" 84 " Not Used" 83 " Not Used" 82 " Not Used" 81 " Not Used" 80 " Not Used" 79 " Not Used" 78 " Not Used" 77 " Not Used" 76 " Not Used" 75 " Not Used" 74 " Not Used" 73 " Not Used" 72 " Not Used" 71 " Not Used" 70 " Not Used" 69 " Not Used" 68 " Not Used" 67 " Not Used" 66 " Not Used" 65 " Not Used" 64 " Not Used" 63 " Not Used" 62 " Not Used" 61 " Not Used" 60 " Not Used" 59 " Not Used" 58 " Not Used" 57 " Not Used" 56 " Not Used" 55 " Not Used" 54 " Not Used" 53 " Not Used" 52 " Not Used" 51 " Not Used" 50 " Not Used" 49 " Not Used" 48 " Not Used" 47 " Not Used" 46 " Not Used" 45 " Not Used" 44 " Not Used" 43 " Not Used" 42 " Not Used" 41 " Not Used" 40 " Not Used" 39 " Not Used" 38 " Not Used" 37 " Not Used" 36 " Not Used" 35 " Not Used" 34 " Not Used" 33 " Not Used" 32 " Not Used" 31 " Not Used" 30 " Not Used" 29 " Not Used" 28 " Not Used" 27 " Not Used" 26 " Not Used" 25 " Not Used" 24 " Not Used" 23 " Not Used" 22 " Not Used" 21 " Not Used" 20 " Not Used" 19 " Not Used" 18 " Not Used" 17 " Not Used" 16 " Not Used" 15 " Not Used" 14 " Not Used" 13 " Not Used" 12 " Not Used" 11 " Not Used" 10 " Not Used" 9 " Not Used" 8 " Not Used" 7 " Not Used" 6 " Not Used" 5 " Not Used" 4 " Not Used" 3 " Not Used" 2 " Not Used" 1 " Not Used" 255 " User data not used" 0 " User data for current vehicle" ;
VAL_ 1580 RMR_ISG 1 " Active" 0 " Inactive" ;
VAL_ 1551 ECUSPEC_AWAKE_BMS 1 " Active" 0 " Inactive" ;
VAL_ 1551 DIAGNOSTIC_AWAKE_BMS 1 " Active" 0 " Inactive" ;
VAL_ 1551 IGNITION_AWAKE_BMS 1 " Active" 0 " Inactive" ;
VAL_ 1551 NETWORK_AWAKE_BMS 1 " Active" 0 " Inactive" ;
VAL_ 1551 ECUSPEC_WAKEUP_BMS 1 " Active" 0 " Inactive" ;
VAL_ 1551 NETWORK_WAKEUP_BMS 1 " Active" 0 " Inactive" ;
VAL_ 1551 RESET_WAKEUP_BMS 1 " Active" 0 " Inactive" ;
VAL_ 1551 IGNITION_WAKEUP_BMS 1 " Active" 0 " Inactive" ;
VAL_ 1551 usrData0_BMS 254 " Not Used" 253 " Not Used" 252 " Not Used" 251 " Not Used" 250 " Not Used" 249 " Not Used" 248 " Not Used" 247 " Not Used" 246 " Not Used" 245 " Not Used" 244 " Not Used" 243 " Not Used" 242 " Not Used" 241 " Not Used" 240 " Not Used" 239 " Not Used" 238 " Not Used" 237 " Not Used" 236 " Not Used" 235 " Not Used" 234 " Not Used" 233 " Not Used" 232 " Not Used" 231 " Not Used" 230 " Not Used" 229 " Not Used" 228 " Not Used" 227 " Not Used" 226 " Not Used" 225 " Not Used" 224 " Not Used" 223 " Not Used" 222 " Not Used" 221 " Not Used" 220 " Not Used" 219 " Not Used" 218 " Not Used" 217 " Not Used" 216 " Not Used" 215 " Not Used" 214 " Not Used" 213 " Not Used" 212 " Not Used" 211 " Not Used" 210 " Not Used" 209 " Not Used" 208 " Not Used" 207 " Not Used" 206 " Not Used" 205 " Not Used" 204 " Not Used" 203 " Not Used" 202 " Not Used" 201 " Not Used" 200 " Not Used" 199 " Not Used" 198 " Not Used" 197 " Not Used" 196 " Not Used" 195 " Not Used" 194 " Not Used" 193 " Not Used" 192 " Not Used" 191 " Not Used" 190 " Not Used" 189 " Not Used" 188 " Not Used" 187 " Not Used" 186 " Not Used" 185 " Not Used" 184 " Not Used" 183 " Not Used" 182 " Not Used" 181 " Not Used" 180 " Not Used" 179 " Not Used" 178 " Not Used" 177 " Not Used" 176 " Not Used" 175 " Not Used" 174 " Not Used" 173 " Not Used" 172 " Not Used" 171 " Not Used" 170 " Not Used" 169 " Not Used" 168 " Not Used" 167 " Not Used" 166 " Not Used" 165 " Not Used" 164 " Not Used" 163 " Not Used" 162 " Not Used" 161 " Not Used" 160 " Not Used" 159 " Not Used" 158 " Not Used" 157 " Not Used" 156 " Not Used" 155 " Not Used" 154 " Not Used" 153 " Not Used" 152 " Not Used" 151 " Not Used" 150 " Not Used" 149 " Not Used" 148 " Not Used" 147 " Not Used" 146 " Not Used" 145 " Not Used" 144 " Not Used" 143 " Not Used" 142 " Not Used" 141 " Not Used" 140 " Not Used" 139 " Not Used" 138 " Not Used" 137 " Not Used" 136 " Not Used" 135 " Not Used" 134 " Not Used" 133 " Not Used" 132 " Not Used" 131 " Not Used" 130 " Not Used" 129 " Not Used" 128 " Not Used" 127 " Not Used" 126 " Not Used" 125 " Not Used" 124 " Not Used" 123 " Not Used" 122 " Not Used" 121 " Not Used" 120 " Not Used" 119 " Not Used" 118 " Not Used" 117 " Not Used" 116 " Not Used" 115 " Not Used" 114 " Not Used" 113 " Not Used" 112 " Not Used" 111 " Not Used" 110 " Not Used" 109 " Not Used" 108 " Not Used" 107 " Not Used" 106 " Not Used" 105 " Not Used" 104 " Not Used" 103 " Not Used" 102 " Not Used" 101 " Not Used" 100 " Not Used" 99 " Not Used" 98 " Not Used" 97 " Not Used" 96 " Not Used" 95 " Not Used" 94 " Not Used" 93 " Not Used" 92 " Not Used" 91 " Not Used" 90 " Not Used" 89 " Not Used" 88 " Not Used" 87 " Not Used" 86 " Not Used" 85 " Not Used" 84 " Not Used" 83 " Not Used" 82 " Not Used" 81 " Not Used" 80 " Not Used" 79 " Not Used" 78 " Not Used" 77 " Not Used" 76 " Not Used" 75 " Not Used" 74 " Not Used" 73 " Not Used" 72 " Not Used" 71 " Not Used" 70 " Not Used" 69 " Not Used" 68 " Not Used" 67 " Not Used" 66 " Not Used" 65 " Not Used" 64 " Not Used" 63 " Not Used" 62 " Not Used" 61 " Not Used" 60 " Not Used" 59 " Not Used" 58 " Not Used" 57 " Not Used" 56 " Not Used" 55 " Not Used" 54 " Not Used" 53 " Not Used" 52 " Not Used" 51 " Not Used" 50 " Not Used" 49 " Not Used" 48 " Not Used" 47 " Not Used" 46 " Not Used" 45 " Not Used" 44 " Not Used" 43 " Not Used" 42 " Not Used" 41 " Not Used" 40 " Not Used" 39 " Not Used" 38 " Not Used" 37 " Not Used" 36 " Not Used" 35 " Not Used" 34 " Not Used" 33 " Not Used" 32 " Not Used" 31 " Not Used" 30 " Not Used" 29 " Not Used" 28 " Not Used" 27 " Not Used" 26 " Not Used" 25 " Not Used" 24 " Not Used" 23 " Not Used" 22 " Not Used" 21 " Not Used" 20 " Not Used" 19 " Not Used" 18 " Not Used" 17 " Not Used" 16 " Not Used" 15 " Not Used" 14 " Not Used" 13 " Not Used" 12 " Not Used" 11 " Not Used" 10 " Not Used" 9 " Not Used" 8 " Not Used" 7 " Not Used" 6 " Not Used" 5 " Not Used" 4 " Not Used" 3 " Not Used" 2 " Not Used" 1 " Not Used" 255 " User data not used" 0 " User data for current vehicle" ;
VAL_ 1551 RMR_BMS 1 " Active" 0 " Inactive" ;
VAL_ 1550 ECUSPEC_AWAKE_HCU 1 " Active" 0 " Inactive" ;
VAL_ 1550 DIAGNOSTIC_AWAKE_HCU 1 " Active" 0 " Inactive" ;
VAL_ 1550 IGNITION_AWAKE_HCU 1 " Active" 0 " Inactive" ;
VAL_ 1550 NETWORK_AWAKE_HCU 1 " Active" 0 " Inactive" ;
VAL_ 1550 ECUSPEC_WAKEUP_HCU 1 " Active" 0 " Inactive" ;
VAL_ 1550 NETWORK_WAKEUP_HCU 1 " Active" 0 " Inactive" ;
VAL_ 1550 RESET_WAKEUP_HCU 1 " Active" 0 " Inactive" ;
VAL_ 1550 IGNITION_WAKEUP_HCU 1 " Active" 0 " Inactive" ;
VAL_ 1550 usrData0_HCU 254 " Not Used" 253 " Not Used" 252 " Not Used" 251 " Not Used" 250 " Not Used" 249 " Not Used" 248 " Not Used" 247 " Not Used" 246 " Not Used" 245 " Not Used" 244 " Not Used" 243 " Not Used" 242 " Not Used" 241 " Not Used" 240 " Not Used" 239 " Not Used" 238 " Not Used" 237 " Not Used" 236 " Not Used" 235 " Not Used" 234 " Not Used" 233 " Not Used" 232 " Not Used" 231 " Not Used" 230 " Not Used" 229 " Not Used" 228 " Not Used" 227 " Not Used" 226 " Not Used" 225 " Not Used" 224 " Not Used" 223 " Not Used" 222 " Not Used" 221 " Not Used" 220 " Not Used" 219 " Not Used" 218 " Not Used" 217 " Not Used" 216 " Not Used" 215 " Not Used" 214 " Not Used" 213 " Not Used" 212 " Not Used" 211 " Not Used" 210 " Not Used" 209 " Not Used" 208 " Not Used" 207 " Not Used" 206 " Not Used" 205 " Not Used" 204 " Not Used" 203 " Not Used" 202 " Not Used" 201 " Not Used" 200 " Not Used" 199 " Not Used" 198 " Not Used" 197 " Not Used" 196 " Not Used" 195 " Not Used" 194 " Not Used" 193 " Not Used" 192 " Not Used" 191 " Not Used" 190 " Not Used" 189 " Not Used" 188 " Not Used" 187 " Not Used" 186 " Not Used" 185 " Not Used" 184 " Not Used" 183 " Not Used" 182 " Not Used" 181 " Not Used" 180 " Not Used" 179 " Not Used" 178 " Not Used" 177 " Not Used" 176 " Not Used" 175 " Not Used" 174 " Not Used" 173 " Not Used" 172 " Not Used" 171 " Not Used" 170 " Not Used" 169 " Not Used" 168 " Not Used" 167 " Not Used" 166 " Not Used" 165 " Not Used" 164 " Not Used" 163 " Not Used" 162 " Not Used" 161 " Not Used" 160 " Not Used" 159 " Not Used" 158 " Not Used" 157 " Not Used" 156 " Not Used" 155 " Not Used" 154 " Not Used" 153 " Not Used" 152 " Not Used" 151 " Not Used" 150 " Not Used" 149 " Not Used" 148 " Not Used" 147 " Not Used" 146 " Not Used" 145 " Not Used" 144 " Not Used" 143 " Not Used" 142 " Not Used" 141 " Not Used" 140 " Not Used" 139 " Not Used" 138 " Not Used" 137 " Not Used" 136 " Not Used" 135 " Not Used" 134 " Not Used" 133 " Not Used" 132 " Not Used" 131 " Not Used" 130 " Not Used" 129 " Not Used" 128 " Not Used" 127 " Not Used" 126 " Not Used" 125 " Not Used" 124 " Not Used" 123 " Not Used" 122 " Not Used" 121 " Not Used" 120 " Not Used" 119 " Not Used" 118 " Not Used" 117 " Not Used" 116 " Not Used" 115 " Not Used" 114 " Not Used" 113 " Not Used" 112 " Not Used" 111 " Not Used" 110 " Not Used" 109 " Not Used" 108 " Not Used" 107 " Not Used" 106 " Not Used" 105 " Not Used" 104 " Not Used" 103 " Not Used" 102 " Not Used" 101 " Not Used" 100 " Not Used" 99 " Not Used" 98 " Not Used" 97 " Not Used" 96 " Not Used" 95 " Not Used" 94 " Not Used" 93 " Not Used" 92 " Not Used" 91 " Not Used" 90 " Not Used" 89 " Not Used" 88 " Not Used" 87 " Not Used" 86 " Not Used" 85 " Not Used" 84 " Not Used" 83 " Not Used" 82 " Not Used" 81 " Not Used" 80 " Not Used" 79 " Not Used" 78 " Not Used" 77 " Not Used" 76 " Not Used" 75 " Not Used" 74 " Not Used" 73 " Not Used" 72 " Not Used" 71 " Not Used" 70 " Not Used" 69 " Not Used" 68 " Not Used" 67 " Not Used" 66 " Not Used" 65 " Not Used" 64 " Not Used" 63 " Not Used" 62 " Not Used" 61 " Not Used" 60 " Not Used" 59 " Not Used" 58 " Not Used" 57 " Not Used" 56 " Not Used" 55 " Not Used" 54 " Not Used" 53 " Not Used" 52 " Not Used" 51 " Not Used" 50 " Not Used" 49 " Not Used" 48 " Not Used" 47 " Not Used" 46 " Not Used" 45 " Not Used" 44 " Not Used" 43 " Not Used" 42 " Not Used" 41 " Not Used" 40 " Not Used" 39 " Not Used" 38 " Not Used" 37 " Not Used" 36 " Not Used" 35 " Not Used" 34 " Not Used" 33 " Not Used" 32 " Not Used" 31 " Not Used" 30 " Not Used" 29 " Not Used" 28 " Not Used" 27 " Not Used" 26 " Not Used" 25 " Not Used" 24 " Not Used" 23 " Not Used" 22 " Not Used" 21 " Not Used" 20 " Not Used" 19 " Not Used" 18 " Not Used" 17 " Not Used" 16 " Not Used" 15 " Not Used" 14 " Not Used" 13 " Not Used" 12 " Not Used" 11 " Not Used" 10 " Not Used" 9 " Not Used" 8 " Not Used" 7 " Not Used" 6 " Not Used" 5 " Not Used" 4 " Not Used" 3 " Not Used" 2 " Not Used" 1 " Not Used" 255 " User data not used" 0 " User data for current vehicle" ;
VAL_ 1550 RMR_HCU 1 " Active" 0 " Inactive" ;
VAL_ 1183 BMSH_PosSideWeldSts 1 " Welded" 0 " No welded" ;
VAL_ 1183 BMSH_InsulationSts 3 " Invalid" 2 " Insulation Error" 1 " Insulation Warning" 0 " Insulation OK ??default??" ;
VAL_ 1183 BMSH_InterHVILSts 3 "Reserved" 2 "Reserved" 1 "Manfunciton" 0 "Normal" ;
VAL_ 1183 BMSH_stMode 15 " Reserved" 14 " Reserved" 13 " Reserved" 12 " Reserved" 11 " Reserved" 10 " Reserved" 9 "Fault" 8 "Emergeny Discharge" 7 "Service" 6 "Afterrun" 5 "Powerdown" 4 "Charge" 3 "Operational" 2 "Precharge" 1 "Standby" 0 "INIT" ;
VAL_ 1450 BMSH_BalanceActive 1 " Active" 0 " normal" ;
VAL_ 1450 BMSH_Battery_Uniformity 1 " Fault" 0 " Normal" ;
VAL_ 1450 BMSH_StoredEnergySys 1 " Fault" 0 " Normal" ;
VAL_ 1450 BMSH_Charge_Over 1 " Fault" 0 " Normal" ;
VAL_ 1450 BMSH_HVILcuitFailure 1 " Fault" 0 " Normal" ;
VAL_ 1450 BMSH_Battery_Mismatching 1 " Fault" 0 " Normal" ;
VAL_ 1450 BMSH_BatteryTempLightSts 3 "Not used" 2 "Low" 1 "High" 0 "OFF" ;
VAL_ 1450 BMSH_Charge_Over_Current 3 "Error" 2 "Alarm" 1 "Warming" 0 "Normal" ;
VAL_ 1450 BMSH_Discharge_Over_Current 3 "Error" 2 "Alarm" 1 "Warming" 0 "Normal" ;
VAL_ 1450 BMSH_IsocircuitFailure 3 "Alarm" 2 "Reserved" 1 "Warning" 0 "No Warning " ;
VAL_ 1450 BMSH_Cell_Voltage_Uniformity 3 "Faut Level III" 2 "Faut Level II" 1 "Faut Level I" 0 "Normal" ;
VAL_ 1450 BMSH_LowSOC 3 " Alarm" 2 " Reserved" 1 " Warning" 0 " No Warning" ;
VAL_ 1450 BMSH_CellUnderVol 3 " Fault Level III" 2 " Fault Level II" 1 " Fault Level I" 0 " Normal" ;
VAL_ 1450 BMSH_CellOverVol 3 " Fault Level III" 2 " Fault Level II" 1 " Fault Level I" 0 " Normal" ;
VAL_ 1450 BMSH_OverSOC 3 "Faut Level III" 2 "Faut Level II" 1 "Faut Level I" 0 "Normal" ;
VAL_ 1450 BMSH_Battery_Under_Voltage 3 " Fault Level III" 2 " Fault Level II" 1 " Fault Level I" 0 " Normal" ;
VAL_ 1450 BMSH_Battery_Over_Voltage 3 " Fault Level III" 2 " Fault Level II" 1 " Fault Level I" 0 " Normal" ;
VAL_ 1450 BMSH_Low_Temperature 3 " Fault Level III" 2 " Fault Level II" 1 " Fault Level I" 0 " Normal" ;
VAL_ 1450 BMSH_Over_Temperature 3 " Fault Level III" 2 " Fault Level II" 1 " Fault Level I" 0 " Normal" ;
VAL_ 1450 BMSH_SOC_Jump 1 " Fault" 0 " Normal" ;
VAL_ 1450 BMSH_TempUniformity 1 " Fault" 0 " Normal" ;
VAL_ 1436 BMSH_BattTypeCode 255 "other" 252 "fuel cell" 7 "Lithium titanate battery" 6 "super capacitor" 5 "Polymer Lithium Ion Battery" 4 "Ternary material battery" 3 "Lithium cobalt battery" 2 "Lithium manganate battery" 1 "lithium iron phosphate battery" 0 "Reserved" ;
VAL_ 1096 BMSH_ChargeEnable 0 "disable                                          0x1:enable" ;
VAL_ 1096 BMSH_BatteryMaintainLightReq 1 "Maintain request" 0 "No request" ;
VAL_ 1096 BMSH_ChargeReq 1 "Request" 0 "No Request" ;
VAL_ 1096 BMS_BattWarmRequest 1 "Request" 0 "No request" ;
VAL_ 1091 BMSH_OutletWaterTempValid 1 " Not Valid" 0 " Valid" ;
VAL_ 1091 BMSH_InletWaterTempValid 1 " Not Valid" 0 " Valid" ;
VAL_ 1091 BMSH_PackThermalSensorSts 3 " all error" 2 " outlet sensor error" 1 " inlet sensor error" 0 " normal" ;
VAL_ 1091 BMSH_ThermalManageReq 3 " Balance temperature Request" 2 " Cooling" 1 " Heating" 0 " default/no request" ;
VAL_ 1083 BMSH_PackFaultLevel 7 "Reserved" 6 "Reserved" 5 "Reserved" 4 "Emergency shutdown" 3 "Shutdown" 2 "Derating" 1 "Alarm" 0 "No Fault" ;
VAL_ 1083 BMSH_MILReq 1 "Active" 0 "Inactive" ;
VAL_ 1083 BMSH_BattFaultLampSts 1 "Lamp ON" 0 "Lamp OFF" ;
VAL_ 1083 BMSH_PackThermalRunawayLight 1 "Lamp ON" 0 "Lamp OFF" ;
VAL_ 1083 BMSH_DisChgFaultLevel 15 " Reserved" 14 " Reserved" 13 " Reserved" 12 " Reserved" 11 " Reserved" 10 " Reserved" 9 " Reserved" 8 " Reserved" 7 " Reserved" 6 " EmShutdown??????????" 5 " Shutdown(???????" 4 " Reserved" 3 " Derate power" 2 " Warning" 1 " Normal" 0 " Default" ;
VAL_ 1083 BMSH_ChgFaultLevel 15 " Reserved" 14 " Reserved" 13 " Reserved" 12 " Reserved" 11 " Reserved" 10 " Reserved" 9 " Reserved" 8 " Reserved" 7 " Reserved" 6 " EmShutdown??????????" 5 " Shutdown(???????" 4 " Reserved" 3 " Derate power" 2 " Warning" 1 " Normal" 0 " Default" ;
VAL_ 420 BMSH_MainPrechgResistanceSts 1 "broken" 0 "normal" ;
VAL_ 420 BMSH_PTCFuseSts 1 "broken" 0 "normal" ;
VAL_ 420 BMSH_RmcuFuseSts 1 "broken" 0 "normal" ;
VAL_ 420 BMSH_FmcuFuseSts 1 "broken" 0 "normal" ;
VAL_ 411 BMSH_BookSetReq 1 "Request" 0 "No Request" ;
VAL_ 411 BMSH_PTCRelayWeldSts 1 " Welded" 0 " No welded" ;
VAL_ 411 BMSH_CHGPrechargeWeldSts 1 " Welded" 0 " No welded" ;
VAL_ 411 BMSH_PreChargeWeldSts 1 " Welded" 0 " No welded" ;
VAL_ 411 BMSH_NegSideWeldSts 1 " Welded" 0 " No welded" ;
VAL_ 411 BMSH_PosSideWeldSts 1 " Welded" 0 " No welded" ;
VAL_ 411 BMSH_PTCRelaySts 1 " Closed" 0 " Open" ;
VAL_ 411 BMSH_CHGPrechargeRelaySts 1 " Closed" 0 " Open" ;
VAL_ 411 BMSH_PrechargeRelaySts 1 " Closed" 0 " Open" ;
VAL_ 411 BMSH_NegMainRelaySts 1 " Closed" 0 " Open" ;
VAL_ 411 BMSH_PosMainRelaySts 1 " Closed" 0 " Open" ;
VAL_ 411 BMSH_IntelligentChargeReq 1 " request" 0 " no request(default)" ;
VAL_ 411 BMSH_OBCPrechgSt 7 " Reserved" 6 " Reserved" 5 " Reserved" 4 " Precharge Locked" 3 " Precharge Failue" 2 " Prechgarge Suceed" 1 " Precharging" 0 " Default" ;
VAL_ 411 BMSH_MainPrechgSt 7 " Reserved" 6 " Reserved" 5 " Reserved" 4 " Precharge Locked" 3 " Precharge Failue" 2 " Prechgarge Suceed" 1 " Precharging" 0 " Default" ;
VAL_ 411 BMSH_InsulationSts 3 " Invalid" 2 " Insulation Error" 1 " Insulation Warning" 0 " Insulation OK ??default??" ;
VAL_ 411 BMSH_VehicleHVILSts 3 "Reserved" 2 "Reserved" 1 "Manfunciton" 0 "Normal" ;
VAL_ 411 BMSH_InterHVILSts 3 "Reserved" 2 "Reserved" 1 "Manfunciton" 0 "Normal" ;
VAL_ 411 BMSH_stMode 15 " Reserved" 14 " Reserved" 13 " Reserved" 12 " Reserved" 11 " Reserved" 10 " Reserved" 9 "Fault" 8 "Emergeny Discharge" 7 "Service" 6 "Afterrun" 5 "Powerdown" 4 "Charge" 3 "Operational" 2 "Precharge" 1 "Standby" 0 "INIT" ;
VAL_ 403 BMSH_WorkingMode 3 " Reserved" 2 " Reserved" 1 " Sleep mode" 0 " Running mode " ;
VAL_ 1084 OBC_ChargeSourceMode 2 "constant current                                                              0x3:Reserved" 0 "none                                                              0x1:constant voltage" ;
VAL_ 1067 OBC_WorkingMode 7 " Reserved" 6 " WORKSTATE_OBC_OFF" 5 " WORKSTATE_OBC_STOPPING" 4 " WORKSTATE_OBC_FAULT " 3 " WORKSTATE_OBC_HEAT" 2 " WORKSTATE_OBC_CHARGE" 1 " WORKSTATE_OBC_STANDBY" 0 " WORKSTATE_OBC_INIT" ;
VAL_ 1067 OBC_ElectronicLockSts 0 "Unlock                                                                      0x1:Lock" ;
VAL_ 1067 OBC_CC_ConnectSts 0 "Not connected                                      0x1:Connected                                                            0x2:Partial connected                                            0x3:Reserved" ;
VAL_ 1067 OBC_CP_DutyCycleFault 0 "No fault                                                                                     0x1:Fault" ;
VAL_ 1064 OBC_KL30_UnderVolt 0 "No fault                                                                                     0x1:Fault" ;
VAL_ 1061 OBC_FaultLevelSts 0 "No fault                                                               0x1:Lever1 fault                                                        0x2:Lever2 fault                                                              0x3:Lever3 fault                                                     0x4:Reserved                                                            0x5:Reserved                                                  0x6:Reserved                                                       0x7:Reserved" ;
VAL_ 1061 OBC_ChgSts 3 "Charge stop                                               0x4:Reserved                                                      0x5:Reserved                                                        0x6:Reserved                                                  0x7:Reserved" 0 "No charge                                                                                                                       0x1:Charging                                                                 0x2:Chargefinished" ;
VAL_ 371 TMR_State 15 " reserved" 14 " reserved" 13 " reserved" 12 " reserved" 11 "Service(Reserved)" 10 "Off(Reserved)" 9 "Failure" 8 "Afterrun(Reserved)" 7 "Powerdown (Discharge)" 6 "Offset Calibration" 5 "Spd Control(Reserved)" 4 "Volt Control(Reserved)" 3 "Tq Control" 2 "HV Standby (Disable)" 1 "LV Standby (Precharge)" 0 "INIT (Initialization)" ;
VAL_ 348 TMF_ModeSt 15 " reserved" 14 " reserved" 13 " reserved" 12 " reserved" 11 "Service" 10 "Off" 9 "Failure" 8 "Afterrun" 7 "Powerdown (Discharge)" 6 "Offset Calibration" 5 "Spd Control" 4 "Volt Control" 3 "Tq Control" 2 "HV Standby (Disable)" 1 "LV Standby (Precharge)" 0 "INIT (Initialization)" ;
VAL_ 326 ISGF_ModeSt 15 " reserved" 14 " reserved" 13 " reserved" 12 " reserved" 11 "Service" 10 "Off" 9 "Failure" 8 "Afterrun" 7 "Powerdown (Discharge)" 6 "Offset Calibration" 5 "Spd Control" 4 "Volt Control" 3 "Tq Control" 2 "HV Standby (Disable)" 1 "LV Standby (Precharge)" 0 "INIT (Initialization)" ;
VAL_ 264 HCU_BattHeatAllow 1 "Request" 0 "NO Request " ;
VAL_ 264 HCU_VehicleAllowToCharge 1 " Allowed" 0 " Not Allowed" ;
VAL_ 264 HCU_BMS_stModeReq 7 "Reserved" 6 "Reserved" 5 "Reserved" 4 "Emergeny Discharge" 3 "Powerdown" 2 "Charge" 1 "Operational" 0 "Standby" ;
VAL_ 264 HCU_BattHVHAllow 1 " Allowed" 0 " Not Allowed" ;
